VERSION ""

NS_ :

BS_:

BU_: Vector__XXX

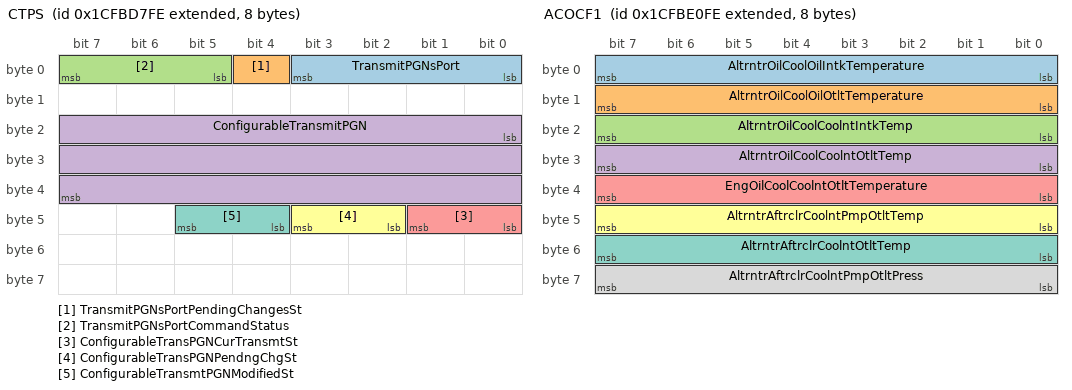
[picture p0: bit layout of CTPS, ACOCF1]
BO_ 2633750526 CTPS: 8 Vector__XXX
SG_ TransmitPGNsPort : 0|4@1+ (1,0) [0|15] "" Vector__XXX
SG_ TransmitPGNsPortPendingChangesSt : 4|1@1+ (1,0) [0|1] "" Vector__XXX
SG_ TransmitPGNsPortCommandStatus : 5|3@1+ (1,0) [0|7] "" Vector__XXX
SG_ ConfigurableTransmitPGN : 16|24@1+ (1,0) [0|16777215] "" Vector__XXX
SG_ ConfigurableTransPGNCurTransmtSt : 40|2@1+ (1,0) [0|3] "" Vector__XXX
SG_ ConfigurableTransPGNPendngChgSt : 42|2@1+ (1,0) [0|3] "" Vector__XXX
SG_ ConfigurableTransmtPGNModifiedSt : 44|2@1+ (1,0) [0|3] "" Vector__XXX

BO_ 2365315326 DCDC1T: 8 Vector__XXX
SG_ DCDC1ConverterTemperature : 0|8@1+ (1,-40) [-40|210] "deg C" Vector__XXX
SG_ DCDC1CnvElctrncFilterTemperature : 8|8@1+ (1,-40) [-40|210] "deg C" Vector__XXX
SG_ DCDC1PowerElectronicsTemperature : 16|8@1+ (1,-40) [-40|210] "deg C" Vector__XXX
SG_ DCDC1CoolantInTemperature : 24|8@1+ (1,-40) [-40|210] "deg C" Vector__XXX
SG_ DCDC1CoolantOutTemperature : 32|8@1+ (1,-40) [-40|210] "deg C" Vector__XXX

BO_ 2365315582 DCDC1LL: 8 Vector__XXX
SG_ DCDC1LowSideVoltageMinLmtRequest : 0|16@1+ (0.01,0) [0|642.55] "V" Vector__XXX
SG_ DCDC1LowSideVoltageMaxLmtRequest : 16|16@1+ (0.01,0) [0|642.55] "V" Vector__XXX
SG_ DCDC1LowSideCurrMaxLmtRequest : 32|16@1+ (0.05,0) [0|3212.75] "A" Vector__XXX

BO_ 2365315838 DCDC1HL: 8 Vector__XXX
SG_ DCDC1HghSideVoltageMinLmtRequest : 0|16@1+ (0.05,0) [0|3212.75] "V" Vector__XXX
SG_ DCDC1HghSideVoltageMaxLmtRequest : 16|16@1+ (0.05,0) [0|3212.75] "V" Vector__XXX
SG_ DCDC1HghSideCurrMaxLmtRequest : 32|16@1+ (0.05,0) [0|3212.75] "A" Vector__XXX

BO_ 2566642686 DM58: 0 Vector__XXX

BO_ 2566642942 DC4: 8 Vector__XXX
SG_ LockStatusOfDoor21 : 0|2@1+ (1,0) [0|3] "" Vector__XXX
SG_ OpenStatusOfDoor21 : 2|2@1+ (1,0) [0|3] "" Vector__XXX
SG_ EnableStatusOfDoor21 : 4|2@1+ (1,0) [0|3] "" Vector__XXX
SG_ LockStatusOfDoor22 : 6|2@1+ (1,0) [0|3] "" Vector__XXX
SG_ OpenStatusOfDoor22 : 8|2@1+ (1,0) [0|3] "" Vector__XXX
SG_ EnableStatusOfDoor22 : 10|2@1+ (1,0) [0|3] "" Vector__XXX
SG_ LockStatusOfDoor23 : 12|2@1+ (1,0) [0|3] "" Vector__XXX
SG_ OpenStatusOfDoor23 : 14|2@1+ (1,0) [0|3] "" Vector__XXX
SG_ EnableStatusOfDoor23 : 16|2@1+ (1,0) [0|3] "" Vector__XXX
SG_ LockStatusOfDoor24 : 18|2@1+ (1,0) [0|3] "" Vector__XXX
SG_ OpenStatusOfDoor24 : 20|2@1+ (1,0) [0|3] "" Vector__XXX
SG_ EnableStatusOfDoor24 : 22|2@1+ (1,0) [0|3] "" Vector__XXX
SG_ LockStatusOfDoor25 : 24|2@1+ (1,0) [0|3] "" Vector__XXX
SG_ OpenStatusOfDoor25 : 26|2@1+ (1,0) [0|3] "" Vector__XXX
SG_ EnableStatusOfDoor25 : 28|2@1+ (1,0) [0|3] "" Vector__XXX
SG_ LockStatusOfDoor26 : 30|2@1+ (1,0) [0|3] "" Vector__XXX
SG_ OpenStatusOfDoor26 : 32|2@1+ (1,0) [0|3] "" Vector__XXX
SG_ EnableStatusOfDoor26 : 34|2@1+ (1,0) [0|3] "" Vector__XXX
SG_ LockStatusOfDoor27 : 36|2@1+ (1,0) [0|3] "" Vector__XXX
SG_ OpenStatusOfDoor27 : 38|2@1+ (1,0) [0|3] "" Vector__XXX
SG_ EnableStatusOfDoor27 : 40|2@1+ (1,0) [0|3] "" Vector__XXX
SG_ LockStatusOfDoor28 : 42|2@1+ (1,0) [0|3] "" Vector__XXX
SG_ OpenStatusOfDoor28 : 44|2@1+ (1,0) [0|3] "" Vector__XXX
SG_ EnableStatusOfDoor28 : 46|2@1+ (1,0) [0|3] "" Vector__XXX
SG_ LockStatusOfDoor29 : 48|2@1+ (1,0) [0|3] "" Vector__XXX
SG_ OpenStatusOfDoor29 : 50|2@1+ (1,0) [0|3] "" Vector__XXX
SG_ EnableStatusOfDoor29 : 52|2@1+ (1,0) [0|3] "" Vector__XXX
SG_ LockStatusOfDoor30 : 54|2@1+ (1,0) [0|3] "" Vector__XXX
SG_ OpenStatusOfDoor30 : 56|2@1+ (1,0) [0|3] "" Vector__XXX
SG_ EnableStatusOfDoor30 : 58|2@1+ (1,0) [0|3] "" Vector__XXX

BO_ 2566643198 DC3: 8 Vector__XXX
SG_ LockStatusOfDoor11 : 0|2@1+ (1,0) [0|3] "" Vector__XXX
SG_ OpenStatusOfDoor11 : 2|2@1+ (1,0) [0|3] "" Vector__XXX
SG_ EnableStatusOfDoor11 : 4|2@1+ (1,0) [0|3] "" Vector__XXX
SG_ LockStatusOfDoor12 : 6|2@1+ (1,0) [0|3] "" Vector__XXX
SG_ OpenStatusOfDoor12 : 8|2@1+ (1,0) [0|3] "" Vector__XXX
SG_ EnableStatusOfDoor12 : 10|2@1+ (1,0) [0|3] "" Vector__XXX
SG_ LockStatusOfDoor13 : 12|2@1+ (1,0) [0|3] "" Vector__XXX
SG_ OpenStatusOfDoor13 : 14|2@1+ (1,0) [0|3] "" Vector__XXX
SG_ EnableStatusOfDoor13 : 16|2@1+ (1,0) [0|3] "" Vector__XXX
SG_ LockStatusOfDoor14 : 18|2@1+ (1,0) [0|3] "" Vector__XXX
SG_ OpenStatusOfDoor14 : 20|2@1+ (1,0) [0|3] "" Vector__XXX
SG_ EnableStatusOfDoor14 : 22|2@1+ (1,0) [0|3] "" Vector__XXX
SG_ LockStatusOfDoor15 : 24|2@1+ (1,0) [0|3] "" Vector__XXX
SG_ OpenStatusOfDoor15 : 26|2@1+ (1,0) [0|3] "" Vector__XXX
SG_ EnableStatusOfDoor15 : 28|2@1+ (1,0) [0|3] "" Vector__XXX
SG_ LockStatusOfDoor16 : 30|2@1+ (1,0) [0|3] "" Vector__XXX
SG_ OpenStatusOfDoor16 : 32|2@1+ (1,0) [0|3] "" Vector__XXX
SG_ EnableStatusOfDoor16 : 34|2@1+ (1,0) [0|3] "" Vector__XXX
SG_ LockStatusOfDoor17 : 36|2@1+ (1,0) [0|3] "" Vector__XXX
SG_ OpenStatusOfDoor17 : 38|2@1+ (1,0) [0|3] "" Vector__XXX
SG_ EnableStatusOfDoor17 : 40|2@1+ (1,0) [0|3] "" Vector__XXX
SG_ LockStatusOfDoor18 : 42|2@1+ (1,0) [0|3] "" Vector__XXX
SG_ OpenStatusOfDoor18 : 44|2@1+ (1,0) [0|3] "" Vector__XXX
SG_ EnableStatusOfDoor18 : 46|2@1+ (1,0) [0|3] "" Vector__XXX
SG_ LockStatusOfDoor19 : 48|2@1+ (1,0) [0|3] "" Vector__XXX
SG_ OpenStatusOfDoor19 : 50|2@1+ (1,0) [0|3] "" Vector__XXX
SG_ EnableStatusOfDoor19 : 52|2@1+ (1,0) [0|3] "" Vector__XXX
SG_ LockStatusOfDoor20 : 54|2@1+ (1,0) [0|3] "" Vector__XXX
SG_ OpenStatusOfDoor20 : 56|2@1+ (1,0) [0|3] "" Vector__XXX
SG_ EnableStatusOfDoor20 : 58|2@1+ (1,0) [0|3] "" Vector__XXX

BO_ 2566643454 ET6: 8 Vector__XXX
SG_ EngChrgAirCoolIntkCoolntTemp : 0|16@1+ (0.03125,-273) [-273|1734.96875] "deg C" Vector__XXX
SG_ EngChrgAirCoolOtltCoolntTemp : 16|16@1+ (0.03125,-273) [-273|1734.96875] "deg C" Vector__XXX
SG_ EngineIntakeCoolantTemperature : 32|16@1+ (0.03125,-273) [-273|1734.96875] "deg C" Vector__XXX

BO_ 2566643710 IC3: 8 Vector__XXX
SG_ EngineMixerIntakePressure : 0|16@1+ (0.1,0) [0|6425.5] "kPa" Vector__XXX
SG_ EngineMixer2IntakePressure : 16|16@1+ (0.1,0) [0|6425.5] "kPa" Vector__XXX

BO_ 2633752830 ACOCF1: 8 Vector__XXX
SG_ AltrntrOilCoolOilIntkTemperature : 0|8@1+ (1,-40) [-40|210] "deg C" Vector__XXX
SG_ AltrntrOilCoolOilOtltTemperature : 8|8@1+ (1,-40) [-40|210] "deg C" Vector__XXX
SG_ AltrntrOilCoolCoolntIntkTemp : 16|8@1+ (1,-40) [-40|210] "deg C" Vector__XXX
SG_ AltrntrOilCoolCoolntOtltTemp : 24|8@1+ (1,-40) [-40|210] "deg C" Vector__XXX
SG_ EngOilCoolCoolntOtltTemperature : 32|8@1+ (1,-40) [-40|210] "deg C" Vector__XXX
SG_ AltrntrAftrclrCoolntPmpOtltTemp : 40|8@1+ (1,-40) [-40|210] "deg C" Vector__XXX
SG_ AltrntrAftrclrCoolntOtltTemp : 48|8@1+ (1,-40) [-40|210] "deg C" Vector__XXX
SG_ AltrntrAftrclrCoolntPmpOtltPress : 56|8@1+ (2,0) [0|500] "kPa" Vector__XXX

BO_ 2633753086 DT2: 8 Vector__XXX
SG_ PowerRectifierDiode9Temperature : 0|8@1+ (1,-40) [-40|210] "deg C" Vector__XXX
SG_ PowerRectifierDiode10Temperature : 8|8@1+ (1,-40) [-40|210] "deg C" Vector__XXX
SG_ PowerRectifierDiode11Temperature : 16|8@1+ (1,-40) [-40|210] "deg C" Vector__XXX
SG_ PowerRectifierDiode12Temperature : 24|8@1+ (1,-40) [-40|210] "deg C" Vector__XXX

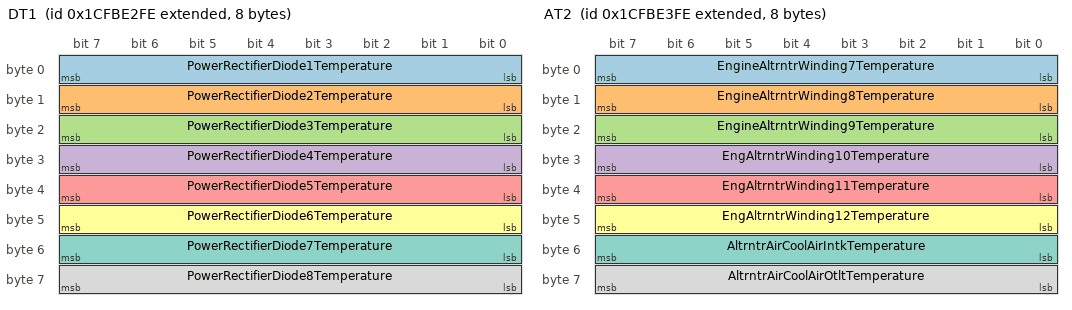
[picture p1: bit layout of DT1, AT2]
BO_ 2633753342 DT1: 8 Vector__XXX
SG_ PowerRectifierDiode1Temperature : 0|8@1+ (1,-40) [-40|210] "deg C" Vector__XXX
SG_ PowerRectifierDiode2Temperature : 8|8@1+ (1,-40) [-40|210] "deg C" Vector__XXX
SG_ PowerRectifierDiode3Temperature : 16|8@1+ (1,-40) [-40|210] "deg C" Vector__XXX
SG_ PowerRectifierDiode4Temperature : 24|8@1+ (1,-40) [-40|210] "deg C" Vector__XXX
SG_ PowerRectifierDiode5Temperature : 32|8@1+ (1,-40) [-40|210] "deg C" Vector__XXX
SG_ PowerRectifierDiode6Temperature : 40|8@1+ (1,-40) [-40|210] "deg C" Vector__XXX
SG_ PowerRectifierDiode7Temperature : 48|8@1+ (1,-40) [-40|210] "deg C" Vector__XXX
SG_ PowerRectifierDiode8Temperature : 56|8@1+ (1,-40) [-40|210] "deg C" Vector__XXX

BO_ 2633753598 AT2: 8 Vector__XXX
SG_ EngineAltrntrWinding7Temperature : 0|8@1+ (1,-40) [-40|210] "deg C" Vector__XXX
SG_ EngineAltrntrWinding8Temperature : 8|8@1+ (1,-40) [-40|210] "deg C" Vector__XXX
SG_ EngineAltrntrWinding9Temperature : 16|8@1+ (1,-40) [-40|210] "deg C" Vector__XXX
SG_ EngAltrntrWinding10Temperature : 24|8@1+ (1,-40) [-40|210] "deg C" Vector__XXX
SG_ EngAltrntrWinding11Temperature : 32|8@1+ (1,-40) [-40|210] "deg C" Vector__XXX
SG_ EngAltrntrWinding12Temperature : 40|8@1+ (1,-40) [-40|210] "deg C" Vector__XXX
SG_ AltrntrAirCoolAirIntkTemperature : 48|8@1+ (1,-40) [-40|210] "deg C" Vector__XXX
SG_ AltrntrAirCoolAirOtltTemperature : 56|8@1+ (1,-40) [-40|210] "deg C" Vector__XXX

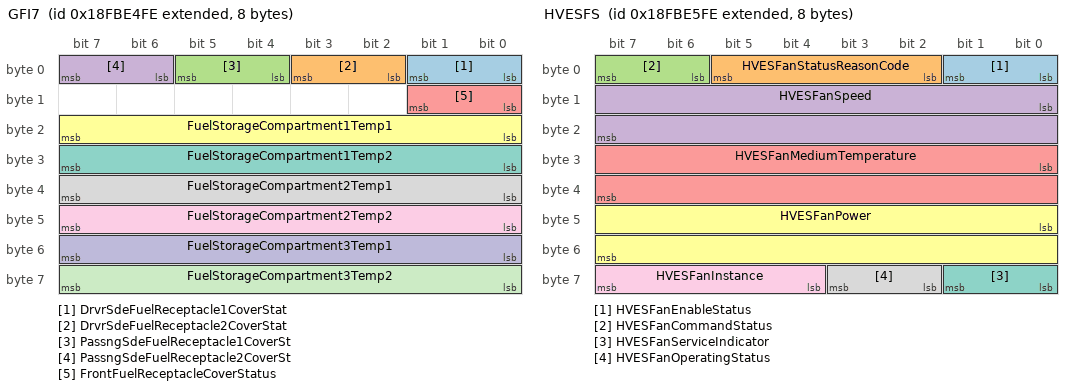
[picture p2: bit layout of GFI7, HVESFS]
BO_ 2566644990 GFI7: 8 Vector__XXX
SG_ DrvrSdeFuelReceptacle1CoverStat : 0|2@1+ (1,0) [0|3] "" Vector__XXX
SG_ DrvrSdeFuelReceptacle2CoverStat : 2|2@1+ (1,0) [0|3] "" Vector__XXX
SG_ PassngSdeFuelReceptacle1CoverSt : 4|2@1+ (1,0) [0|3] "" Vector__XXX
SG_ PassngSdeFuelReceptacle2CoverSt : 6|2@1+ (1,0) [0|3] "" Vector__XXX
SG_ FrontFuelReceptacleCoverStatus : 8|2@1+ (1,0) [0|3] "" Vector__XXX
SG_ FuelStorageCompartment1Temp1 : 16|8@1+ (1,-40) [-40|210] "deg C" Vector__XXX
SG_ FuelStorageCompartment1Temp2 : 24|8@1+ (1,-40) [-40|210] "deg C" Vector__XXX
SG_ FuelStorageCompartment2Temp1 : 32|8@1+ (1,-40) [-40|210] "deg C" Vector__XXX
SG_ FuelStorageCompartment2Temp2 : 40|8@1+ (1,-40) [-40|210] "deg C" Vector__XXX
SG_ FuelStorageCompartment3Temp1 : 48|8@1+ (1,-40) [-40|210] "deg C" Vector__XXX
SG_ FuelStorageCompartment3Temp2 : 56|8@1+ (1,-40) [-40|210] "deg C" Vector__XXX

BO_ 2566645246 HVESFS: 8 Vector__XXX
SG_ HVESFanEnableStatus : 0|2@1+ (1,0) [0|3] "" Vector__XXX
SG_ HVESFanStatusReasonCode : 2|4@1+ (1,0) [0|15] "" Vector__XXX
SG_ HVESFanCommandStatus : 6|2@1+ (1,0) [0|3] "" Vector__XXX
SG_ HVESFanSpeed : 8|16@1+ (0.5,0) [0|32127.5] "rpm" Vector__XXX
SG_ HVESFanMediumTemperature : 24|16@1+ (0.03125,-273) [-273|1734.96875] "deg C" Vector__XXX
SG_ HVESFanPower : 40|16@1+ (0.5,0) [0|32127.5] "W" Vector__XXX
SG_ HVESFanServiceIndicator : 56|2@1+ (1,0) [0|3] "" Vector__XXX
SG_ HVESFanOperatingStatus : 58|2@1+ (1,0) [0|3] "" Vector__XXX
SG_ HVESFanInstance : 60|4@1+ (1,0) [0|15] "" Vector__XXX

BO_ 2365318910 HVESFC: 8 Vector__XXX
SG_ HVESFanEnableCommand : 0|2@1+ (1,0) [0|3] "" Vector__XXX
SG_ HVESFanPowerHold : 2|2@1+ (1,0) [0|3] "" Vector__XXX
SG_ HVESFanSpeedCommand : 8|16@1+ (0.5,0) [0|32127.5] "rpm" Vector__XXX
SG_ HVESFanPercentSpeedCommand : 24|8@1+ (0.4,0) [0|100] "%" Vector__XXX
SG_ HVESFanInstance1 : 32|1@1+ (1,0) [0|1] "" Vector__XXX
SG_ HVESFanInstance2 : 33|1@1+ (1,0) [0|1] "" Vector__XXX
SG_ HVESFanInstance3 : 34|1@1+ (1,0) [0|1] "" Vector__XXX
SG_ HVESFanInstance4 : 35|1@1+ (1,0) [0|1] "" Vector__XXX
SG_ HVESFanInstance5 : 36|1@1+ (1,0) [0|1] "" Vector__XXX
SG_ HVESFanInstance6 : 37|1@1+ (1,0) [0|1] "" Vector__XXX
SG_ HVESFanInstance7 : 38|1@1+ (1,0) [0|1] "" Vector__XXX
SG_ HVESFanInstance8 : 39|1@1+ (1,0) [0|1] "" Vector__XXX
SG_ HVESFanInstance9 : 40|1@1+ (1,0) [0|1] "" Vector__XXX
SG_ HVESFanInstance10 : 41|1@1+ (1,0) [0|1] "" Vector__XXX
SG_ HVESFanInstance11 : 42|1@1+ (1,0) [0|1] "" Vector__XXX
SG_ HVESFanInstance12 : 43|1@1+ (1,0) [0|1] "" Vector__XXX
SG_ HVESFanInstance13 : 44|1@1+ (1,0) [0|1] "" Vector__XXX
SG_ HVESFanInstance14 : 45|1@1+ (1,0) [0|1] "" Vector__XXX
SG_ HVESFanInstance15 : 46|1@1+ (1,0) [0|1] "" Vector__XXX

BO_ 2633754622 SCROII5: 8 Vector__XXX
SG_ Aftrtrtmnt1SCRIntkHghTempTime : 0|32@1+ (1,0) [0|4211081215] "s" Vector__XXX

BO_ 2633754878 ASI2: 8 Vector__XXX
SG_ AftrtrtmntTotalDslExhstFluidUsed : 0|32@1+ (0.5,0) [0|2105540607.5] "l" Vector__XXX

BO_ 2633755134 E1NET2: 100 Vector__XXX
SG_ HostName : 7|800@0+ (1,0) [0|0] "ASCII" Vector__XXX

BO_ 2633755390 E1NET1: 19 Vector__XXX
SG_ DHCPStatus : 0|4@1+ (1,0) [0|15] "" Vector__XXX
SG_ EthernetLinkStatus : 4|2@1+ (1,0) [0|3] "" Vector__XXX
SG_ IPv4AddressOctet1 : 8|8@1+ (1,0) [0|255] "" Vector__XXX
SG_ IPv4AddressOctet2 : 16|8@1+ (1,0) [0|255] "" Vector__XXX
SG_ IPv4AddressOctet3 : 24|8@1+ (1,0) [0|255] "" Vector__XXX
SG_ IPv4AddressOctet4 : 32|8@1+ (1,0) [0|255] "" Vector__XXX
SG_ SubnetMaskOctet1 : 40|8@1+ (1,0) [0|255] "" Vector__XXX
SG_ SubnetMaskOctet2 : 48|8@1+ (1,0) [0|255] "" Vector__XXX
SG_ SubnetMaskOctet3 : 56|8@1+ (1,0) [0|255] "" Vector__XXX
SG_ SubnetMaskOctet4 : 64|8@1+ (1,0) [0|255] "" Vector__XXX
SG_ DefaultGatewayOctet1 : 72|8@1+ (1,0) [0|255] "" Vector__XXX
SG_ DefaultGatewayOctet2 : 80|8@1+ (1,0) [0|255] "" Vector__XXX
SG_ DefaultGatewayOctet3 : 88|8@1+ (1,0) [0|255] "" Vector__XXX
SG_ DefaultGatewayOctet4 : 96|8@1+ (1,0) [0|255] "" Vector__XXX
SG_ MACAddressOctet1 : 104|8@1+ (1,0) [0|255] "" Vector__XXX
SG_ MACAddressOctet2 : 112|8@1+ (1,0) [0|255] "" Vector__XXX
SG_ MACAddressOctet3 : 120|8@1+ (1,0) [0|255] "" Vector__XXX
SG_ MACAddressOctet4 : 128|8@1+ (1,0) [0|255] "" Vector__XXX
SG_ MACAddressOctet5 : 136|8@1+ (1,0) [0|255] "" Vector__XXX
SG_ MACAddressOctet6 : 144|8@1+ (1,0) [0|255] "" Vector__XXX

BO_ 2566646782 ODMCF1_2: 8 Vector__XXX
SG_ OilDebrisMontFerrsBins12IdNo : 0|8@1+ (1,0) [0|250] "" Vector__XXX
SG_ OilDebrisMonitorFerrousBin1Count : 8|24@1+ (1,0) [0|16449535] "" Vector__XXX
SG_ OilDebrisMonitorFerrousBin2Count : 32|24@1+ (1,0) [0|16449535] "" Vector__XXX

BO_ 2566647038 ODMCF3_4: 8 Vector__XXX
SG_ OilDebrisMontFerrsBins34IdNo : 0|8@1+ (1,0) [0|250] "" Vector__XXX
SG_ OilDebrisMonitorFerrousBin3Count : 8|24@1+ (1,0) [0|16449535] "" Vector__XXX
SG_ OilDebrisMonitorFerrousBin4Count : 32|24@1+ (1,0) [0|16449535] "" Vector__XXX

BO_ 2566647294 ODMCF5_6: 8 Vector__XXX
SG_ OilDebrisMontFerrsBins56IdNo : 0|8@1+ (1,0) [0|250] "" Vector__XXX
SG_ OilDebrisMonitorFerrousBin5Count : 8|24@1+ (1,0) [0|16449535] "" Vector__XXX
SG_ OilDebrisMonitorFerrousBin6Count : 32|24@1+ (1,0) [0|16449535] "" Vector__XXX

BO_ 2566647550 ODMCNF1_2: 8 Vector__XXX
SG_ OilDebrisMontNFerrsBins12IdNo : 0|8@1+ (1,0) [0|250] "" Vector__XXX
SG_ OilDebrisMonitorNonFerrsBin1Cnt : 8|24@1+ (1,0) [0|16449535] "" Vector__XXX
SG_ OilDebrisMonitorNonFerrsBin2Cnt : 32|24@1+ (1,0) [0|16449535] "" Vector__XXX

BO_ 2566647806 ODMCNF3_4: 8 Vector__XXX
SG_ OilDebrisMontNFerrsBins34IdNo : 0|8@1+ (1,0) [0|250] "" Vector__XXX
SG_ OilDebrisMonitorNonFerrsBin3Cnt : 8|24@1+ (1,0) [0|16449535] "" Vector__XXX
SG_ OilDebrisMonitorNonFerrsBin4Cnt : 32|24@1+ (1,0) [0|16449535] "" Vector__XXX

BO_ 2566648062 ODMCNF5_6: 8 Vector__XXX
SG_ OilDebrisMontNFerrsBins56IdNo : 0|8@1+ (1,0) [0|250] "" Vector__XXX
SG_ OilDebrisMonitorNonFerrsBin5Cnt : 8|24@1+ (1,0) [0|16449535] "" Vector__XXX
SG_ OilDebrisMonitorNonFerrsBin6Cnt : 32|24@1+ (1,0) [0|16449535] "" Vector__XXX

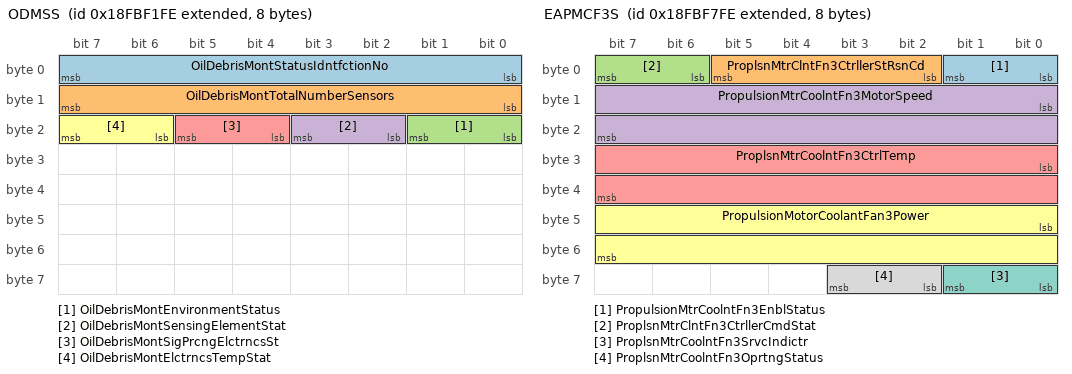
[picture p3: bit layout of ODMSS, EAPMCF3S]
BO_ 2566648318 ODMSS: 8 Vector__XXX
SG_ OilDebrisMontStatusIdntfctionNo : 0|8@1+ (1,0) [0|250] "" Vector__XXX
SG_ OilDebrisMontTotalNumberSensors : 8|8@1+ (1,0) [0|250] "" Vector__XXX
SG_ OilDebrisMontEnvironmentStatus : 16|2@1+ (1,0) [0|3] "" Vector__XXX
SG_ OilDebrisMontSensingElementStat : 18|2@1+ (1,0) [0|3] "" Vector__XXX
SG_ OilDebrisMontSigPrcngElctrncsSt : 20|2@1+ (1,0) [0|3] "" Vector__XXX
SG_ OilDebrisMontElctrncsTempStat : 22|2@1+ (1,0) [0|3] "" Vector__XXX

BO_ 2365322238 CCVS5: 8 Vector__XXX
SG_ DirectionalVehicleSpeed : 0|16@1+ (0.0078125,-250) [-250|251.992] "km/h" Vector__XXX

BO_ 2566649086 A2DOC2: 8 Vector__XXX
SG_ Aft2DslOxidtnCtlystIntkPress : 0|16@1+ (0.1,0) [0|6425.5] "kPa" Vector__XXX
SG_ Aft2DslOxidtnCtlystOtltPress : 16|16@1+ (0.1,0) [0|6425.5] "kPa" Vector__XXX
SG_ Aft2DOCInletToDPFOtltDeltaPress : 32|16@1+ (0.1,0) [0|6425.5] "kPa" Vector__XXX

BO_ 2566649342 A1DOC2: 8 Vector__XXX
SG_ Aft1DslOxidtnCtlystIntkPress : 0|16@1+ (0.1,0) [0|6425.5] "kPa" Vector__XXX
SG_ Aft1DslOxidtnCtlystOtltPress : 16|16@1+ (0.1,0) [0|6425.5] "kPa" Vector__XXX
SG_ Aft1DOCInletToDPFOtltDeltaPress : 32|16@1+ (0.1,0) [0|6425.5] "kPa" Vector__XXX

BO_ 2566649598 VP2: 8 Vector__XXX
SG_ TotalNumberOfSatellitesInView : 0|8@1+ (1,0) [0|250] "" Vector__XXX
SG_ HorizontalDilutionOfPrecision : 8|8@1+ (0.1,0) [0|25] "" Vector__XXX
SG_ VerticalDilutionOfPrecision : 16|8@1+ (0.1,0) [0|25] "" Vector__XXX
SG_ PositionDilutionOfPrecision : 24|8@1+ (0.1,0) [0|25] "" Vector__XXX
SG_ TimeDilutionOfPrecision : 32|8@1+ (0.1,0) [0|25] "" Vector__XXX

BO_ 2566649854 EAPMCF3S: 8 Vector__XXX
SG_ PropulsionMtrCoolntFn3EnblStatus : 0|2@1+ (1,0) [0|3] "" Vector__XXX
SG_ ProplsnMtrClntFn3CtrllerStRsnCd : 2|4@1+ (1,0) [0|15] "" Vector__XXX
SG_ ProplsnMtrClntFn3CtrllerCmdStat : 6|2@1+ (1,0) [0|3] "" Vector__XXX
SG_ PropulsionMtrCoolntFn3MotorSpeed : 8|16@1+ (0.5,0) [0|32127.5] "rpm" Vector__XXX
SG_ ProplsnMtrCoolntFn3CtrlTemp : 24|16@1+ (0.03125,-273) [-273|1734.96875] "deg C" Vector__XXX
SG_ PropulsionMotorCoolantFan3Power : 40|16@1+ (0.5,0) [0|32127.5] "W" Vector__XXX
SG_ ProplsnMtrCoolntFn3SrvcIndictr : 56|2@1+ (1,0) [0|3] "" Vector__XXX
SG_ ProplsnMtrCoolntFn3OprtngStatus : 58|2@1+ (1,0) [0|3] "" Vector__XXX

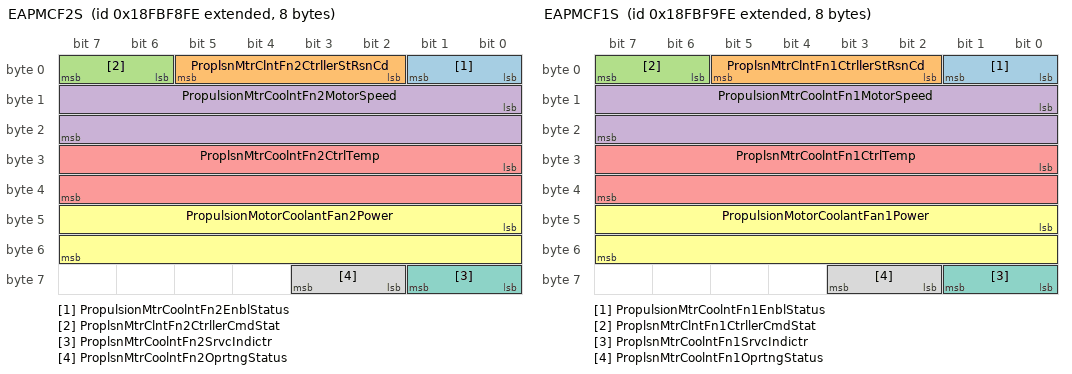
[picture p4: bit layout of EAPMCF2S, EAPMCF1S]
BO_ 2566650110 EAPMCF2S: 8 Vector__XXX
SG_ PropulsionMtrCoolntFn2EnblStatus : 0|2@1+ (1,0) [0|3] "" Vector__XXX
SG_ ProplsnMtrClntFn2CtrllerStRsnCd : 2|4@1+ (1,0) [0|15] "" Vector__XXX
SG_ ProplsnMtrClntFn2CtrllerCmdStat : 6|2@1+ (1,0) [0|3] "" Vector__XXX
SG_ PropulsionMtrCoolntFn2MotorSpeed : 8|16@1+ (0.5,0) [0|32127.5] "rpm" Vector__XXX
SG_ ProplsnMtrCoolntFn2CtrlTemp : 24|16@1+ (0.03125,-273) [-273|1734.96875] "deg C" Vector__XXX
SG_ PropulsionMotorCoolantFan2Power : 40|16@1+ (0.5,0) [0|32127.5] "W" Vector__XXX
SG_ ProplsnMtrCoolntFn2SrvcIndictr : 56|2@1+ (1,0) [0|3] "" Vector__XXX
SG_ ProplsnMtrCoolntFn2OprtngStatus : 58|2@1+ (1,0) [0|3] "" Vector__XXX

BO_ 2566650366 EAPMCF1S: 8 Vector__XXX
SG_ PropulsionMtrCoolntFn1EnblStatus : 0|2@1+ (1,0) [0|3] "" Vector__XXX
SG_ ProplsnMtrClntFn1CtrllerStRsnCd : 2|4@1+ (1,0) [0|15] "" Vector__XXX
SG_ ProplsnMtrClntFn1CtrllerCmdStat : 6|2@1+ (1,0) [0|3] "" Vector__XXX
SG_ PropulsionMtrCoolntFn1MotorSpeed : 8|16@1+ (0.5,0) [0|32127.5] "rpm" Vector__XXX
SG_ ProplsnMtrCoolntFn1CtrlTemp : 24|16@1+ (0.03125,-273) [-273|1734.96875] "deg C" Vector__XXX
SG_ PropulsionMotorCoolantFan1Power : 40|16@1+ (0.5,0) [0|32127.5] "W" Vector__XXX
SG_ ProplsnMtrCoolntFn1SrvcIndictr : 56|2@1+ (1,0) [0|3] "" Vector__XXX
SG_ ProplsnMtrCoolntFn1OprtngStatus : 58|2@1+ (1,0) [0|3] "" Vector__XXX

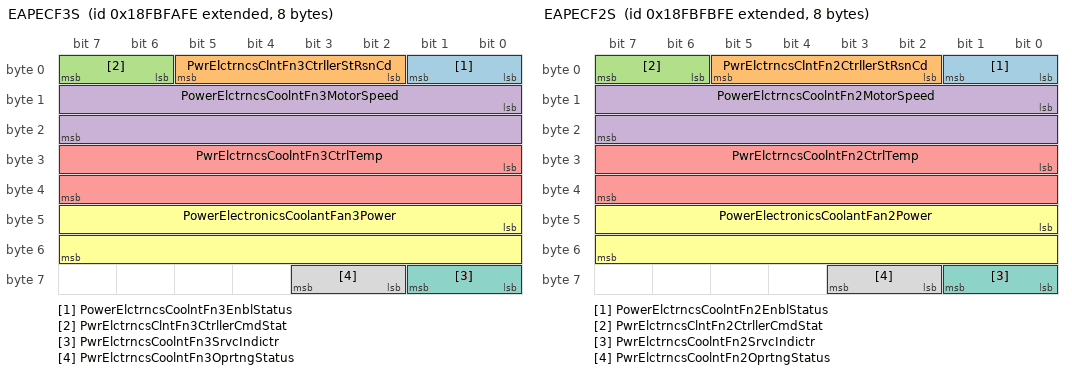
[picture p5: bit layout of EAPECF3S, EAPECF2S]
BO_ 2566650622 EAPECF3S: 8 Vector__XXX
SG_ PowerElctrncsCoolntFn3EnblStatus : 0|2@1+ (1,0) [0|3] "" Vector__XXX
SG_ PwrElctrncsClntFn3CtrllerStRsnCd : 2|4@1+ (1,0) [0|15] "" Vector__XXX
SG_ PwrElctrncsClntFn3CtrllerCmdStat : 6|2@1+ (1,0) [0|3] "" Vector__XXX
SG_ PowerElctrncsCoolntFn3MotorSpeed : 8|16@1+ (0.5,0) [0|32127.5] "rpm" Vector__XXX
SG_ PwrElctrncsCoolntFn3CtrlTemp : 24|16@1+ (0.03125,-273) [-273|1734.96875] "deg C" Vector__XXX
SG_ PowerElectronicsCoolantFan3Power : 40|16@1+ (0.5,0) [0|32127.5] "W" Vector__XXX
SG_ PwrElctrncsCoolntFn3SrvcIndictr : 56|2@1+ (1,0) [0|3] "" Vector__XXX
SG_ PwrElctrncsCoolntFn3OprtngStatus : 58|2@1+ (1,0) [0|3] "" Vector__XXX

BO_ 2566650878 EAPECF2S: 8 Vector__XXX
SG_ PowerElctrncsCoolntFn2EnblStatus : 0|2@1+ (1,0) [0|3] "" Vector__XXX
SG_ PwrElctrncsClntFn2CtrllerStRsnCd : 2|4@1+ (1,0) [0|15] "" Vector__XXX
SG_ PwrElctrncsClntFn2CtrllerCmdStat : 6|2@1+ (1,0) [0|3] "" Vector__XXX
SG_ PowerElctrncsCoolntFn2MotorSpeed : 8|16@1+ (0.5,0) [0|32127.5] "rpm" Vector__XXX
SG_ PwrElctrncsCoolntFn2CtrlTemp : 24|16@1+ (0.03125,-273) [-273|1734.96875] "deg C" Vector__XXX
SG_ PowerElectronicsCoolantFan2Power : 40|16@1+ (0.5,0) [0|32127.5] "W" Vector__XXX
SG_ PwrElctrncsCoolntFn2SrvcIndictr : 56|2@1+ (1,0) [0|3] "" Vector__XXX
SG_ PwrElctrncsCoolntFn2OprtngStatus : 58|2@1+ (1,0) [0|3] "" Vector__XXX

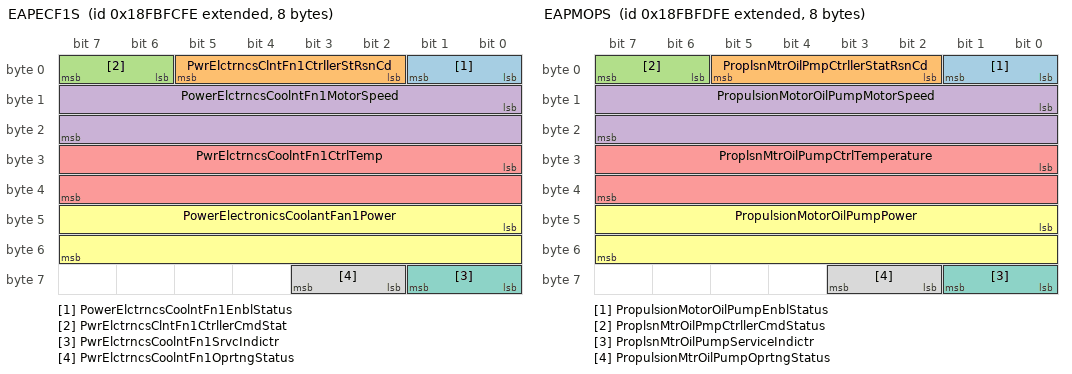
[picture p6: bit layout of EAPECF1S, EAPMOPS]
BO_ 2566651134 EAPECF1S: 8 Vector__XXX
SG_ PowerElctrncsCoolntFn1EnblStatus : 0|2@1+ (1,0) [0|3] "" Vector__XXX
SG_ PwrElctrncsClntFn1CtrllerStRsnCd : 2|4@1+ (1,0) [0|15] "" Vector__XXX
SG_ PwrElctrncsClntFn1CtrllerCmdStat : 6|2@1+ (1,0) [0|3] "" Vector__XXX
SG_ PowerElctrncsCoolntFn1MotorSpeed : 8|16@1+ (0.5,0) [0|32127.5] "rpm" Vector__XXX
SG_ PwrElctrncsCoolntFn1CtrlTemp : 24|16@1+ (0.03125,-273) [-273|1734.96875] "deg C" Vector__XXX
SG_ PowerElectronicsCoolantFan1Power : 40|16@1+ (0.5,0) [0|32127.5] "W" Vector__XXX
SG_ PwrElctrncsCoolntFn1SrvcIndictr : 56|2@1+ (1,0) [0|3] "" Vector__XXX
SG_ PwrElctrncsCoolntFn1OprtngStatus : 58|2@1+ (1,0) [0|3] "" Vector__XXX

BO_ 2566651390 EAPMOPS: 8 Vector__XXX
SG_ PropulsionMotorOilPumpEnblStatus : 0|2@1+ (1,0) [0|3] "" Vector__XXX
SG_ ProplsnMtrOilPmpCtrllerStatRsnCd : 2|4@1+ (1,0) [0|15] "" Vector__XXX
SG_ ProplsnMtrOilPmpCtrllerCmdStatus : 6|2@1+ (1,0) [0|3] "" Vector__XXX
SG_ PropulsionMotorOilPumpMotorSpeed : 8|16@1+ (0.5,0) [0|32127.5] "rpm" Vector__XXX
SG_ ProplsnMtrOilPumpCtrlTemperature : 24|16@1+ (0.03125,-273) [-273|1734.96875] "deg C" Vector__XXX
SG_ PropulsionMotorOilPumpPower : 40|16@1+ (0.5,0) [0|32127.5] "W" Vector__XXX
SG_ ProplsnMtrOilPumpServiceIndictr : 56|2@1+ (1,0) [0|3] "" Vector__XXX
SG_ PropulsionMtrOilPumpOprtngStatus : 58|2@1+ (1,0) [0|3] "" Vector__XXX

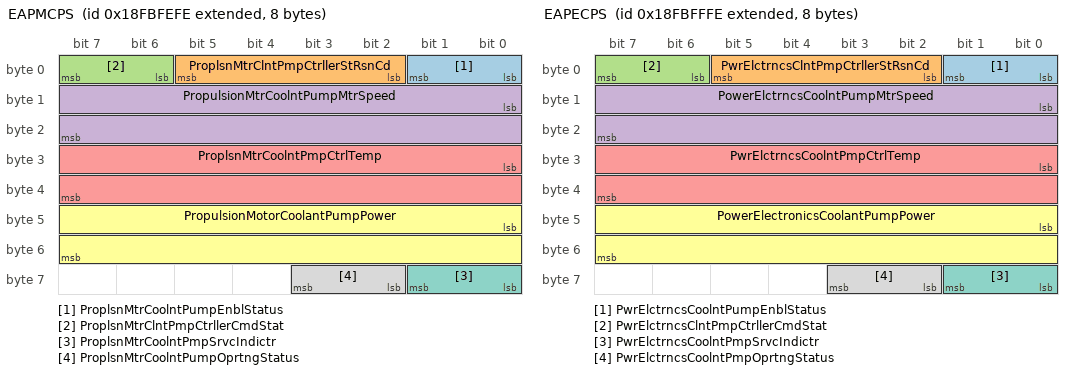
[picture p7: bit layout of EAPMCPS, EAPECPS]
BO_ 2566651646 EAPMCPS: 8 Vector__XXX
SG_ ProplsnMtrCoolntPumpEnblStatus : 0|2@1+ (1,0) [0|3] "" Vector__XXX
SG_ ProplsnMtrClntPmpCtrllerStRsnCd : 2|4@1+ (1,0) [0|15] "" Vector__XXX
SG_ ProplsnMtrClntPmpCtrllerCmdStat : 6|2@1+ (1,0) [0|3] "" Vector__XXX
SG_ PropulsionMtrCoolntPumpMtrSpeed : 8|16@1+ (0.5,0) [0|32127.5] "rpm" Vector__XXX
SG_ ProplsnMtrCoolntPmpCtrlTemp : 24|16@1+ (0.03125,-273) [-273|1734.96875] "deg C" Vector__XXX
SG_ PropulsionMotorCoolantPumpPower : 40|16@1+ (0.5,0) [0|32127.5] "W" Vector__XXX
SG_ ProplsnMtrCoolntPmpSrvcIndictr : 56|2@1+ (1,0) [0|3] "" Vector__XXX
SG_ ProplsnMtrCoolntPumpOprtngStatus : 58|2@1+ (1,0) [0|3] "" Vector__XXX

BO_ 2566651902 EAPECPS: 8 Vector__XXX
SG_ PwrElctrncsCoolntPumpEnblStatus : 0|2@1+ (1,0) [0|3] "" Vector__XXX
SG_ PwrElctrncsClntPmpCtrllerStRsnCd : 2|4@1+ (1,0) [0|15] "" Vector__XXX
SG_ PwrElctrncsClntPmpCtrllerCmdStat : 6|2@1+ (1,0) [0|3] "" Vector__XXX
SG_ PowerElctrncsCoolntPumpMtrSpeed : 8|16@1+ (0.5,0) [0|32127.5] "rpm" Vector__XXX
SG_ PwrElctrncsCoolntPmpCtrlTemp : 24|16@1+ (0.03125,-273) [-273|1734.96875] "deg C" Vector__XXX
SG_ PowerElectronicsCoolantPumpPower : 40|16@1+ (0.5,0) [0|32127.5] "W" Vector__XXX
SG_ PwrElctrncsCoolntPmpSrvcIndictr : 56|2@1+ (1,0) [0|3] "" Vector__XXX
SG_ PwrElctrncsCoolntPmpOprtngStatus : 58|2@1+ (1,0) [0|3] "" Vector__XXX

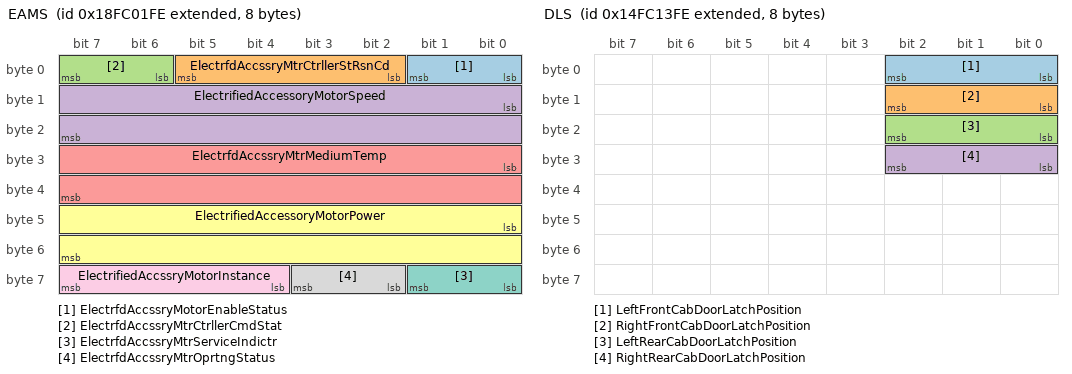
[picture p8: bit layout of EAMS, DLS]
BO_ 2566652414 EAMS: 8 Vector__XXX
SG_ ElectrfdAccssryMotorEnableStatus : 0|2@1+ (1,0) [0|3] "" Vector__XXX
SG_ ElectrfdAccssryMtrCtrllerStRsnCd : 2|4@1+ (1,0) [0|15] "" Vector__XXX
SG_ ElectrfdAccssryMtrCtrllerCmdStat : 6|2@1+ (1,0) [0|3] "" Vector__XXX
SG_ ElectrifiedAccessoryMotorSpeed : 8|16@1+ (0.5,0) [0|32127.5] "rpm" Vector__XXX
SG_ ElectrfdAccssryMtrMediumTemp : 24|16@1+ (0.03125,-273) [-273|1734.96875] "deg C" Vector__XXX
SG_ ElectrifiedAccessoryMotorPower : 40|16@1+ (0.5,0) [0|32127.5] "W" Vector__XXX
SG_ ElectrfdAccssryMtrServiceIndictr : 56|2@1+ (1,0) [0|3] "" Vector__XXX
SG_ ElectrfdAccssryMtrOprtngStatus : 58|2@1+ (1,0) [0|3] "" Vector__XXX
SG_ ElectrifiedAccssryMotorInstance : 60|4@1+ (1,0) [0|15] "" Vector__XXX

BO_ 2566652670 SCRSI: 8 Vector__XXX
SG_ DieselExhaustFluidFrozenTime : 0|32@1+ (1,0) [0|4211081215] "s" Vector__XXX
SG_ Aftrtrtmnt1SCRSystemHydrocarbon : 32|8@1+ (1,0) [0|250] "%" Vector__XXX
SG_ Aft1DslExhstFldDsngSysFrozen : 40|2@1+ (1,0) [0|3] "" Vector__XXX
SG_ Aft2DslExhstFldDsngSysFrozen : 42|2@1+ (1,0) [0|3] "" Vector__XXX

BO_ 2566652926 VEP14: 8 Vector__XXX
SG_ SLIBattryPack1Battry4StateCharge : 0|16@1+ (0.0025,0) [0|160.6375] "%" Vector__XXX
SG_ SLIBatteryPack1Battery4Capacity : 16|16@1+ (1,0) [0|64255] "Ah" Vector__XXX
SG_ SLIBatteryPack1Battery4Health : 32|8@1+ (0.5,0) [0|125] "%" Vector__XXX
SG_ SLIBattPack1Batt4PrdctMnCrnkVltg : 40|8@1+ (0.2,0) [0|50] "V" Vector__XXX
SG_ SLIBattryPack1Sensor4InitStatus : 48|4@1+ (1,0) [0|15] "" Vector__XXX

BO_ 2566653182 VEP13: 8 Vector__XXX
SG_ SLIBattryPack1Battery4NetCurrent : 0|16@1+ (0.05,-1600) [-1600|1612.75] "A" Vector__XXX
SG_ SLIBattryPack1Battry4Temperature : 16|8@1+ (1,-40) [-40|210] "deg C" Vector__XXX
SG_ SLIBatteryPack1Battery4Voltage : 24|16@1+ (0.05,0) [0|3212.75] "V" Vector__XXX

BO_ 2566653438 VEP12: 8 Vector__XXX
SG_ SLIBattryPack1Battry3StateCharge : 0|16@1+ (0.0025,0) [0|160.6375] "%" Vector__XXX
SG_ SLIBatteryPack1Battery3Capacity : 16|16@1+ (1,0) [0|64255] "Ah" Vector__XXX
SG_ SLIBatteryPack1Battery3Health : 32|8@1+ (0.5,0) [0|125] "%" Vector__XXX
SG_ SLIBattPack1Batt3PrdctMnCrnkVltg : 40|8@1+ (0.2,0) [0|50] "V" Vector__XXX
SG_ SLIBattryPack1Sensor3InitStatus : 48|4@1+ (1,0) [0|15] "" Vector__XXX

BO_ 2566653694 VEP11: 8 Vector__XXX
SG_ SLIBattryPack1Battery3NetCurrent : 0|16@1+ (0.05,-1600) [-1600|1612.75] "A" Vector__XXX
SG_ SLIBattryPack1Battry3Temperature : 16|8@1+ (1,-40) [-40|210] "deg C" Vector__XXX
SG_ SLIBatteryPack1Battery3Voltage : 24|16@1+ (0.05,0) [0|3212.75] "V" Vector__XXX

BO_ 2566653950 VEP10: 8 Vector__XXX
SG_ SLIBattryPack1Battry2StateCharge : 0|16@1+ (0.0025,0) [0|160.6375] "%" Vector__XXX
SG_ SLIBatteryPack1Battery2Capacity : 16|16@1+ (1,0) [0|64255] "Ah" Vector__XXX
SG_ SLIBatteryPack1Battery2Health : 32|8@1+ (0.5,0) [0|125] "%" Vector__XXX
SG_ SLIBattPack1Batt2PrdctMnCrnkVltg : 40|8@1+ (0.2,0) [0|50] "V" Vector__XXX
SG_ SLIBattryPack1Sensor2InitStatus : 48|4@1+ (1,0) [0|15] "" Vector__XXX

BO_ 2566654206 VEP9: 8 Vector__XXX
SG_ SLIBattryPack1Battery2NetCurrent : 0|16@1+ (0.05,-1600) [-1600|1612.75] "A" Vector__XXX
SG_ SLIBattryPack1Battry2Temperature : 16|8@1+ (1,-40) [-40|210] "deg C" Vector__XXX
SG_ SLIBatteryPack1Battery2Voltage : 24|16@1+ (0.05,0) [0|3212.75] "V" Vector__XXX

BO_ 2566654462 VEP8: 8 Vector__XXX
SG_ SLIBattryPack1Battry1StateCharge : 0|16@1+ (0.0025,0) [0|160.6375] "%" Vector__XXX
SG_ SLIBatteryPack1Battery1Capacity : 16|16@1+ (1,0) [0|64255] "Ah" Vector__XXX
SG_ SLIBatteryPack1Battery1Health : 32|8@1+ (0.5,0) [0|125] "%" Vector__XXX
SG_ SLIBattPack1Batt1PrdctMnCrnkVltg : 40|8@1+ (0.2,0) [0|50] "V" Vector__XXX
SG_ SLIBattryPack1Sensor1InitStatus : 48|4@1+ (1,0) [0|15] "" Vector__XXX

BO_ 2566654718 VEP7: 8 Vector__XXX
SG_ SLIBattryPack1Battery1NetCurrent : 0|16@1+ (0.05,-1600) [-1600|1612.75] "A" Vector__XXX
SG_ SLIBattryPack1Battry1Temperature : 16|8@1+ (1,-40) [-40|210] "deg C" Vector__XXX
SG_ SLIBatteryPack1Battery1Voltage : 24|16@1+ (0.05,0) [0|3212.75] "V" Vector__XXX

BO_ 2566654974 EEC20: 8 Vector__XXX
SG_ EstEngParasiticLossesPrcntTorque : 0|16@1+ (0.0015625,0) [0|100.3984375] "%" Vector__XXX
SG_ ActlMaximumAvailEngPercentFuel : 16|8@1+ (0.4,0) [0|100] "%" Vector__XXX

BO_ 2633764094 EVAP: 8 Vector__XXX
SG_ CanisterVentValve : 0|2@1+ (1,0) [0|3] "" Vector__XXX
SG_ CanisterPurgeValveCommand : 8|8@1+ (0.4,0) [0|100] "%" Vector__XXX
SG_ GasolineFuelTankPressure : 16|16@1+ (0.1,-3212.7) [-3212.7|3212.8] "kPa" Vector__XXX

BO_ 2633764350 FPS1: 8 Vector__XXX
SG_ FirePumpOperationTime : 0|32@1+ (1,0) [0|4211081215] "s" Vector__XXX
SG_ FirePumpEngagementCycles : 32|16@1+ (1,0) [0|64255] "" Vector__XXX

BO_ 2566655742 PHRPS: 8 Vector__XXX
SG_ RearHitchRollSensitivity : 0|8@1+ (0.4,0) [0|100] "%" Vector__XXX
SG_ RearHitchPitchSensitivity : 8|8@1+ (0.4,0) [0|100] "%" Vector__XXX

BO_ 2566655998 SHRPS: 8 Vector__XXX
SG_ FrontHitchRollSensitivity : 0|8@1+ (0.4,0) [0|100] "%" Vector__XXX
SG_ FrontHitchPitchSensitivity : 8|8@1+ (0.4,0) [0|100] "%" Vector__XXX

BO_ 2566656254 AMB3: 8 Vector__XXX
SG_ BarometricAbsolutePressure2 : 0|16@1+ (0.1,0) [0|6425.5] "kPa" Vector__XXX
SG_ EngineIntake2AirTemperature : 16|8@1+ (1,-40) [-40|210] "deg C" Vector__XXX

BO_ 2566656510 TGFI: 8 Vector__XXX
SG_ EngineTotalGaseousFuelVolumeUsed : 0|32@1+ (0.5,0) [0|2105540607.5] "m^3" Vector__XXX
SG_ EngTotalGasIdleFuelVolumeUsed : 32|32@1+ (0.5,0) [0|2105540607.5] "m^3" Vector__XXX

BO_ 2499547902 CDC: 8 Vector__XXX
SG_ CabDoorsLockActuationCommand : 0|3@1+ (1,0) [0|7] "" Vector__XXX
SG_ RemoteCabDoorLockRequest : 8|3@1+ (1,0) [0|7] "" Vector__XXX
SG_ LeftFrontWindowPositionCommand : 16|3@1+ (1,0) [0|7] "" Vector__XXX
SG_ RightFrontWindowPositionCommand : 19|3@1+ (1,0) [0|7] "" Vector__XXX
SG_ LeftRearWindowPositionCommand : 24|3@1+ (1,0) [0|7] "" Vector__XXX
SG_ RightRearWindowPositionCommand : 27|3@1+ (1,0) [0|7] "" Vector__XXX
SG_ MirrorLeft1HorizontalCommand : 32|2@1+ (1,0) [0|3] "" Vector__XXX
SG_ MirrorLeft1VerticalCommand : 34|2@1+ (1,0) [0|3] "" Vector__XXX
SG_ MirrorRight1HorizontalCommand : 36|2@1+ (1,0) [0|3] "" Vector__XXX
SG_ MirrorRight1VerticalCommand : 38|2@1+ (1,0) [0|3] "" Vector__XXX
SG_ MirrorLeft2HorizontalCommand : 40|2@1+ (1,0) [0|3] "" Vector__XXX
SG_ MirrorLeft2VerticalCommand : 42|2@1+ (1,0) [0|3] "" Vector__XXX
SG_ MirrorRight2HorizontalCommand : 44|2@1+ (1,0) [0|3] "" Vector__XXX
SG_ MirrorRight2VerticalCommand : 46|2@1+ (1,0) [0|3] "" Vector__XXX
SG_ MirrorLeft1HeatCommand : 48|2@1+ (1,0) [0|3] "" Vector__XXX
SG_ MirrorRight1HeatCommand : 50|2@1+ (1,0) [0|3] "" Vector__XXX
SG_ MirrorLeft2HeatCommand : 52|2@1+ (1,0) [0|3] "" Vector__XXX
SG_ MirrorRight2HeatCommand : 54|2@1+ (1,0) [0|3] "" Vector__XXX

BO_ 2499548158 DLS: 8 Vector__XXX
SG_ LeftFrontCabDoorLatchPosition : 0|3@1+ (1,0) [0|7] "" Vector__XXX
SG_ RightFrontCabDoorLatchPosition : 8|3@1+ (1,0) [0|7] "" Vector__XXX
SG_ LeftRearCabDoorLatchPosition : 16|3@1+ (1,0) [0|7] "" Vector__XXX
SG_ RightRearCabDoorLatchPosition : 24|3@1+ (1,0) [0|7] "" Vector__XXX

BO_ 2499548670 VEP6: 8 Vector__XXX
SG_ BatteryPotentialPowerInput3 : 0|16@1+ (0.05,0) [0|3212.75] "V" Vector__XXX
SG_ BatteryPotentialPowerInput4 : 16|16@1+ (0.05,0) [0|3212.75] "V" Vector__XXX
SG_ SLIBattery3NetCurrent : 32|16@1+ (0.05,-1600) [-1600|1612.75] "A" Vector__XXX
SG_ SLIBattery4NetCurrent : 48|16@1+ (0.05,-1600) [-1600|1612.75] "A" Vector__XXX

BO_ 2499548926 PLT2: 8 Vector__XXX
SG_ PayloadTemperature5 : 0|16@1+ (0.03125,-273) [-273|1734.96875] "deg C" Vector__XXX

BO_ 2499549182 PLT1: 8 Vector__XXX
SG_ PayloadTemperature1 : 0|16@1+ (0.03125,-273) [-273|1734.96875] "deg C" Vector__XXX
SG_ PayloadTemperature2 : 16|16@1+ (0.03125,-273) [-273|1734.96875] "deg C" Vector__XXX
SG_ PayloadTemperature3 : 32|16@1+ (0.03125,-273) [-273|1734.96875] "deg C" Vector__XXX
SG_ PayloadTemperature4 : 48|16@1+ (0.03125,-273) [-273|1734.96875] "deg C" Vector__XXX

BO_ 2566658302 PLST2: 8 Vector__XXX
SG_ TotalPayloadTransactionCount : 0|32@1+ (1,0) [0|4211081215] "" Vector__XXX

BO_ 2566658558 PLST1: 8 Vector__XXX
SG_ TotalDeliveredPayloadWeight : 0|32@1+ (100,0) [0|421108121500] "kg" Vector__XXX
SG_ TotalHaulCycleCount : 32|32@1+ (1,0) [0|4211081215] "" Vector__XXX

BO_ 2633769726 EEC19: 8 Vector__XXX
SG_ TotalEngineEnergy : 0|32@1+ (1,0) [0|4211081215] "kWh" Vector__XXX
SG_ EngineExhaustFlowRate : 32|32@1+ (0.001,0) [0|4211081.215] "kg/h" Vector__XXX

BO_ 2566661118 LFC2: 8 Vector__XXX
SG_ EngineTotalDieselFuelDemand : 0|32@1+ (0.5,0) [0|2105540607.5] "l" Vector__XXX

BO_ 2566661374 AT2T1I2: 8 Vector__XXX
SG_ Aftrtrtmnt2DslExhstFldTnkVolume2 : 0|8@1+ (0.4,0) [0|100] "%" Vector__XXX
SG_ Aftrtrtmnt2DslExhstFldTnkTemp2 : 8|8@1+ (1,-40) [-40|210] "deg C" Vector__XXX
SG_ Aftrtrtmnt2DslExhstFldTankHtr2 : 16|8@1+ (0.4,0) [0|100] "%" Vector__XXX

BO_ 2566661630 AT1T1I2: 8 Vector__XXX
SG_ Aftrtrtmnt1DslExhstFldTnkVolume2 : 0|8@1+ (0.4,0) [0|100] "%" Vector__XXX
SG_ Aftrtrtmnt1DslExhstFldTnkTemp2 : 8|8@1+ (1,-40) [-40|210] "deg C" Vector__XXX
SG_ Aftrtrtmnt1DslExhstFldTankHtr2 : 16|8@1+ (0.4,0) [0|100] "%" Vector__XXX

BO_ 2566661886 A2DEFI2: 8 Vector__XXX
SG_ Aft2DslExhstFldCtrllerTemp : 0|8@1+ (1,-40) [-40|210] "deg C" Vector__XXX
SG_ Aft2DslExhstFldCtrller2Temp : 8|8@1+ (1,-40) [-40|210] "deg C" Vector__XXX

BO_ 2566662142 A1DEFI2: 8 Vector__XXX
SG_ Aft1DslExhstFldCtrller1Temp : 0|8@1+ (1,-40) [-40|210] "deg C" Vector__XXX
SG_ Aft1DslExhstFldCtrller2Temp : 8|8@1+ (1,-40) [-40|210] "deg C" Vector__XXX

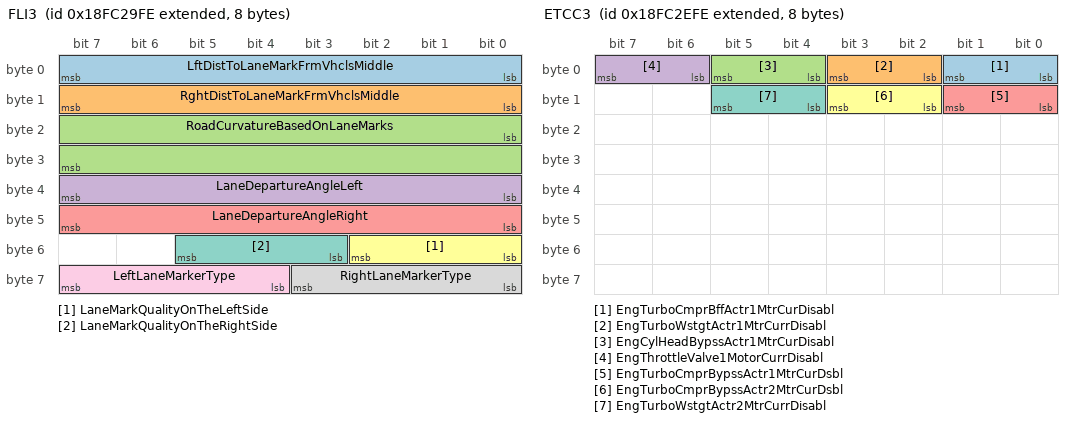
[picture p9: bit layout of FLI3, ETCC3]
BO_ 2566662654 FLI3: 8 Vector__XXX
SG_ LftDistToLaneMarkFrmVhclsMiddle : 0|8@1+ (0.02,0) [0|5] "m" Vector__XXX
SG_ RghtDistToLaneMarkFrmVhclsMiddle : 8|8@1+ (0.02,0) [0|5] "m" Vector__XXX
SG_ RoadCurvatureBasedOnLaneMarks : 16|16@1+ (0.0078125,-250) [-250|251.992] "1/km" Vector__XXX
SG_ LaneDepartureAngleLeft : 32|8@1+ (0.1,-12.5) [-12.5|12.5] "deg" Vector__XXX
SG_ LaneDepartureAngleRight : 40|8@1+ (0.1,-12.5) [-12.5|12.5] "deg" Vector__XXX
SG_ LaneMarkQualityOnTheLeftSide : 48|3@1+ (1,0) [0|7] "" Vector__XXX
SG_ LaneMarkQualityOnTheRightSide : 51|3@1+ (1,0) [0|7] "" Vector__XXX
SG_ RightLaneMarkerType : 56|4@1+ (1,0) [0|15] "" Vector__XXX
SG_ LeftLaneMarkerType : 60|4@1+ (1,0) [0|15] "" Vector__XXX

BO_ 2566662910 OII: 8 Vector__XXX
SG_ OperatorIndcmntTorqueDerateLvl1 : 0|8@1+ (1,0) [0|250] "%" Vector__XXX
SG_ OprtrIndcmntTmeToTrqDerateLvl1 : 8|16@1+ (1,0) [0|64255] "min" Vector__XXX
SG_ OperatorIndcmntTorqueDerateLvl2 : 24|8@1+ (1,0) [0|250] "%" Vector__XXX
SG_ OprtrIndcmntTmeToTrqDerateLvl2 : 32|16@1+ (1,0) [0|64255] "min" Vector__XXX
SG_ OprtrIndcmntTmeToFinalIndcmntAct : 48|16@1+ (1,0) [0|64255] "min" Vector__XXX

BO_ 2566663166 CCVS4: 8 Vector__XXX
SG_ AppliedVehicleSpeedLimit : 0|16@1+ (0.00390625,0) [0|250.996] "km/h" Vector__XXX
SG_ CruiseCtrlAdjustedMaximumSpeed : 16|16@1+ (0.00390625,0) [0|250.996] "km/h" Vector__XXX
SG_ EngExternalIdleRequestFeedback : 32|2@1+ (1,0) [0|3] "" Vector__XXX

BO_ 2566663422 BCLC: 8 Vector__XXX
SG_ TractorBrkCaliperLnngClrAxl1Lft : 0|2@1+ (1,0) [0|3] "" Vector__XXX
SG_ TractorBrkCaliperLnngClrAxl1Rght : 2|2@1+ (1,0) [0|3] "" Vector__XXX
SG_ TractorBrkCaliperLnngClrAxl2Lft : 4|2@1+ (1,0) [0|3] "" Vector__XXX
SG_ TractorBrkCaliperLnngClrAxl2Rght : 6|2@1+ (1,0) [0|3] "" Vector__XXX
SG_ TractorBrkCaliperLnngClrAxl3Lft : 8|2@1+ (1,0) [0|3] "" Vector__XXX
SG_ TractorBrkCaliperLnngClrAxl3Rght : 10|2@1+ (1,0) [0|3] "" Vector__XXX
SG_ TractorBrkCaliperLnngClrAxl4Lft : 12|2@1+ (1,0) [0|3] "" Vector__XXX
SG_ TractorBrkCaliperLnngClrAxl4Rght : 14|2@1+ (1,0) [0|3] "" Vector__XXX
SG_ TractorBrkCaliperLnngClrAxl5Lft : 16|2@1+ (1,0) [0|3] "" Vector__XXX
SG_ TractorBrkCaliperLnngClrAxl5Rght : 18|2@1+ (1,0) [0|3] "" Vector__XXX
SG_ TrlrBrkCaliperLnngClearAxl1Lft : 20|2@1+ (1,0) [0|3] "" Vector__XXX
SG_ TrlrBrkCaliperLnngClearAxl1Rght : 22|2@1+ (1,0) [0|3] "" Vector__XXX
SG_ TrlrBrkCaliperLnngClearAxl2Lft : 24|2@1+ (1,0) [0|3] "" Vector__XXX
SG_ TrlrBrkCaliperLnngClearAxl2Rght : 26|2@1+ (1,0) [0|3] "" Vector__XXX
SG_ TrlrBrkCaliperLnngClearAxl3Lft : 28|2@1+ (1,0) [0|3] "" Vector__XXX
SG_ TrlrBrkCaliperLnngClearAxl3Rght : 30|2@1+ (1,0) [0|3] "" Vector__XXX
SG_ TrlrBrkCaliperLnngClearAxl4Lft : 32|2@1+ (1,0) [0|3] "" Vector__XXX
SG_ TrlrBrkCaliperLnngClearAxl4Rght : 34|2@1+ (1,0) [0|3] "" Vector__XXX
SG_ TrlrBrkCaliperLnngClearAxl5Lft : 36|2@1+ (1,0) [0|3] "" Vector__XXX
SG_ TrlrBrkCaliperLnngClearAxl5Rght : 38|2@1+ (1,0) [0|3] "" Vector__XXX

BO_ 2566663678 AF5: 8 Vector__XXX
SG_ LNGTank1VaporPressure : 0|16@1+ (0.1,0) [0|6425.5] "kPa" Vector__XXX
SG_ LNGTank2VaporPressure : 16|16@1+ (0.1,0) [0|6425.5] "kPa" Vector__XXX
SG_ EngFuel2InjectrMeterngRail1Temp2 : 32|8@1+ (1,-40) [-40|210] "deg C" Vector__XXX

BO_ 2566663934 ETCC3: 8 Vector__XXX
SG_ EngTurboCmprBffActr1MtrCurDisabl : 0|2@1+ (1,0) [0|3] "" Vector__XXX
SG_ EngTurboWstgtActr1MtrCurrDisabl : 2|2@1+ (1,0) [0|3] "" Vector__XXX
SG_ EngCylHeadBypssActr1MtrCurDisabl : 4|2@1+ (1,0) [0|3] "" Vector__XXX
SG_ EngThrottleValve1MotorCurrDisabl : 6|2@1+ (1,0) [0|3] "" Vector__XXX
SG_ EngTurboCmprBypssActr1MtrCurDsbl : 8|2@1+ (1,0) [0|3] "" Vector__XXX
SG_ EngTurboCmprBypssActr2MtrCurDsbl : 10|2@1+ (1,0) [0|3] "" Vector__XXX
SG_ EngTurboWstgtActr2MtrCurrDisabl : 12|2@1+ (1,0) [0|3] "" Vector__XXX

BO_ 2633773054 FSAS: 8 Vector__XXX
SG_ FireSuppressionWaterTankLevel : 0|8@1+ (0.4,0) [0|100] "%" Vector__XXX
SG_ FireSuppressionClassAFoamTankLvl : 8|8@1+ (0.4,0) [0|100] "%" Vector__XXX
SG_ FireSuppressionClassBFoamTankLvl : 16|8@1+ (0.4,0) [0|100] "%" Vector__XXX
SG_ FireSupprssnCmpdAirFoamSysAirPrs : 24|8@1+ (8,0) [0|2000] "kPa" Vector__XXX

BO_ 2633773310 SCROII4: 8 Vector__XXX
SG_ SCROprtrIndcEmrgOvrrdTtlRstOccur : 0|16@1+ (1,0) [0|64255] "" Vector__XXX
SG_ SCROperatorIndcmntOverrideMode : 16|3@1+ (1,0) [0|7] "" Vector__XXX
SG_ SCROprtrIndcOvrrdRenewalRequired : 19|2@1+ (1,0) [0|3] "" Vector__XXX
SG_ SCROprtrIndcmntOverrdTimeRemain : 24|16@1+ (1,0) [0|64255] "min" Vector__XXX

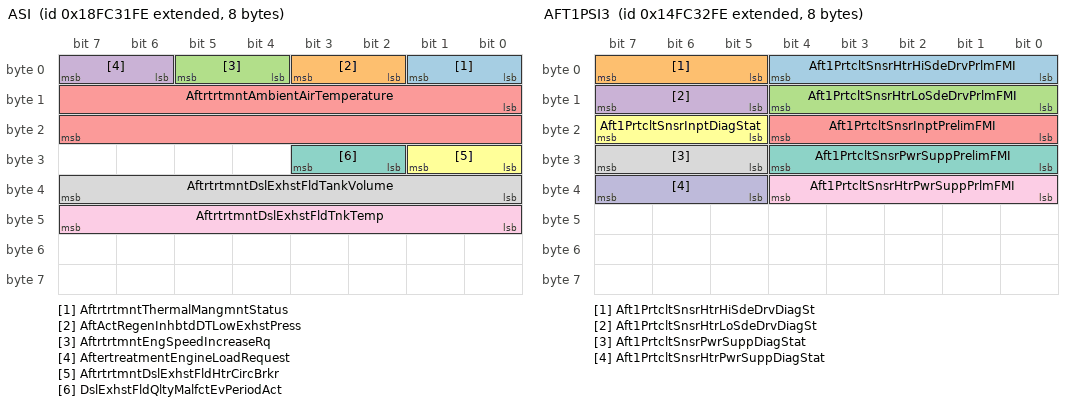
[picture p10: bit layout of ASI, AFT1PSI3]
BO_ 2566664702 ASI: 8 Vector__XXX
SG_ AftrtrtmntThermalMangmntStatus : 0|2@1+ (1,0) [0|3] "" Vector__XXX
SG_ AftActRegenInhbtdDTLowExhstPress : 2|2@1+ (1,0) [0|3] "" Vector__XXX
SG_ AftrtrtmntEngSpeedIncreaseRq : 4|2@1+ (1,0) [0|3] "" Vector__XXX
SG_ AftertreatmentEngineLoadRequest : 6|2@1+ (1,0) [0|3] "" Vector__XXX
SG_ AftrtrtmntAmbientAirTemperature : 8|16@1+ (0.03125,-273) [-273|1734.96875] "deg C" Vector__XXX
SG_ AftrtrtmntDslExhstFldHtrCircBrkr : 24|2@1+ (1,0) [0|3] "" Vector__XXX
SG_ DslExhstFldQltyMalfctEvPeriodAct : 26|2@1+ (1,0) [0|3] "" Vector__XXX
SG_ AftrtrtmntDslExhstFldTankVolume : 32|8@1+ (0.4,0) [0|100] "%" Vector__XXX
SG_ AftrtrtmntDslExhstFldTnkTemp : 40|8@1+ (1,-40) [-40|210] "deg C" Vector__XXX

BO_ 2499556094 AFT1PSI3: 8 Vector__XXX
SG_ Aft1PrtcltSnsrHtrHiSdeDrvPrlmFMI : 0|5@1+ (1,0) [0|31] "" Vector__XXX
SG_ Aft1PrtcltSnsrHtrHiSdeDrvDiagSt : 5|3@1+ (1,0) [0|7] "" Vector__XXX
SG_ Aft1PrtcltSnsrHtrLoSdeDrvPrlmFMI : 8|5@1+ (1,0) [0|31] "" Vector__XXX
SG_ Aft1PrtcltSnsrHtrLoSdeDrvDiagSt : 13|3@1+ (1,0) [0|7] "" Vector__XXX
SG_ Aft1PrtcltSnsrInptPrelimFMI : 16|5@1+ (1,0) [0|31] "" Vector__XXX
SG_ Aft1PrtcltSnsrInptDiagStat : 21|3@1+ (1,0) [0|7] "" Vector__XXX
SG_ Aft1PrtcltSnsrPwrSuppPrelimFMI : 24|5@1+ (1,0) [0|31] "" Vector__XXX
SG_ Aft1PrtcltSnsrPwrSuppDiagStat : 29|3@1+ (1,0) [0|7] "" Vector__XXX
SG_ Aft1PrtcltSnsrHtrPwrSuppPrlmFMI : 32|5@1+ (1,0) [0|31] "" Vector__XXX
SG_ Aft1PrtcltSnsrHtrPwrSuppDiagStat : 37|3@1+ (1,0) [0|7] "" Vector__XXX

BO_ 2499556350 EFIMRPI3: 8 Vector__XXX
SG_ EngFuel1InjectrMtrngRail1DsrdPrs : 0|16@1+ (5,0) [0|321275] "kPa" Vector__XXX
SG_ EngFuel1InjectrMtrngRail2DsrdPrs : 16|16@1+ (5,0) [0|321275] "kPa" Vector__XXX

BO_ 2499556606 EFIMRPI2: 8 Vector__XXX
SG_ EngFuel1InjectrMtrngRail1Press1 : 0|16@1+ (5,0) [0|321275] "kPa" Vector__XXX
SG_ EngFuel1InjectrMtrngRail1Press2 : 16|16@1+ (5,0) [0|321275] "kPa" Vector__XXX
SG_ EngFuel1InjectrMtrngRail2Press1 : 32|16@1+ (5,0) [0|321275] "kPa" Vector__XXX
SG_ EngFuel1InjectrMtrngRail2Press2 : 48|16@1+ (5,0) [0|321275] "kPa" Vector__XXX

BO_ 2566665726 AT2P1I: 8 Vector__XXX
SG_ Aftrtrtmnt2DslExhstFldPumpHeater : 0|8@1+ (0.4,0) [0|100] "%" Vector__XXX
SG_ Aftrtrtmnt2DslExhstFldPmp2MtrSpd : 8|16@1+ (0.5,0) [0|32127.5] "rpm" Vector__XXX

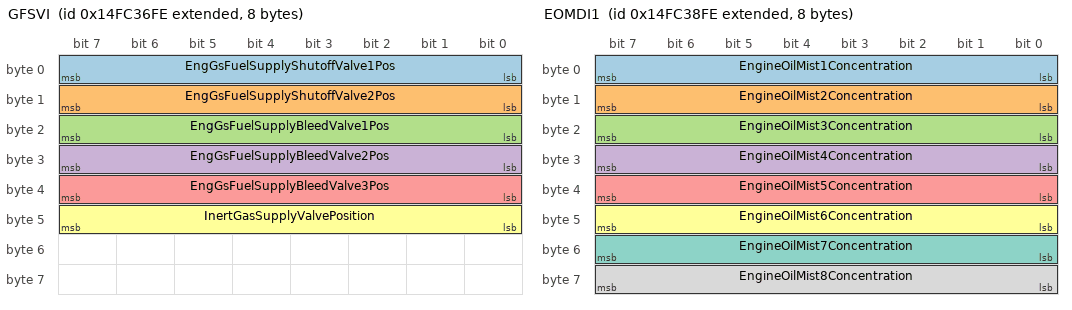
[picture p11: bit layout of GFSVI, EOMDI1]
BO_ 2499557118 GFSVI: 8 Vector__XXX
SG_ EngGsFuelSupplyShutoffValve1Pos : 0|8@1+ (0.4,0) [0|100] "%" Vector__XXX
SG_ EngGsFuelSupplyShutoffValve2Pos : 8|8@1+ (0.4,0) [0|100] "%" Vector__XXX
SG_ EngGsFuelSupplyBleedValve1Pos : 16|8@1+ (0.4,0) [0|100] "%" Vector__XXX
SG_ EngGsFuelSupplyBleedValve2Pos : 24|8@1+ (0.4,0) [0|100] "%" Vector__XXX
SG_ EngGsFuelSupplyBleedValve3Pos : 32|8@1+ (0.4,0) [0|100] "%" Vector__XXX
SG_ InertGasSupplyValvePosition : 40|8@1+ (0.4,0) [0|100] "%" Vector__XXX

BO_ 2499557374 EOMDI2: 8 Vector__XXX
SG_ EngineOilMist9Concentration : 0|8@1+ (1,0) [0|250] "%" Vector__XXX
SG_ EngineOilMist10Concentration : 8|8@1+ (1,0) [0|250] "%" Vector__XXX

BO_ 2499557630 EOMDI1: 8 Vector__XXX
SG_ EngineOilMist1Concentration : 0|8@1+ (1,0) [0|250] "%" Vector__XXX
SG_ EngineOilMist2Concentration : 8|8@1+ (1,0) [0|250] "%" Vector__XXX
SG_ EngineOilMist3Concentration : 16|8@1+ (1,0) [0|250] "%" Vector__XXX
SG_ EngineOilMist4Concentration : 24|8@1+ (1,0) [0|250] "%" Vector__XXX
SG_ EngineOilMist5Concentration : 32|8@1+ (1,0) [0|250] "%" Vector__XXX
SG_ EngineOilMist6Concentration : 40|8@1+ (1,0) [0|250] "%" Vector__XXX
SG_ EngineOilMist7Concentration : 48|8@1+ (1,0) [0|250] "%" Vector__XXX
SG_ EngineOilMist8Concentration : 56|8@1+ (1,0) [0|250] "%" Vector__XXX

BO_ 2499557886 GFSP2: 8 Vector__XXX
SG_ PlantGasFuelSupplyOutletPressure : 0|16@1+ (0.5,0) [0|32127.5] "kPa" Vector__XXX
SG_ PlantInertGsSupplyOutletPressure : 16|16@1+ (0.5,0) [0|32127.5] "kPa" Vector__XXX

BO_ 2499558142 GFSP1: 8 Vector__XXX
SG_ EngineGaseousFuelSupplyPressure2 : 0|16@1+ (0.5,0) [0|32127.5] "kPa" Vector__XXX
SG_ EngGsFuelSupplyUnitIntkPressure : 16|16@1+ (0.5,0) [0|32127.5] "kPa" Vector__XXX
SG_ EngGsFuelSuppShtoffVlv1IntkPress : 32|16@1+ (0.5,0) [0|32127.5] "kPa" Vector__XXX
SG_ EngGsFuelSuppShtoffVlv2IntkPress : 48|16@1+ (0.5,0) [0|32127.5] "kPa" Vector__XXX

BO_ 2566667262 EEBT3: 8 Vector__XXX
SG_ EngineEndBearing17Temperature : 0|8@1+ (1,-40) [-40|210] "deg C" Vector__XXX
SG_ EngineEndBearing18Temperature : 8|8@1+ (1,-40) [-40|210] "deg C" Vector__XXX
SG_ EngineEndBearing19Temperature : 16|8@1+ (1,-40) [-40|210] "deg C" Vector__XXX
SG_ EngineEndBearing20Temperature : 24|8@1+ (1,-40) [-40|210] "deg C" Vector__XXX

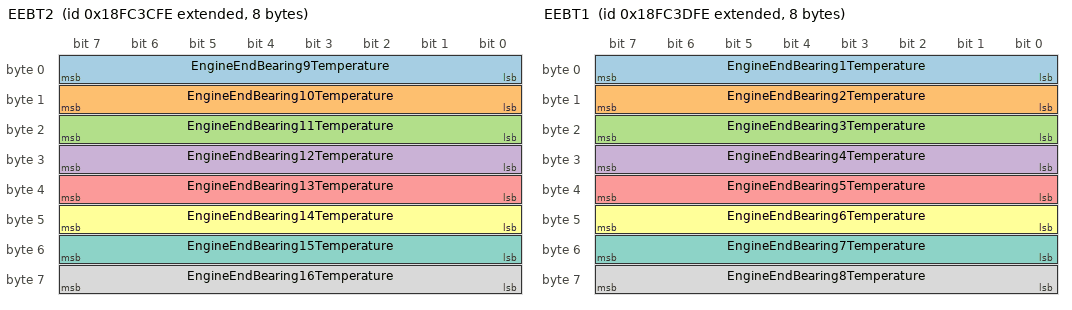
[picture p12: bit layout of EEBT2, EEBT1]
BO_ 2566667518 EEBT2: 8 Vector__XXX
SG_ EngineEndBearing9Temperature : 0|8@1+ (1,-40) [-40|210] "deg C" Vector__XXX
SG_ EngineEndBearing10Temperature : 8|8@1+ (1,-40) [-40|210] "deg C" Vector__XXX
SG_ EngineEndBearing11Temperature : 16|8@1+ (1,-40) [-40|210] "deg C" Vector__XXX
SG_ EngineEndBearing12Temperature : 24|8@1+ (1,-40) [-40|210] "deg C" Vector__XXX
SG_ EngineEndBearing13Temperature : 32|8@1+ (1,-40) [-40|210] "deg C" Vector__XXX
SG_ EngineEndBearing14Temperature : 40|8@1+ (1,-40) [-40|210] "deg C" Vector__XXX
SG_ EngineEndBearing15Temperature : 48|8@1+ (1,-40) [-40|210] "deg C" Vector__XXX
SG_ EngineEndBearing16Temperature : 56|8@1+ (1,-40) [-40|210] "deg C" Vector__XXX

BO_ 2566667774 EEBT1: 8 Vector__XXX
SG_ EngineEndBearing1Temperature : 0|8@1+ (1,-40) [-40|210] "deg C" Vector__XXX
SG_ EngineEndBearing2Temperature : 8|8@1+ (1,-40) [-40|210] "deg C" Vector__XXX
SG_ EngineEndBearing3Temperature : 16|8@1+ (1,-40) [-40|210] "deg C" Vector__XXX
SG_ EngineEndBearing4Temperature : 24|8@1+ (1,-40) [-40|210] "deg C" Vector__XXX
SG_ EngineEndBearing5Temperature : 32|8@1+ (1,-40) [-40|210] "deg C" Vector__XXX
SG_ EngineEndBearing6Temperature : 40|8@1+ (1,-40) [-40|210] "deg C" Vector__XXX
SG_ EngineEndBearing7Temperature : 48|8@1+ (1,-40) [-40|210] "deg C" Vector__XXX
SG_ EngineEndBearing8Temperature : 56|8@1+ (1,-40) [-40|210] "deg C" Vector__XXX

BO_ 2566668030 HEDPI: 8 Vector__XXX
SG_ HeatExchangerDebrisPurgeStatus : 0|2@1+ (1,0) [0|3] "" Vector__XXX
SG_ HeatExchangerDebrisPurgeApprchng : 2|2@1+ (1,0) [0|3] "" Vector__XXX

BO_ 2566668286 ETCC2: 8 Vector__XXX
SG_ EngStagedTurboSolenoidStat : 0|8@1+ (0.4,0) [0|100] "%" Vector__XXX

BO_ 2566668542 EHF2PC: 8 Vector__XXX
SG_ EngFuel2PumpHydrFlwCtrlValve : 0|8@1+ (0.4,0) [0|100] "%" Vector__XXX
SG_ EngFuel2PumpHydrSwashPlateAgl : 8|8@1+ (0.4,0) [0|100] "%" Vector__XXX
SG_ EngFuel2PumpHydrDirectionalValve : 16|8@1+ (0.4,0) [0|100] "%" Vector__XXX
SG_ EngineFuel2PumpHydraulicPressure : 24|16@1+ (2,0) [0|128510] "kPa" Vector__XXX

BO_ 2566668798 AF4: 8 Vector__XXX
SG_ EngFuel2InjectrMeterngRail1Press : 0|16@1+ (2,0) [0|128510] "kPa" Vector__XXX
SG_ EngFuel2InjectrMeterngRail2Press : 16|16@1+ (2,0) [0|128510] "kPa" Vector__XXX
SG_ EngFuel2InjectrMeterngRail1Temp : 32|8@1+ (1,-40) [-40|210] "deg C" Vector__XXX
SG_ EngFuel2InjectrMeterngRail2Temp : 40|8@1+ (1,-40) [-40|210] "deg C" Vector__XXX
SG_ EngFuel2InjectrMtrngRail1Press2 : 48|16@1+ (2,0) [0|128510] "kPa" Vector__XXX

BO_ 2566669054 TIRE2: 8 Vector__XXX
SG_ TireLocation : 0|8@1+ (1,0) [0|255] "" Vector__XXX
SG_ TirePressure : 8|16@1+ (1,0) [0|64255] "kPa" Vector__XXX
SG_ RequiredTirePressure : 24|16@1+ (1,0) [0|64255] "kPa" Vector__XXX

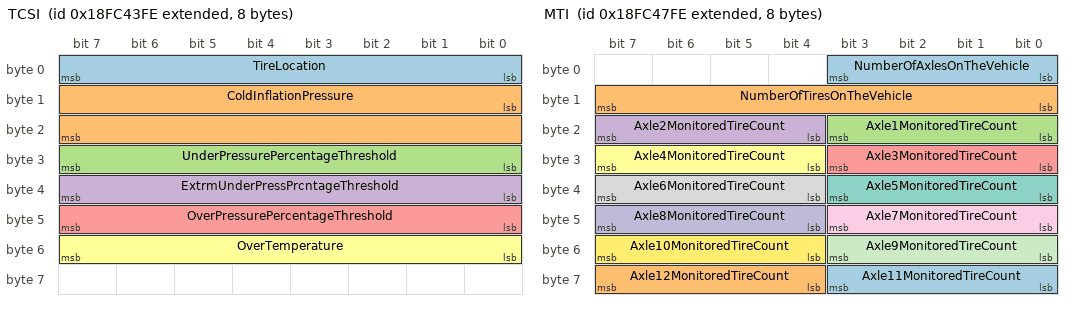
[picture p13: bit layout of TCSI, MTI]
BO_ 2566669310 TCSI: 8 Vector__XXX
SG_ TireLocation : 0|8@1+ (1,0) [0|255] "" Vector__XXX
SG_ ColdInflationPressure : 8|16@1+ (1,0) [0|64255] "kPa" Vector__XXX
SG_ UnderPressurePercentageThreshold : 24|8@1+ (0.5,0) [0|125] "%" Vector__XXX
SG_ ExtrmUnderPressPrcntageThreshold : 32|8@1+ (0.5,0) [0|125] "%" Vector__XXX
SG_ OverPressurePercentageThreshold : 40|8@1+ (0.5,0) [0|125] "%" Vector__XXX
SG_ OverTemperature : 48|8@1+ (1,-40) [-40|210] "deg C" Vector__XXX

BO_ 2566669822 TWSSI: 8 Vector__XXX
SG_ TotalNumberOfAntennasUsed : 0|8@1+ (1,0) [0|250] "" Vector__XXX
SG_ AntennaNumber : 0|8@1+ (1,0) [0|250] "" Vector__XXX
SG_ TotalNumberTireSensorsMonitored : 0|8@1+ (1,0) [0|250] "" Vector__XXX
SG_ TireSensorNumber : 0|8@1+ (1,0) [0|250] "" Vector__XXX
SG_ TireLocation : 0|8@1+ (1,0) [0|255] "" Vector__XXX
SG_ TireWirelessSigStrengthIndictr : 0|8@1+ (0.5,-125) [-125|0] "dBm" Vector__XXX

BO_ 2566670078 TSIS: 200 Vector__XXX
SG_ NumberOfTireSensors : 0|8@1+ (1,0) [0|250] "" Vector__XXX
SG_ TireNumber : 0|8@1+ (1,0) [0|250] "" Vector__XXX
SG_ TireLocation : 0|8@1+ (1,0) [0|255] "" Vector__XXX
SG_ TireSensorIdentificationNumber : 7|1600@0+ (1,0) [0|0] "ASCII" Vector__XXX

BO_ 2566670334 MTI: 8 Vector__XXX
SG_ NumberOfAxlesOnTheVehicle : 0|4@1+ (1,0) [0|13] "" Vector__XXX
SG_ NumberOfTiresOnTheVehicle : 8|8@1+ (1,0) [0|250] "" Vector__XXX
SG_ Axle1MonitoredTireCount : 16|4@1+ (1,0) [0|13] "" Vector__XXX
SG_ Axle2MonitoredTireCount : 20|4@1+ (1,0) [0|13] "" Vector__XXX
SG_ Axle3MonitoredTireCount : 24|4@1+ (1,0) [0|13] "" Vector__XXX
SG_ Axle4MonitoredTireCount : 28|4@1+ (1,0) [0|13] "" Vector__XXX
SG_ Axle5MonitoredTireCount : 32|4@1+ (1,0) [0|13] "" Vector__XXX
SG_ Axle6MonitoredTireCount : 36|4@1+ (1,0) [0|13] "" Vector__XXX
SG_ Axle7MonitoredTireCount : 40|4@1+ (1,0) [0|13] "" Vector__XXX
SG_ Axle8MonitoredTireCount : 44|4@1+ (1,0) [0|13] "" Vector__XXX
SG_ Axle9MonitoredTireCount : 48|4@1+ (1,0) [0|13] "" Vector__XXX
SG_ Axle10MonitoredTireCount : 52|4@1+ (1,0) [0|13] "" Vector__XXX
SG_ Axle11MonitoredTireCount : 56|4@1+ (1,0) [0|13] "" Vector__XXX
SG_ Axle12MonitoredTireCount : 60|4@1+ (1,0) [0|13] "" Vector__XXX

BO_ 2566670590 AT2HI2: 24 Vector__XXX
SG_ Aft2SCRSysTotalSysCleaningTme : 0|32@1+ (1,0) [0|4211081215] "s" Vector__XXX
SG_ Aft2SCRSysTotalNoSysCleaningEvts : 32|32@1+ (1,0) [0|4211081215] "" Vector__XXX
SG_ Aft2SCRSysTotalNoSysCleangInhRqs : 64|32@1+ (1,0) [0|4211081215] "" Vector__XXX
SG_ Aft2SCRSysTotalNoSysCleangManRqs : 96|32@1+ (1,0) [0|4211081215] "" Vector__XXX
SG_ Aft2SCRSysAvrgTmeBtwnSysClngEvts : 128|32@1+ (1,0) [0|4211081215] "s" Vector__XXX
SG_ Aft2SCRSysAvDistBtwnSysClengEvts : 160|32@1+ (0.125,0) [0|526385151.875] "km" Vector__XXX

BO_ 2566670846 AT1HI2: 28 Vector__XXX
SG_ Aft1SCRSysTotalCleaningTme : 0|32@1+ (1,0) [0|4211081215] "s" Vector__XXX
SG_ Aft1SCRSysTotalNoOfSysCleangEvts : 32|32@1+ (1,0) [0|4211081215] "" Vector__XXX
SG_ Aft1SCRSysTotalNoSysCleangInhRqs : 64|32@1+ (1,0) [0|4211081215] "" Vector__XXX
SG_ Aft1SCRSysTotalNoSysCleangManRqs : 96|32@1+ (1,0) [0|4211081215] "" Vector__XXX
SG_ Aft1SCRSysAvrTmeBtwnSysCleanEvts : 128|32@1+ (1,0) [0|4211081215] "s" Vector__XXX
SG_ Aft1SCRSysAvDistBtwnSysCleanEvts : 160|32@1+ (0.125,0) [0|526385151.875] "km" Vector__XXX
SG_ TotalAftrtrtmntOperatingHours : 192|32@1+ (1,0) [0|4211081215] "s" Vector__XXX

BO_ 2566671102 SCRSC: 8 Vector__XXX
SG_ SCRSystemCleaningLampCommand : 0|3@1+ (1,0) [0|7] "" Vector__XXX
SG_ SCRSystemCleaningStatus : 10|2@1+ (1,0) [0|3] "" Vector__XXX
SG_ SCRSystemCleaningInhibitedStatus : 16|2@1+ (1,0) [0|3] "" Vector__XXX
SG_ SCRSystemCleaningInhbtdDTInhbtSw : 18|2@1+ (1,0) [0|3] "" Vector__XXX
SG_ SCRSysCleaningInhDTCltchDiseng : 20|2@1+ (1,0) [0|3] "" Vector__XXX
SG_ SCRSysCleaningInhbtdDTSrvcBrkAct : 22|2@1+ (1,0) [0|3] "" Vector__XXX
SG_ SCRSystemCleaningInhbtdDTPTOActv : 24|2@1+ (1,0) [0|3] "" Vector__XXX
SG_ SCRSysCleaningInhDTAcclPdlOffIdl : 26|2@1+ (1,0) [0|3] "" Vector__XXX
SG_ SCRSysCleaningInhbtdDTOutOfNtrl : 28|2@1+ (1,0) [0|3] "" Vector__XXX
SG_ SCRSysClnInhDTVhclSpdAbvAllwdSpd : 30|2@1+ (1,0) [0|3] "" Vector__XXX
SG_ SCRSysCleaningInhDTPrkBrkNotSet : 32|2@1+ (1,0) [0|3] "" Vector__XXX
SG_ SCRSysCleaningInhDTLowExhstTemp : 34|2@1+ (1,0) [0|3] "" Vector__XXX
SG_ SCRSysCleaningInhDTSysFaultAct : 36|2@1+ (1,0) [0|3] "" Vector__XXX
SG_ SCRSysCleaningInhbtdDTSysTimeout : 38|2@1+ (1,0) [0|3] "" Vector__XXX
SG_ SCRSysCleaningInhDTTmprySysLckt : 40|2@1+ (1,0) [0|3] "" Vector__XXX
SG_ SCRSysCleaningInhDTPrmntSysLckt : 42|2@1+ (1,0) [0|3] "" Vector__XXX
SG_ SCRSysCleangInhDTEngNotWarmedUp : 44|2@1+ (1,0) [0|3] "" Vector__XXX
SG_ SCRSysCleangInhDTVehicleSpeed : 46|2@1+ (1,0) [0|3] "" Vector__XXX
SG_ SCRSystemCleaningAutoInitConf : 48|2@1+ (1,0) [0|3] "" Vector__XXX
SG_ SCRSystemCleaningForcedStatus : 53|3@1+ (1,0) [0|7] "" Vector__XXX
SG_ Aft1SCRSysCondtnsNotMetActCleang : 60|2@1+ (1,0) [0|3] "" Vector__XXX

BO_ 2566671358 EEC17: 8 Vector__XXX
SG_ PEMSEngineFuelMassFlowRate : 0|16@1+ (0.02,0) [0|1285.1] "g/s" Vector__XXX
SG_ VehicleFuelRate : 16|16@1+ (0.02,0) [0|1285.1] "g/s" Vector__XXX
SG_ EngineExhaustFlowRate : 32|16@1+ (0.2,0) [0|12851] "kg/h" Vector__XXX
SG_ CylinderFuelRate : 48|16@1+ (0.03125,0) [0|2007.96875] "mg/stroke" Vector__XXX

BO_ 2566671614 SCROII3: 8 Vector__XXX
SG_ SCROperatorIndcmntOverrideEnbl : 0|2@1+ (1,0) [0|3] "" Vector__XXX
SG_ SCROprtrIndcmntOvrrdTimeRemain : 8|16@1+ (1,0) [0|64255] "s" Vector__XXX
SG_ NoSCROprtrIndcmntOvrrdEvtsRemain : 24|8@1+ (1,0) [0|250] "" Vector__XXX
SG_ TotalNoSCROprtrIndcmntOvrrdEvts : 32|16@1+ (1,0) [0|64255] "" Vector__XXX

BO_ 2566671870 A2SCRDSI3: 8 Vector__XXX
SG_ Aftrtrtmnt2DslExhstFldDsngPress : 0|8@1+ (4,0) [0|1000] "kPa" Vector__XXX
SG_ Aft2DslExhstFldDoser2AbsPress : 8|8@1+ (8,0) [0|2000] "kPa" Vector__XXX
SG_ Aftrtrtmnt2DslExhstFldDoser2Temp : 16|8@1+ (1,-40) [-40|210] "deg C" Vector__XXX
SG_ Aft2DslExhstFldDoser2Press : 24|8@1+ (4,0) [0|1000] "kPa" Vector__XXX

BO_ 2566672126 A1SCRDSI3: 8 Vector__XXX
SG_ Aftrtrtmnt1DslExhstFldDsngPress : 0|8@1+ (4,0) [0|1000] "kPa" Vector__XXX
SG_ Aft1DslExhstFldDoser2AbsPress : 8|8@1+ (8,0) [0|2000] "kPa" Vector__XXX
SG_ Aftrtrtmnt1DslExhstFldDoser2Temp : 16|8@1+ (1,-40) [-40|210] "deg C" Vector__XXX
SG_ Aft1DslExhstFldDoser2Press : 24|8@1+ (4,0) [0|1000] "kPa" Vector__XXX

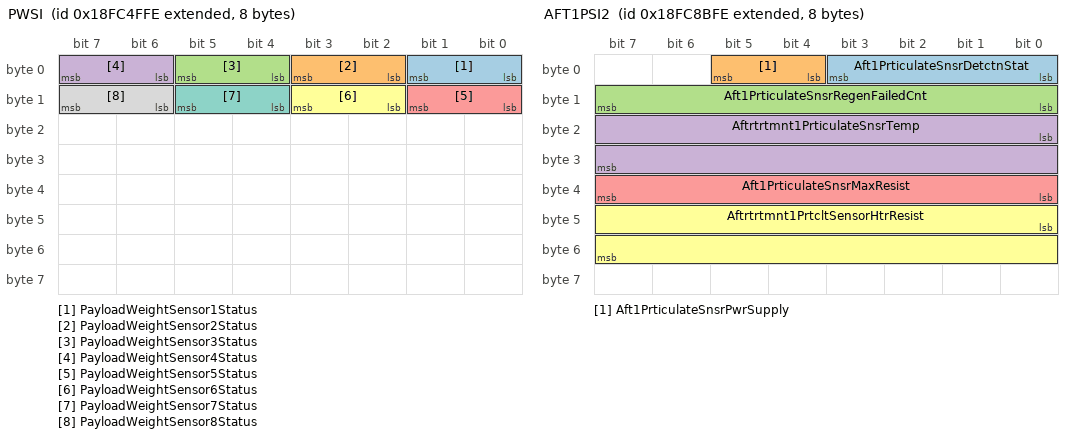
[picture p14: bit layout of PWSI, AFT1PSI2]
BO_ 2566672382 PWSI: 8 Vector__XXX
SG_ PayloadWeightSensor1Status : 0|2@1+ (1,0) [0|3] "" Vector__XXX
SG_ PayloadWeightSensor2Status : 2|2@1+ (1,0) [0|3] "" Vector__XXX
SG_ PayloadWeightSensor3Status : 4|2@1+ (1,0) [0|3] "" Vector__XXX
SG_ PayloadWeightSensor4Status : 6|2@1+ (1,0) [0|3] "" Vector__XXX
SG_ PayloadWeightSensor5Status : 8|2@1+ (1,0) [0|3] "" Vector__XXX
SG_ PayloadWeightSensor6Status : 10|2@1+ (1,0) [0|3] "" Vector__XXX
SG_ PayloadWeightSensor7Status : 12|2@1+ (1,0) [0|3] "" Vector__XXX
SG_ PayloadWeightSensor8Status : 14|2@1+ (1,0) [0|3] "" Vector__XXX

BO_ 2566672638 PLSS: 8 Vector__XXX
SG_ HaulCycleCount : 0|16@1+ (1,0) [0|64255] "" Vector__XXX
SG_ HaulModeStatus : 16|4@1+ (1,0) [0|15] "" Vector__XXX
SG_ PayloadDeliveryTransactionStatus : 20|4@1+ (1,0) [0|15] "" Vector__XXX
SG_ DeliveredPayloadWeight : 24|24@1+ (2,0) [0|32899070] "kg" Vector__XXX
SG_ DeliveredPayloadConfidence : 48|8@1+ (0.5,0) [0|125] "%" Vector__XXX

BO_ 2365346302 ASC7: 8 Vector__XXX
SG_ LiftAxle1Status : 0|3@1+ (1,0) [0|7] "" Vector__XXX
SG_ LiftAxle2Status : 3|3@1+ (1,0) [0|7] "" Vector__XXX

BO_ 2633782014 BWLN: 8 Vector__XXX
SG_ BinInstance : 0|4@1+ (1,0) [0|15] "" Vector__XXX
SG_ BinWeighingErrorStatus : 4|4@1+ (1,0) [0|15] "" Vector__XXX
SG_ BinLiftCount : 8|16@1+ (1,0) [0|64255] "" Vector__XXX
SG_ NetBinWeight : 24|16@1+ (2,0) [0|128510] "kg" Vector__XXX

BO_ 2566673406 EGLI: 8 Vector__XXX
SG_ GaseousFuelLeakage1Concentration : 0|8@1+ (0.5,0) [0|125] "%" Vector__XXX
SG_ GaseousFuelLeakage2Concentration : 8|8@1+ (0.5,0) [0|125] "%" Vector__XXX
SG_ GaseousFuelLeakage3Concentration : 16|8@1+ (0.5,0) [0|125] "%" Vector__XXX
SG_ GasLeakageDetection1Pressure : 24|8@1+ (4,0) [0|1000] "kPa" Vector__XXX
SG_ GasLeakageDetection2Pressure : 32|8@1+ (4,0) [0|1000] "kPa" Vector__XXX
SG_ GasLeakageDetection3Pressure : 40|8@1+ (4,0) [0|1000] "kPa" Vector__XXX

BO_ 2566674174 SCROII2: 8 Vector__XXX
SG_ AftertreatmentSCRMalfunctionTime : 0|32@1+ (1,0) [0|4211081215] "s" Vector__XXX
SG_ SCROperatorInducementTotalTime : 32|32@1+ (1,0) [0|4211081215] "s" Vector__XXX

BO_ 2566674430 SCROII1: 8 Vector__XXX
SG_ DieselExhaustFluidTank1EmptyTime : 0|32@1+ (1,0) [0|4211081215] "s" Vector__XXX
SG_ DslExhstFldQualityMalfunctionTme : 32|32@1+ (1,0) [0|4211081215] "s" Vector__XXX

BO_ 2566674686 TCI7: 8 Vector__XXX
SG_ EngTurbocharger2LubeOilPressure : 0|8@1+ (4,0) [0|1000] "kPa" Vector__XXX
SG_ EngTurbocharger3LubeOilPressure : 8|8@1+ (4,0) [0|1000] "kPa" Vector__XXX
SG_ EngTurbocharger4LubeOilPressure : 16|8@1+ (4,0) [0|1000] "kPa" Vector__XXX
SG_ EngTurbocharger2OilTemperature : 24|16@1+ (0.03125,-273) [-273|1734.96875] "deg C" Vector__XXX

BO_ 2365348350 ELS: 8 Vector__XXX
SG_ EngineUnloadStatus : 0|2@1+ (1,0) [0|3] "" Vector__XXX
SG_ EngineLoadShareStatus : 2|4@1+ (1,0) [0|15] "" Vector__XXX

BO_ 2566675966 HVES1CFG: 16 Vector__XXX
SG_ HVES1NominalVoltage : 0|16@1+ (0.05,0) [0|3212.75] "V" Vector__XXX
SG_ HVES1RecommendedMinOprtngVoltage : 16|16@1+ (0.05,0) [0|3212.75] "V" Vector__XXX
SG_ HVES1RecommendedMaxOprtngVoltage : 32|16@1+ (0.05,0) [0|3212.75] "V" Vector__XXX
SG_ HVES1RecommendedMinimumStateChrg : 48|16@1+ (0.0015625,0) [0|100.3984375] "%" Vector__XXX
SG_ HVES1RecommendedMaximumStateChrg : 64|16@1+ (0.0015625,0) [0|100.3984375] "%" Vector__XXX
SG_ HVES1RecommendedMaxOprtngTemp : 80|16@1+ (0.03125,-273) [-273|1734.96875] "deg C" Vector__XXX
SG_ HVES1RecommendedMinOprtngTemp : 96|16@1+ (0.03125,-273) [-273|1734.96875] "deg C" Vector__XXX
SG_ HVES1CellMaximumVoltageLimit : 112|8@1+ (0.02044,0) [0|5.11] "V" Vector__XXX
SG_ HVES1CellMinimumVoltageLimit : 120|8@1+ (0.02044,0) [0|5.11] "V" Vector__XXX

BO_ 2633785086 HVES1HIST: 11 Vector__XXX
SG_ HVES1StateOfHealth : 0|8@1+ (0.4,0) [0|100] "%" Vector__XXX
SG_ HVES1ContactorOpenUnderLoadCount : 8|16@1+ (1,0) [0|64255] "" Vector__XXX
SG_ HVES1TotalEnergyThroughput : 24|32@1+ (100,0) [0|421108121500] "Watt-hour" Vector__XXX
SG_ HVES1TotalAccumulatedCharge : 56|32@1+ (100,0) [0|421108121500] "Ah" Vector__XXX

BO_ 2566687742 AFT1PSI2: 8 Vector__XXX
SG_ Aft1PrticulateSnsrDetctnStat : 0|4@1+ (1,0) [0|15] "" Vector__XXX
SG_ Aft1PrticulateSnsrPwrSupply : 4|2@1+ (1,0) [0|3] "" Vector__XXX
SG_ Aft1PrticulateSnsrRegenFailedCnt : 8|8@1+ (1,0) [0|250] "" Vector__XXX
SG_ Aftrtrtmnt1PrticulateSnsrTemp : 16|16@1+ (0.03125,-273) [-273|1734.96875] "deg C" Vector__XXX
SG_ Aft1PrticulateSnsrMaxResist : 32|8@1+ (250,0) [0|62500] "kohm" Vector__XXX
SG_ Aftrtrtmnt1PrtcltSensorHtrResist : 40|16@1+ (0.1,0) [0|6425.5] "ohm" Vector__XXX

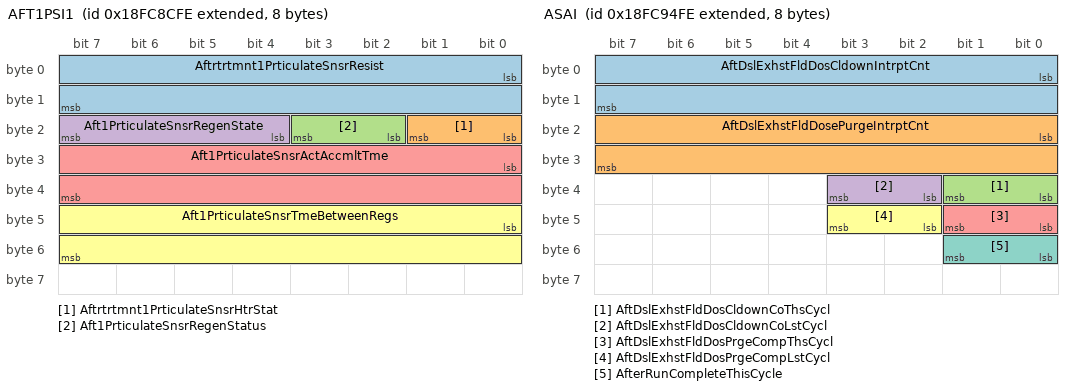
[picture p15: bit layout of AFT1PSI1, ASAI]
BO_ 2566687998 AFT1PSI1: 8 Vector__XXX
SG_ Aftrtrtmnt1PrticulateSnsrResist : 0|16@1+ (1,0) [0|64255] "kohm" Vector__XXX
SG_ Aftrtrtmnt1PrticulateSnsrHtrStat : 16|2@1+ (1,0) [0|3] "" Vector__XXX
SG_ Aft1PrticulateSnsrRegenStatus : 18|2@1+ (1,0) [0|3] "" Vector__XXX
SG_ Aft1PrticulateSnsrRegenState : 20|4@1+ (1,0) [0|15] "" Vector__XXX
SG_ Aft1PrticulateSnsrActAccmltTme : 24|16@1+ (6,0) [0|385530] "s" Vector__XXX
SG_ Aft1PrticulateSnsrTmeBetweenRegs : 40|16@1+ (6,0) [0|385530] "s" Vector__XXX

BO_ 2432471038 AF3: 8 Vector__XXX
SG_ EngineGasSupplyPressure : 0|16@1+ (0.00390625,0) [0|250.996] "MPa" Vector__XXX
SG_ EngFuelVaporizer1DischargeTemp : 16|8@1+ (1,-40) [-40|210] "deg C" Vector__XXX
SG_ EngGaseousFuelFilterOtltTemp : 24|8@1+ (1,-40) [-40|210] "deg C" Vector__XXX

BO_ 2499580158 EFIMRPI1: 8 Vector__XXX
SG_ EngInjectorMeteringRail1Press1 : 0|16@1+ (0.00390625,0) [0|250.996] "MPa" Vector__XXX
SG_ EngInjectorMeteringRail1Press2 : 16|16@1+ (0.00390625,0) [0|250.996] "MPa" Vector__XXX
SG_ EngInjectorMeteringRail2Press1 : 32|16@1+ (0.00390625,0) [0|250.996] "MPa" Vector__XXX
SG_ EngInjectorMeteringRail2Press2 : 48|16@1+ (0.00390625,0) [0|250.996] "MPa" Vector__XXX

BO_ 2566689278 EEN: 8 Vector__XXX
SG_ EngineExhaustNOx : 0|16@1+ (0.05,-200) [-200|3012.75] "ppm" Vector__XXX
SG_ EngineExhaustDesiredNOx : 16|16@1+ (0.05,-200) [-200|3012.75] "ppm" Vector__XXX

BO_ 2566689534 AFR: 8 Vector__XXX
SG_ EngineMainChamberAirFuelRatio : 0|16@1+ (0.001,0) [0|64.255] "" Vector__XXX
SG_ EngMainChamberDsrdAirFuelRatio : 16|16@1+ (0.001,0) [0|64.255] "" Vector__XXX
SG_ EnginePrechamberAirFuelRatio : 32|16@1+ (0.001,0) [0|64.255] "" Vector__XXX
SG_ EnginePrechamberDsrdAirFuelRatio : 48|16@1+ (0.001,0) [0|64.255] "" Vector__XXX

BO_ 2566689790 GFP2: 8 Vector__XXX
SG_ EngineMainChamberFuelAbsPressure : 0|16@1+ (0.1,0) [0|6425.5] "kPa" Vector__XXX
SG_ EngMainChamberFuelDsrdAbsPress : 16|16@1+ (0.1,0) [0|6425.5] "kPa" Vector__XXX
SG_ EnginePrechamberFuelAbsPressure : 32|16@1+ (0.1,0) [0|6425.5] "kPa" Vector__XXX
SG_ EngPrechamberFuelDsrdAbsPressure : 48|16@1+ (0.1,0) [0|6425.5] "kPa" Vector__XXX

BO_ 2566690046 ASAI: 8 Vector__XXX
SG_ AftDslExhstFldDosCldownIntrptCnt : 0|16@1+ (1,0) [0|64255] "" Vector__XXX
SG_ AftDslExhstFldDosePurgeIntrptCnt : 16|16@1+ (1,0) [0|64255] "" Vector__XXX
SG_ AftDslExhstFldDosCldownCoThsCycl : 32|2@1+ (1,0) [0|3] "" Vector__XXX
SG_ AftDslExhstFldDosCldownCoLstCycl : 34|2@1+ (1,0) [0|3] "" Vector__XXX
SG_ AftDslExhstFldDosPrgeCompThsCycl : 40|2@1+ (1,0) [0|3] "" Vector__XXX
SG_ AftDslExhstFldDosPrgeCompLstCycl : 42|2@1+ (1,0) [0|3] "" Vector__XXX
SG_ AfterRunCompleteThisCycle : 48|2@1+ (1,0) [0|3] "" Vector__XXX

BO_ 2365363710 ECPMSI: 8 Vector__XXX
SG_ EngCylPressureMonitor1PrelimFMI : 0|5@1+ (1,0) [0|31] "" Vector__XXX
SG_ EngCylPressureMonitor2PrelimFMI : 8|5@1+ (1,0) [0|31] "" Vector__XXX

BO_ 2566690558 EI2: 8 Vector__XXX
SG_ EngineExhaustPressure1 : 0|16@1+ (0.125,0) [0|8031.875] "kPa" Vector__XXX
SG_ EngineOilFilterIntakePressure : 16|16@1+ (0.1,0) [0|6425.5] "kPa" Vector__XXX
SG_ EngineCommonRailOilPressure : 32|8@1+ (4,0) [0|1000] "kPa" Vector__XXX
SG_ EngineCommonRailOilAbsPressure : 40|8@1+ (4,0) [0|1000] "kPa" Vector__XXX
SG_ EngineExhaustPressure2 : 48|16@1+ (0.0078125,-250) [-250|251.99] "kPa" Vector__XXX

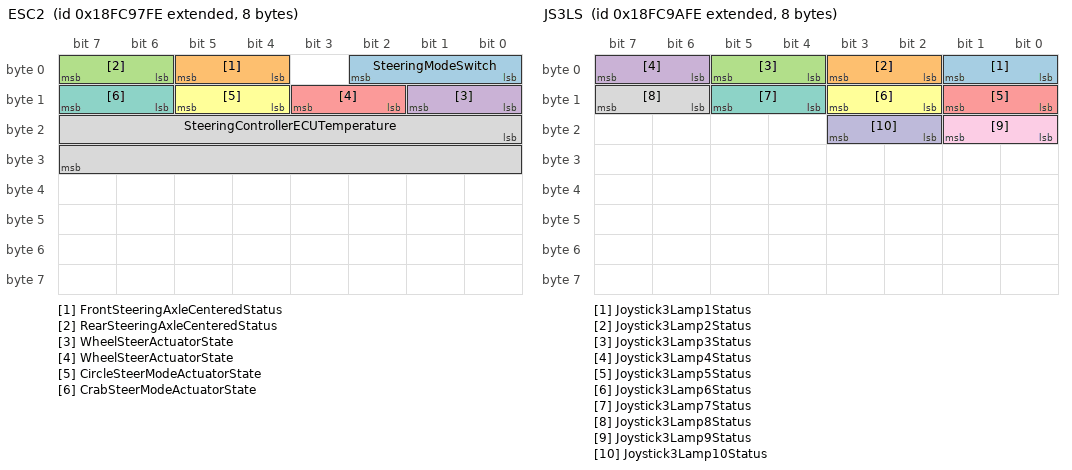
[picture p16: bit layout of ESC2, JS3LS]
BO_ 2566690814 ESC2: 8 Vector__XXX
SG_ SteeringModeSwitch : 0|3@1+ (1,0) [0|7] "" Vector__XXX
SG_ FrontSteeringAxleCenteredStatus : 4|2@1+ (1,0) [0|3] "" Vector__XXX
SG_ RearSteeringAxleCenteredStatus : 6|2@1+ (1,0) [0|3] "" Vector__XXX
SG_ WheelSteerActuatorState : 8|2@1+ (1,0) [0|3] "" Vector__XXX
SG_ WheelSteerActuatorState : 10|2@1+ (1,0) [0|3] "" Vector__XXX
SG_ CircleSteerModeActuatorState : 12|2@1+ (1,0) [0|3] "" Vector__XXX
SG_ CrabSteerModeActuatorState : 14|2@1+ (1,0) [0|3] "" Vector__XXX
SG_ SteeringControllerECUTemperature : 16|16@1+ (0.03125,-273) [-273|1734.96875] "deg C" Vector__XXX

BO_ 2499582206 VSL: 8 Vector__XXX
SG_ SoftTopSpeedLimitActive : 0|2@1+ (1,0) [0|3] "" Vector__XXX
SG_ SoftTopRatioLimitExceeded : 2|2@1+ (1,0) [0|3] "" Vector__XXX
SG_ SoftTopSpeedLimitRemainingDist : 8|16@1+ (1,0) [0|64255] "km" Vector__XXX
SG_ SoftTopSpeedLimitResetDistance : 24|16@1+ (1,0) [0|64255] "km" Vector__XXX
SG_ StTopSpdLmtRemainCntnsIntrvlDist : 40|16@1+ (1,0) [0|64255] "km" Vector__XXX

BO_ 2566691326 AUI: 201 Vector__XXX
SG_ NoAssemblyUnitIdentifyFields : 0|8@1+ (1,0) [0|250] "" Vector__XXX
SG_ AssemblyUnitIdentification : 15|1600@0+ (1,0) [0|0] "ASCII" Vector__XXX

BO_ 2566691582 JS3LS: 8 Vector__XXX
SG_ Joystick3Lamp1Status : 0|2@1+ (1,0) [0|3] "" Vector__XXX
SG_ Joystick3Lamp2Status : 2|2@1+ (1,0) [0|3] "" Vector__XXX
SG_ Joystick3Lamp3Status : 4|2@1+ (1,0) [0|3] "" Vector__XXX
SG_ Joystick3Lamp4Status : 6|2@1+ (1,0) [0|3] "" Vector__XXX
SG_ Joystick3Lamp5Status : 8|2@1+ (1,0) [0|3] "" Vector__XXX
SG_ Joystick3Lamp6Status : 10|2@1+ (1,0) [0|3] "" Vector__XXX
SG_ Joystick3Lamp7Status : 12|2@1+ (1,0) [0|3] "" Vector__XXX
SG_ Joystick3Lamp8Status : 14|2@1+ (1,0) [0|3] "" Vector__XXX
SG_ Joystick3Lamp9Status : 16|2@1+ (1,0) [0|3] "" Vector__XXX
SG_ Joystick3Lamp10Status : 18|2@1+ (1,0) [0|3] "" Vector__XXX

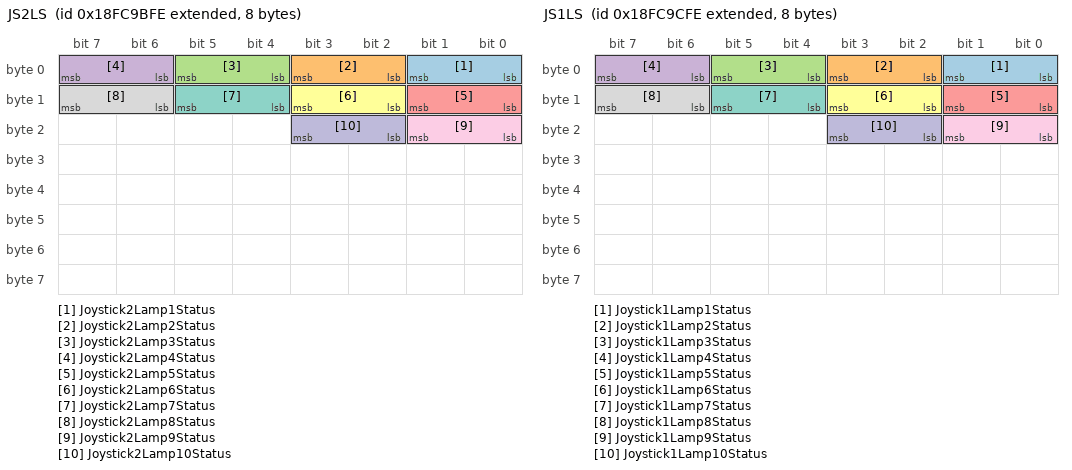
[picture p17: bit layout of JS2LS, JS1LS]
BO_ 2566691838 JS2LS: 8 Vector__XXX
SG_ Joystick2Lamp1Status : 0|2@1+ (1,0) [0|3] "" Vector__XXX
SG_ Joystick2Lamp2Status : 2|2@1+ (1,0) [0|3] "" Vector__XXX
SG_ Joystick2Lamp3Status : 4|2@1+ (1,0) [0|3] "" Vector__XXX
SG_ Joystick2Lamp4Status : 6|2@1+ (1,0) [0|3] "" Vector__XXX
SG_ Joystick2Lamp5Status : 8|2@1+ (1,0) [0|3] "" Vector__XXX
SG_ Joystick2Lamp6Status : 10|2@1+ (1,0) [0|3] "" Vector__XXX
SG_ Joystick2Lamp7Status : 12|2@1+ (1,0) [0|3] "" Vector__XXX
SG_ Joystick2Lamp8Status : 14|2@1+ (1,0) [0|3] "" Vector__XXX
SG_ Joystick2Lamp9Status : 16|2@1+ (1,0) [0|3] "" Vector__XXX
SG_ Joystick2Lamp10Status : 18|2@1+ (1,0) [0|3] "" Vector__XXX

BO_ 2566692094 JS1LS: 8 Vector__XXX
SG_ Joystick1Lamp1Status : 0|2@1+ (1,0) [0|3] "" Vector__XXX
SG_ Joystick1Lamp2Status : 2|2@1+ (1,0) [0|3] "" Vector__XXX
SG_ Joystick1Lamp3Status : 4|2@1+ (1,0) [0|3] "" Vector__XXX
SG_ Joystick1Lamp4Status : 6|2@1+ (1,0) [0|3] "" Vector__XXX
SG_ Joystick1Lamp5Status : 8|2@1+ (1,0) [0|3] "" Vector__XXX
SG_ Joystick1Lamp6Status : 10|2@1+ (1,0) [0|3] "" Vector__XXX
SG_ Joystick1Lamp7Status : 12|2@1+ (1,0) [0|3] "" Vector__XXX
SG_ Joystick1Lamp8Status : 14|2@1+ (1,0) [0|3] "" Vector__XXX
SG_ Joystick1Lamp9Status : 16|2@1+ (1,0) [0|3] "" Vector__XXX
SG_ Joystick1Lamp10Status : 18|2@1+ (1,0) [0|3] "" Vector__XXX

BO_ 2499583486 ETAPC: 8 Vector__XXX
SG_ EngineTimingActr1PositionCommand : 0|3@1+ (1,0) [0|7] "" Vector__XXX
SG_ EngineTimingActr2PositionCommand : 3|3@1+ (1,0) [0|7] "" Vector__XXX

BO_ 2499583742 ETAP: 8 Vector__XXX
SG_ EngineTimingActuator1 : 0|3@1+ (1,0) [0|7] "" Vector__XXX
SG_ EngineTimingActuator2 : 3|3@1+ (1,0) [0|7] "" Vector__XXX
SG_ EngTimingActr1RequestedPosition : 8|3@1+ (1,0) [0|7] "" Vector__XXX
SG_ EngTimingActr2RequestedPosition : 11|3@1+ (1,0) [0|7] "" Vector__XXX

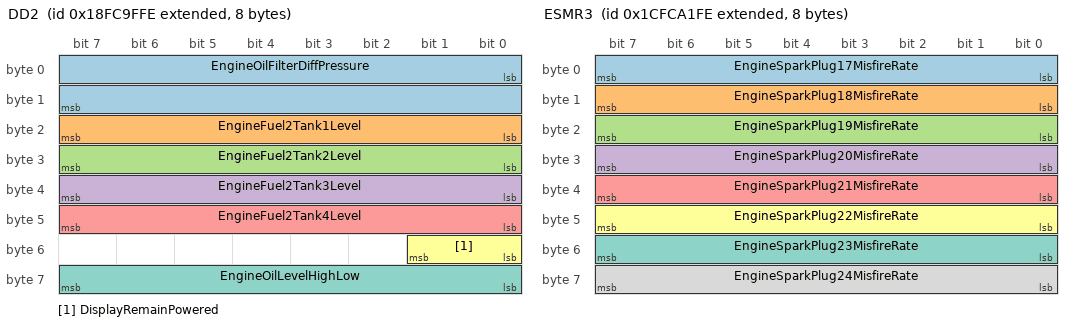
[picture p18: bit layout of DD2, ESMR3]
BO_ 2566692862 DD2: 8 Vector__XXX
SG_ EngineOilFilterDiffPressure : 0|16@1+ (0.0078125,-250) [-250|251.99] "kPa" Vector__XXX
SG_ EngineFuel2Tank1Level : 16|8@1+ (0.4,0) [0|100] "%" Vector__XXX
SG_ EngineFuel2Tank2Level : 24|8@1+ (0.4,0) [0|100] "%" Vector__XXX
SG_ EngineFuel2Tank3Level : 32|8@1+ (0.4,0) [0|100] "%" Vector__XXX
SG_ EngineFuel2Tank4Level : 40|8@1+ (0.4,0) [0|100] "%" Vector__XXX
SG_ DisplayRemainPowered : 48|2@1+ (1,0) [0|3] "" Vector__XXX
SG_ EngineOilLevelHighLow : 56|8@1+ (0.5,-62.5) [-62.5|62.5] "l" Vector__XXX

BO_ 2633801982 MFEH: 8 Vector__XXX
SG_ EngTotalHoursOfGaseousFuelOp : 0|32@1+ (0.05,0) [0|210554060.75] "h" Vector__XXX
SG_ EngTotalHoursOfDslFuelOperation : 32|32@1+ (0.05,0) [0|210554060.75] "h" Vector__XXX

BO_ 2633802238 ESMR3: 8 Vector__XXX
SG_ EngineSparkPlug17MisfireRate : 0|8@1+ (0.4,0) [0|100] "%" Vector__XXX
SG_ EngineSparkPlug18MisfireRate : 8|8@1+ (0.4,0) [0|100] "%" Vector__XXX
SG_ EngineSparkPlug19MisfireRate : 16|8@1+ (0.4,0) [0|100] "%" Vector__XXX
SG_ EngineSparkPlug20MisfireRate : 24|8@1+ (0.4,0) [0|100] "%" Vector__XXX
SG_ EngineSparkPlug21MisfireRate : 32|8@1+ (0.4,0) [0|100] "%" Vector__XXX
SG_ EngineSparkPlug22MisfireRate : 40|8@1+ (0.4,0) [0|100] "%" Vector__XXX
SG_ EngineSparkPlug23MisfireRate : 48|8@1+ (0.4,0) [0|100] "%" Vector__XXX
SG_ EngineSparkPlug24MisfireRate : 56|8@1+ (0.4,0) [0|100] "%" Vector__XXX

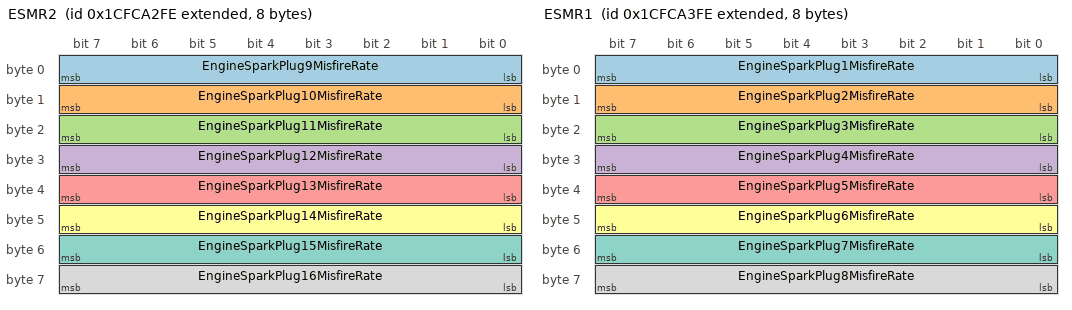
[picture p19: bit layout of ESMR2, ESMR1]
BO_ 2633802494 ESMR2: 8 Vector__XXX
SG_ EngineSparkPlug9MisfireRate : 0|8@1+ (0.4,0) [0|100] "%" Vector__XXX
SG_ EngineSparkPlug10MisfireRate : 8|8@1+ (0.4,0) [0|100] "%" Vector__XXX
SG_ EngineSparkPlug11MisfireRate : 16|8@1+ (0.4,0) [0|100] "%" Vector__XXX
SG_ EngineSparkPlug12MisfireRate : 24|8@1+ (0.4,0) [0|100] "%" Vector__XXX
SG_ EngineSparkPlug13MisfireRate : 32|8@1+ (0.4,0) [0|100] "%" Vector__XXX
SG_ EngineSparkPlug14MisfireRate : 40|8@1+ (0.4,0) [0|100] "%" Vector__XXX
SG_ EngineSparkPlug15MisfireRate : 48|8@1+ (0.4,0) [0|100] "%" Vector__XXX
SG_ EngineSparkPlug16MisfireRate : 56|8@1+ (0.4,0) [0|100] "%" Vector__XXX

BO_ 2633802750 ESMR1: 8 Vector__XXX
SG_ EngineSparkPlug1MisfireRate : 0|8@1+ (0.4,0) [0|100] "%" Vector__XXX
SG_ EngineSparkPlug2MisfireRate : 8|8@1+ (0.4,0) [0|100] "%" Vector__XXX
SG_ EngineSparkPlug3MisfireRate : 16|8@1+ (0.4,0) [0|100] "%" Vector__XXX
SG_ EngineSparkPlug4MisfireRate : 24|8@1+ (0.4,0) [0|100] "%" Vector__XXX
SG_ EngineSparkPlug5MisfireRate : 32|8@1+ (0.4,0) [0|100] "%" Vector__XXX
SG_ EngineSparkPlug6MisfireRate : 40|8@1+ (0.4,0) [0|100] "%" Vector__XXX
SG_ EngineSparkPlug7MisfireRate : 48|8@1+ (0.4,0) [0|100] "%" Vector__XXX
SG_ EngineSparkPlug8MisfireRate : 56|8@1+ (0.4,0) [0|100] "%" Vector__XXX

BO_ 2633803006 ESVMAX6: 8 Vector__XXX
SG_ EngineSparkPlug21MaximumVoltage : 0|16@1+ (1,0) [0|64255] "V" Vector__XXX
SG_ EngineSparkPlug22MaximumVoltage : 16|16@1+ (1,0) [0|64255] "V" Vector__XXX
SG_ EngineSparkPlug23MaximumVoltage : 32|16@1+ (1,0) [0|64255] "V" Vector__XXX
SG_ EngineSparkPlug24MaximumVoltage : 48|16@1+ (1,0) [0|64255] "V" Vector__XXX

BO_ 2633803262 ESVMAX5: 8 Vector__XXX
SG_ EngineSparkPlug17MaximumVoltage : 0|16@1+ (1,0) [0|64255] "V" Vector__XXX
SG_ EngineSparkPlug18MaximumVoltage : 16|16@1+ (1,0) [0|64255] "V" Vector__XXX
SG_ EngineSparkPlug19MaximumVoltage : 32|16@1+ (1,0) [0|64255] "V" Vector__XXX
SG_ EngineSparkPlug20MaximumVoltage : 48|16@1+ (1,0) [0|64255] "V" Vector__XXX

BO_ 2633803518 ESVMAX4: 8 Vector__XXX
SG_ EngineSparkPlug13MaximumVoltage : 0|16@1+ (1,0) [0|64255] "V" Vector__XXX
SG_ EngineSparkPlug14MaximumVoltage : 16|16@1+ (1,0) [0|64255] "V" Vector__XXX
SG_ EngineSparkPlug15MaximumVoltage : 32|16@1+ (1,0) [0|64255] "V" Vector__XXX
SG_ EngineSparkPlug16MaximumVoltage : 48|16@1+ (1,0) [0|64255] "V" Vector__XXX

BO_ 2633803774 ESVMAX3: 8 Vector__XXX
SG_ EngineSparkPlug9MaximumVoltage : 0|16@1+ (1,0) [0|64255] "V" Vector__XXX
SG_ EngineSparkPlug10MaximumVoltage : 16|16@1+ (1,0) [0|64255] "V" Vector__XXX
SG_ EngineSparkPlug11MaximumVoltage : 32|16@1+ (1,0) [0|64255] "V" Vector__XXX
SG_ EngineSparkPlug12MaximumVoltage : 48|16@1+ (1,0) [0|64255] "V" Vector__XXX

BO_ 2633804030 ESVMAX2: 8 Vector__XXX
SG_ EngineSparkPlug5MaximumVoltage : 0|16@1+ (1,0) [0|64255] "V" Vector__XXX
SG_ EngineSparkPlug6MaximumVoltage : 16|16@1+ (1,0) [0|64255] "V" Vector__XXX
SG_ EngineSparkPlug7MaximumVoltage : 32|16@1+ (1,0) [0|64255] "V" Vector__XXX
SG_ EngineSparkPlug8MaximumVoltage : 48|16@1+ (1,0) [0|64255] "V" Vector__XXX

BO_ 2633804286 ESVMAX1: 8 Vector__XXX
SG_ EngineSparkPlug1MaximumVoltage : 0|16@1+ (1,0) [0|64255] "V" Vector__XXX
SG_ EngineSparkPlug2MaximumVoltage : 16|16@1+ (1,0) [0|64255] "V" Vector__XXX
SG_ EngineSparkPlug3MaximumVoltage : 32|16@1+ (1,0) [0|64255] "V" Vector__XXX
SG_ EngineSparkPlug4MaximumVoltage : 48|16@1+ (1,0) [0|64255] "V" Vector__XXX

BO_ 2633804542 ESVMIN6: 8 Vector__XXX
SG_ EngineSparkPlug21MinimumVoltage : 0|16@1+ (1,0) [0|64255] "V" Vector__XXX
SG_ EngineSparkPlug22MinimumVoltage : 16|16@1+ (1,0) [0|64255] "V" Vector__XXX
SG_ EngineSparkPlug23MinimumVoltage : 32|16@1+ (1,0) [0|64255] "V" Vector__XXX
SG_ EngineSparkPlug24MinimumVoltage : 48|16@1+ (1,0) [0|64255] "V" Vector__XXX

BO_ 2633804798 ESVMIN5: 8 Vector__XXX
SG_ EngineSparkPlug17MinimumVoltage : 0|16@1+ (1,0) [0|64255] "V" Vector__XXX
SG_ EngineSparkPlug18MinimumVoltage : 16|16@1+ (1,0) [0|64255] "V" Vector__XXX
SG_ EngineSparkPlug19MinimumVoltage : 32|16@1+ (1,0) [0|64255] "V" Vector__XXX
SG_ EngineSparkPlug20MinimumVoltage : 48|16@1+ (1,0) [0|64255] "V" Vector__XXX

BO_ 2633805054 ESVMIN4: 8 Vector__XXX
SG_ EngineSparkPlug13MinimumVoltage : 0|16@1+ (1,0) [0|64255] "V" Vector__XXX
SG_ EngineSparkPlug14MinimumVoltage : 16|16@1+ (1,0) [0|64255] "V" Vector__XXX
SG_ EngineSparkPlug15MinimumVoltage : 32|16@1+ (1,0) [0|64255] "V" Vector__XXX
SG_ EngineSparkPlug16MinimumVoltage : 48|16@1+ (1,0) [0|64255] "V" Vector__XXX

BO_ 2633805310 ESVMIN3: 8 Vector__XXX
SG_ EngineSparkPlug9MinimumVoltage : 0|16@1+ (1,0) [0|64255] "V" Vector__XXX
SG_ EngineSparkPlug10MinimumVoltage : 16|16@1+ (1,0) [0|64255] "V" Vector__XXX
SG_ EngineSparkPlug11MinimumVoltage : 32|16@1+ (1,0) [0|64255] "V" Vector__XXX
SG_ EngineSparkPlug12MinimumVoltage : 48|16@1+ (1,0) [0|64255] "V" Vector__XXX

BO_ 2633805566 ESVMIN2: 8 Vector__XXX
SG_ EngineSparkPlug5MinimumVoltage : 0|16@1+ (1,0) [0|64255] "V" Vector__XXX
SG_ EngineSparkPlug6MinimumVoltage : 16|16@1+ (1,0) [0|64255] "V" Vector__XXX
SG_ EngineSparkPlug7MinimumVoltage : 32|16@1+ (1,0) [0|64255] "V" Vector__XXX
SG_ EngineSparkPlug8MinimumVoltage : 48|16@1+ (1,0) [0|64255] "V" Vector__XXX

BO_ 2633805822 ESVMIN1: 8 Vector__XXX
SG_ EngineSparkPlug1MinimumVoltage : 0|16@1+ (1,0) [0|64255] "V" Vector__XXX
SG_ EngineSparkPlug2MinimumVoltage : 16|16@1+ (1,0) [0|64255] "V" Vector__XXX
SG_ EngineSparkPlug3MinimumVoltage : 32|16@1+ (1,0) [0|64255] "V" Vector__XXX
SG_ EngineSparkPlug4MinimumVoltage : 48|16@1+ (1,0) [0|64255] "V" Vector__XXX

BO_ 2633806078 EICMH: 8 Vector__XXX
SG_ EngIgnitionCtrlModule1TimeRemain : 0|32@1+ (0.05,0) [0|210554060.75] "h" Vector__XXX
SG_ EngIgnitionCtrlModule2TimeRemain : 32|32@1+ (0.05,0) [0|210554060.75] "h" Vector__XXX

BO_ 2566697470 ICMSTS: 8 Vector__XXX
SG_ EngIgnitionCtrlModule1Temp : 0|8@1+ (1,-40) [-40|210] "deg C" Vector__XXX
SG_ EngIgnitionCtrlModule2Temp : 8|8@1+ (1,-40) [-40|210] "deg C" Vector__XXX
SG_ EngineIgnitionCtrlModule1State : 16|3@1+ (1,0) [0|7] "" Vector__XXX
SG_ EngineIgnitionCtrlModule2State : 19|3@1+ (1,0) [0|7] "" Vector__XXX

BO_ 2566697726 SPOC1: 64 Vector__XXX
SG_ SwitchedOutput1Current : 0|16@1+ (0.005,0) [0|321.275] "A" Vector__XXX
SG_ SwitchedOutput2Current : 16|16@1+ (0.005,0) [0|321.275] "A" Vector__XXX
SG_ SwitchedOutput3Current : 32|16@1+ (0.005,0) [0|321.275] "A" Vector__XXX
SG_ SwitchedOutput4Current : 48|16@1+ (0.005,0) [0|321.275] "A" Vector__XXX
SG_ SwitchedOutput5Current : 64|16@1+ (0.005,0) [0|321.275] "A" Vector__XXX
SG_ SwitchedOutput6Current : 80|16@1+ (0.005,0) [0|321.275] "A" Vector__XXX
SG_ SwitchedOutput7Current : 96|16@1+ (0.005,0) [0|321.275] "A" Vector__XXX
SG_ SwitchedOutput8Current : 112|16@1+ (0.005,0) [0|321.275] "A" Vector__XXX
SG_ SwitchedOutput9Current : 128|16@1+ (0.005,0) [0|321.275] "A" Vector__XXX
SG_ SwitchedOutput10Current : 144|16@1+ (0.005,0) [0|321.275] "A" Vector__XXX
SG_ SwitchedOutput11Current : 160|16@1+ (0.005,0) [0|321.275] "A" Vector__XXX
SG_ SwitchedOutput12Current : 176|16@1+ (0.005,0) [0|321.275] "A" Vector__XXX
SG_ SwitchedOutput13Current : 192|16@1+ (0.005,0) [0|321.275] "A" Vector__XXX
SG_ SwitchedOutput14Current : 208|16@1+ (0.005,0) [0|321.275] "A" Vector__XXX
SG_ SwitchedOutput15Current : 224|16@1+ (0.005,0) [0|321.275] "A" Vector__XXX
SG_ SwitchedOutput16Current : 240|16@1+ (0.005,0) [0|321.275] "A" Vector__XXX
SG_ SwitchedOutput17Current : 256|16@1+ (0.005,0) [0|321.275] "A" Vector__XXX
SG_ SwitchedOutput18Current : 272|16@1+ (0.005,0) [0|321.275] "A" Vector__XXX
SG_ SwitchedOutput19Current : 288|16@1+ (0.005,0) [0|321.275] "A" Vector__XXX
SG_ SwitchedOutput20Current : 304|16@1+ (0.005,0) [0|321.275] "A" Vector__XXX
SG_ SwitchedOutput21Current : 320|16@1+ (0.005,0) [0|321.275] "A" Vector__XXX
SG_ SwitchedOutput22Current : 336|16@1+ (0.005,0) [0|321.275] "A" Vector__XXX
SG_ SwitchedOutput23Current : 352|16@1+ (0.005,0) [0|321.275] "A" Vector__XXX
SG_ SwitchedOutput24Current : 368|16@1+ (0.005,0) [0|321.275] "A" Vector__XXX
SG_ SwitchedOutput25Current : 384|16@1+ (0.005,0) [0|321.275] "A" Vector__XXX
SG_ SwitchedOutput26Current : 400|16@1+ (0.005,0) [0|321.275] "A" Vector__XXX
SG_ SwitchedOutput27Current : 416|16@1+ (0.005,0) [0|321.275] "A" Vector__XXX
SG_ SwitchedOutput28Current : 432|16@1+ (0.005,0) [0|321.275] "A" Vector__XXX
SG_ SwitchedOutput29Current : 448|16@1+ (0.005,0) [0|321.275] "A" Vector__XXX
SG_ SwitchedOutput30Current : 464|16@1+ (0.005,0) [0|321.275] "A" Vector__XXX
SG_ SwitchedOutput31Current : 480|16@1+ (0.005,0) [0|321.275] "A" Vector__XXX
SG_ SwitchedOutput32Current : 496|16@1+ (0.005,0) [0|321.275] "A" Vector__XXX

BO_ 2566697982 FPOC: 64 Vector__XXX
SG_ FusedOutput1Current : 0|16@1+ (0.005,0) [0|321.275] "A" Vector__XXX
SG_ FusedOutput2Current : 16|16@1+ (0.005,0) [0|321.275] "A" Vector__XXX
SG_ FusedOutput3Current : 32|16@1+ (0.005,0) [0|321.275] "A" Vector__XXX
SG_ FusedOutput4Current : 48|16@1+ (0.005,0) [0|321.275] "A" Vector__XXX
SG_ FusedOutput5Current : 64|16@1+ (0.005,0) [0|321.275] "A" Vector__XXX
SG_ FusedOutput6Current : 80|16@1+ (0.005,0) [0|321.275] "A" Vector__XXX
SG_ FusedOutput7Current : 96|16@1+ (0.005,0) [0|321.275] "A" Vector__XXX
SG_ FusedOutput8Current : 112|16@1+ (0.005,0) [0|321.275] "A" Vector__XXX
SG_ FusedOutput9Current : 128|16@1+ (0.005,0) [0|321.275] "A" Vector__XXX
SG_ FusedOutput10Current : 144|16@1+ (0.005,0) [0|321.275] "A" Vector__XXX
SG_ FusedOutput11Current : 160|16@1+ (0.005,0) [0|321.275] "A" Vector__XXX
SG_ FusedOutput12Current : 176|16@1+ (0.005,0) [0|321.275] "A" Vector__XXX
SG_ FusedOutput13Current : 192|16@1+ (0.005,0) [0|321.275] "A" Vector__XXX
SG_ FusedOutput14Current : 208|16@1+ (0.005,0) [0|321.275] "A" Vector__XXX
SG_ FusedOutput15Current : 224|16@1+ (0.005,0) [0|321.275] "A" Vector__XXX
SG_ FusedOutput16Current : 240|16@1+ (0.005,0) [0|321.275] "A" Vector__XXX
SG_ FusedOutput17Current : 256|16@1+ (0.005,0) [0|321.275] "A" Vector__XXX
SG_ FusedOutput18Current : 272|16@1+ (0.005,0) [0|321.275] "A" Vector__XXX
SG_ FusedOutput19Current : 288|16@1+ (0.005,0) [0|321.275] "A" Vector__XXX
SG_ FusedOutput20Current : 304|16@1+ (0.005,0) [0|321.275] "A" Vector__XXX
SG_ FusedOutput21Current : 320|16@1+ (0.005,0) [0|321.275] "A" Vector__XXX
SG_ FusedOutput22Current : 336|16@1+ (0.005,0) [0|321.275] "A" Vector__XXX
SG_ FusedOutput23Current : 352|16@1+ (0.005,0) [0|321.275] "A" Vector__XXX
SG_ FusedOutput24Current : 368|16@1+ (0.005,0) [0|321.275] "A" Vector__XXX
SG_ FusedOutput25Current : 384|16@1+ (0.005,0) [0|321.275] "A" Vector__XXX
SG_ FusedOutput26Current : 400|16@1+ (0.005,0) [0|321.275] "A" Vector__XXX
SG_ FusedOutput27Current : 416|16@1+ (0.005,0) [0|321.275] "A" Vector__XXX
SG_ FusedOutput28Current : 432|16@1+ (0.005,0) [0|321.275] "A" Vector__XXX
SG_ FusedOutput29Current : 448|16@1+ (0.005,0) [0|321.275] "A" Vector__XXX
SG_ FusedOutput30Current : 464|16@1+ (0.005,0) [0|321.275] "A" Vector__XXX
SG_ FusedOutput31Current : 480|16@1+ (0.005,0) [0|321.275] "A" Vector__XXX
SG_ FusedOutput32Current : 496|16@1+ (0.005,0) [0|321.275] "A" Vector__XXX

CM_ BO_ 2633750526 "Configurable Transmit PGNs Status";
CM_ BO_ 2365315326 "DC/DC Converter 1 Temperatures";
CM_ BO_ 2365315582 "DC/DC Converter 1 Low Side Limits";
CM_ BO_ 2365315838 "DC/DC Converter 1 High Side Limits";
CM_ BO_ 2566642686 "Reserved for Diagnostic Message";
CM_ BO_ 2566642942 "Door Control 4";
CM_ BO_ 2566643198 "Door Control 3";
CM_ BO_ 2566643454 "Engine Temperature 6";
CM_ BO_ 2566643710 "Intake/Exhaust Conditions 3";
CM_ BO_ 2633752830 "Aftercooler and Oil Cooler Fluids 1";
CM_ BO_ 2633753086 "Diode Temperature 2";
CM_ BO_ 2633753342 "Diode Temperature 1";
CM_ BO_ 2633753598 "Alternator Temperature 2";
CM_ BO_ 2566644990 "Fuel Information 7 (Gaseous)";
CM_ BO_ 2566645246 "High Voltage Energy Storage Fan Status";
CM_ BO_ 2365318910 "High Voltage Energy Storage Fan Commands";
CM_ BO_ 2633754622 "SCR Operator Inducement Information 5";
CM_ BO_ 2633754878 "Aftertreatment System Information 2";
CM_ BO_ 2633755134 "Ethernet 1 Connection Information 2";
CM_ BO_ 2633755390 "Ethernet 1 Connection Information 1";
CM_ BO_ 2566646782 "Oil Debris Monitor Counts Ferrous Bins 1 & 2";
CM_ BO_ 2566647038 "Oil Debris Monitor Counts Ferrous Bins 3 & 4";
CM_ BO_ 2566647294 "Oil Debris Monitor Counts Ferrous Bins 5 & 6";
CM_ BO_ 2566647550 "Oil Debris Monitor Counts Non-Ferrous Bins 1 & 2";
CM_ BO_ 2566647806 "Oil Debris Monitor Counts Non-Ferrous Bins 3 & 4";
CM_ BO_ 2566648062 "Oil Debris Monitor Counts Non-Ferrous Bins 5 & 6";
CM_ BO_ 2566648318 "Oil Debris Monitoring System Status";
CM_ BO_ 2365322238 "Cruise Control / Vehicle Speed 5";
CM_ BO_ 2566649086 "Aftertreatment 2 Diesel Oxidation Catalyst 2";
CM_ BO_ 2566649342 "Aftertreatment 1 Diesel Oxidation Catalyst 2";
CM_ BO_ 2566649598 "Vehicle Position 2";
CM_ BO_ 2566649854 "Electrified Accessory Propulsion Motor Coolant Fan 3 Status";
CM_ BO_ 2566650110 "Electrified Accessory Propulsion Motor Coolant Fan 2 Status";
CM_ BO_ 2566650366 "Electrified Accessory Propulsion Motor Coolant Fan 1 Status";
CM_ BO_ 2566650622 "Electrified Accessory Power Electronics Coolant Fan 3 Status";
CM_ BO_ 2566650878 "Electrified Accessory Power Electronics Coolant Fan 2 Status";
CM_ BO_ 2566651134 "Electrified Accessory Power Electronics Coolant Fan 1 Status";
CM_ BO_ 2566651390 "Electrified Accessory Propulsion Motor Oil Pump Status";
CM_ BO_ 2566651646 "Electrified Accessory Propulsion Motor Coolant Pump Status";
CM_ BO_ 2566651902 "Electrified Accessory Power Electronics Coolant Pump Status";
CM_ BO_ 2566652414 "Electrified Accessory Motor Status";
CM_ BO_ 2566652670 "SCR System Information";
CM_ BO_ 2566652926 "Vehicle Electrical Power 14";
CM_ BO_ 2566653182 "Vehicle Electrical Power 13";
CM_ BO_ 2566653438 "Vehicle Electrical Power 12";
CM_ BO_ 2566653694 "Vehicle Electrical Power 11";
CM_ BO_ 2566653950 "Vehicle Electrical Power 10";
CM_ BO_ 2566654206 "Vehicle Electrical Power 9";
CM_ BO_ 2566654462 "Vehicle Electrical Power 8";
CM_ BO_ 2566654718 "Vehicle Electrical Power 7";
CM_ BO_ 2566654974 "Electronic Engine Controller 20";
CM_ BO_ 2633764094 "Evaporative Systems";
CM_ BO_ 2633764350 "Fire Pump Statistics 1";
CM_ BO_ 2566655742 "Primary or Rear Hitch Roll and Pitch Sensitivity";
CM_ BO_ 2566655998 "Secondary or Front Hitch Roll and Pitch Sensitivity";
CM_ BO_ 2566656254 "Ambient Conditions 3";
CM_ BO_ 2566656510 "Total Gaseous Fuel Information";
CM_ BO_ 2499547902 "Cab Door Control";
CM_ BO_ 2499548158 "Door Latch Status";
CM_ BO_ 2499548670 "Vehicle Electrical Power 6";
CM_ BO_ 2499548926 "Payload Temperature 2";
CM_ BO_ 2499549182 "Payload Temperature 1";
CM_ BO_ 2566658302 "Payload System Totals 2";
CM_ BO_ 2566658558 "Payload System Totals 1";
CM_ BO_ 2633769726 "Electronic Engine Controller 19";
CM_ BO_ 2566661118 "Fuel Consumption (Liquid) 2";
CM_ BO_ 2566661374 "Aftertreatment 2 Diesel Exhaust Fluid Tank 1 Information 2";
CM_ BO_ 2566661630 "Aftertreatment 1 Diesel Exhaust Fluid Tank 1 Information 2";
CM_ BO_ 2566661886 "Aftertreatment 2 Diesel Exhaust Fluid Information 2";
CM_ BO_ 2566662142 "Aftertreatment 1 Diesel Exhaust Fluid Information 2";
CM_ BO_ 2566662654 "Forward Lane Image 3";
CM_ BO_ 2566662910 "Operator Inducement Information";
CM_ BO_ 2566663166 "Cruise Control / Vehicle Speed 4";
CM_ BO_ 2566663422 "Brake Caliper Lining Clearance";
CM_ BO_ 2566663678 "Alternate Fuel 5";
CM_ BO_ 2566663934 "Engine Turbocharger Control 3";
CM_ BO_ 2633773054 "Fire Suppression Agent Status";
CM_ BO_ 2633773310 "SCR Operator Inducement Information 4";
CM_ BO_ 2566664702 "Aftertreatment System Information 1";
CM_ BO_ 2499556094 "Aftertreatment 1 Particulate Sensor Information 3";
CM_ BO_ 2499556350 "Engine Fuel Injector Metering Rail Pressure Information 3";
CM_ BO_ 2499556606 "Engine Fuel Injector Metering Rail Pressure Information 2";
CM_ BO_ 2566665726 "Aftertreatment 2 Diesel Exhaust Fluid Pump 1 Information";
CM_ BO_ 2499557118 "Gaseous Fuel Supply Valve Information";
CM_ BO_ 2499557374 "Engine Oil Mist Detection Information 2";
CM_ BO_ 2499557630 "Engine Oil Mist Detection Information 1";
CM_ BO_ 2499557886 "Gaseous Fuel Supply Pressure 2";
CM_ BO_ 2499558142 "Gaseous Fuel Supply Pressure 1";
CM_ BO_ 2566667262 "Engine End Bearing Temperature 3";
CM_ BO_ 2566667518 "Engine End Bearing Temperature 2";
CM_ BO_ 2566667774 "Engine End Bearing Temperature 1";
CM_ BO_ 2566668030 "Heat Exchanger Debris Purge Information";
CM_ BO_ 2566668286 "Engine Turbocharger Control 2";
CM_ BO_ 2566668542 "Engine Hydraulic Fuel 2 Pump Status";
CM_ BO_ 2566668798 "Alternate Fuel 4";
CM_ BO_ 2566669054 "Tire Condition Message 2";
CM_ BO_ 2566669310 "Tire Configuration Status Information";
CM_ BO_ 2566669822 "Tire Wireless Signal Strength Indicator";
CM_ BO_ 2566670078 "Tire Sensor Identification Status";
CM_ BO_ 2566670334 "Monitored Tire Information";
CM_ BO_ 2566670590 "Aftertreatment 2 Historical Information 2";
CM_ BO_ 2566670846 "Aftertreatment 1 Historical Information 2";
CM_ BO_ 2566671102 "SCR System Cleaning";
CM_ BO_ 2566671358 "Electronic Engine Controller 17";
CM_ BO_ 2566671614 "SCR Operator Inducement Information 3";
CM_ BO_ 2566671870 "Aftertreatment 2 SCR Dosing System Information 3";
CM_ BO_ 2566672126 "Aftertreatment 1 SCR Dosing System Information 3";
CM_ BO_ 2566672382 "Payload Weight Sensor Information";
CM_ BO_ 2566672638 "Payload System Status";
CM_ BO_ 2365346302 "Air Suspension Control 7";
CM_ BO_ 2633782014 "Bin Weight and Lift Count";
CM_ BO_ 2566673406 "Engine Gaseous Leakage Information";
CM_ BO_ 2566674174 "SCR Operator Inducement Information 2";
CM_ BO_ 2566674430 "SCR Operator Inducement Information 1";
CM_ BO_ 2566674686 "Turbocharger Information 7";
CM_ BO_ 2365348350 "Engine Load Sharing Information";
CM_ BO_ 2566675966 "High Voltage Energy Storage 1 Configuration";
CM_ BO_ 2633785086 "High Voltage Energy Storage 1 History";
CM_ BO_ 2566687742 "Aftertreatment 1 Particulate Sensor Information 2";
CM_ BO_ 2566687998 "Aftertreatment 1 Particulate Sensor Information 1";
CM_ BO_ 2432471038 "Alternate Fuel 3";
CM_ BO_ 2499580158 "Engine Fuel Injector Metering Rail Pressure Information 1";
CM_ BO_ 2566689278 "Engine Exhaust NOx";
CM_ BO_ 2566689534 "Air Fuel Ratio";
CM_ BO_ 2566689790 "Gaseous Fuel Pressure 2";
CM_ BO_ 2566690046 "Aftertreatment System Abuse Information";
CM_ BO_ 2365363710 "Engine Cylinder Pressure Monitor Status Information";
CM_ BO_ 2566690558 "Engine Information 2";
CM_ BO_ 2566690814 "Electronic Steering Control 2";
CM_ BO_ 2499582206 "Vehicle Speed Limiter";
CM_ BO_ 2566691326 "Assembly Unit Identification";
CM_ BO_ 2566691582 "Joystick 3 Lamp Status";
CM_ BO_ 2566691838 "Joystick 2 Lamp Status";
CM_ BO_ 2566692094 "Joystick 1 Lamp Status";
CM_ BO_ 2499583486 "Engine Timing Actuator Position Command";
CM_ BO_ 2499583742 "Engine Timing Actuator Position";
CM_ BO_ 2566692862 "Dash Display 2";
CM_ BO_ 2633801982 "Multi-fuel Engine Hours";
CM_ BO_ 2633802238 "Engine Spark Misfire Rate 3";
CM_ BO_ 2633802494 "Engine Spark Misfire Rate 2";
CM_ BO_ 2633802750 "Engine Spark Misfire Rate 1";
CM_ BO_ 2633803006 "Engine Spark Maximum Voltage 6";
CM_ BO_ 2633803262 "Engine Spark Maximum Voltage 5";
CM_ BO_ 2633803518 "Engine Spark Maximum Voltage 4";
CM_ BO_ 2633803774 "Engine Spark Maximum Voltage 3";
CM_ BO_ 2633804030 "Engine Spark Maximum Voltage 2";
CM_ BO_ 2633804286 "Engine Spark Maximum Voltage 1";
CM_ BO_ 2633804542 "Engine Spark Minimum Voltage 6";
CM_ BO_ 2633804798 "Engine Spark Minimum Voltage 5";
CM_ BO_ 2633805054 "Engine Spark Minimum Voltage 4";
CM_ BO_ 2633805310 "Engine Spark Minimum Voltage 3";
CM_ BO_ 2633805566 "Engine Spark Minimum Voltage 2";
CM_ BO_ 2633805822 "Engine Spark Minimum Voltage 1";
CM_ BO_ 2633806078 "Engine Ignition Controller Maintenance Hours";
CM_ BO_ 2566697470 "Engine Ignition Control Module Status";
CM_ BO_ 2566697726 "Switched Power Output Current";
CM_ BO_ 2566697982 "Fused Power Output Current";
BA_DEF_ BO_  "VFrameFormat" ENUM  "StandardCAN","ExtendedCAN","reserved","J1939PG";
BA_DEF_ BO_  "GenMsgCycleTime" INT 0 65535;
BA_DEF_ SG_  "GenSigStartValue" FLOAT -3.4E+038 3.4E+038;
BA_DEF_ SG_  "SPN" INT ;
BA_DEF_ SG_  "SigType" ENUM "Default","Range","RangeSigned","ASCII","Discrete","Control","ReferencePGN","DTC","StringDelimiter","StringLength","StringLengthControl","MessageCounter","MessageChecksum";
BA_DEF_DEF_  "VFrameFormat" "J1939PG";
BA_DEF_DEF_  "GenMsgCycleTime" 0;
BA_DEF_DEF_  "GenSigStartValue" 0;
BA_DEF_DEF_  "SPN" 0;
BA_DEF_DEF_  "SigType" "Default";
BA_ "GenMsgCycleTime" BO_ 2365315326 1000;
BA_ "GenMsgCycleTime" BO_ 2365315582 1000;
BA_ "GenMsgCycleTime" BO_ 2365315838 1000;
BA_ "GenMsgCycleTime" BO_ 2566642942 1000;
BA_ "GenMsgCycleTime" BO_ 2566643198 1000;
BA_ "GenMsgCycleTime" BO_ 2566643454 1000;
BA_ "GenMsgCycleTime" BO_ 2566643710 500;
BA_ "GenMsgCycleTime" BO_ 2633752830 1000;
BA_ "GenMsgCycleTime" BO_ 2633753086 1000;
BA_ "GenMsgCycleTime" BO_ 2633753342 1000;
BA_ "GenMsgCycleTime" BO_ 2633753598 1000;
BA_ "GenMsgCycleTime" BO_ 2566644990 500;
BA_ "GenMsgCycleTime" BO_ 2566645246 1000;
BA_ "GenMsgCycleTime" BO_ 2365318910 1000;
BA_ "GenMsgCycleTime" BO_ 2633754622 10000;
BA_ "GenMsgCycleTime" BO_ 2566646782 10000;
BA_ "GenMsgCycleTime" BO_ 2566647038 10000;
BA_ "GenMsgCycleTime" BO_ 2566647294 10000;
BA_ "GenMsgCycleTime" BO_ 2566647550 10000;
BA_ "GenMsgCycleTime" BO_ 2566647806 10000;
BA_ "GenMsgCycleTime" BO_ 2566648062 10000;
BA_ "GenMsgCycleTime" BO_ 2566648318 30000;
BA_ "GenMsgCycleTime" BO_ 2365322238 100;
BA_ "GenMsgCycleTime" BO_ 2566649086 500;
BA_ "GenMsgCycleTime" BO_ 2566649342 500;
BA_ "GenMsgCycleTime" BO_ 2566649598 5000;
BA_ "GenMsgCycleTime" BO_ 2566649854 1000;
BA_ "GenMsgCycleTime" BO_ 2566650110 1000;
BA_ "GenMsgCycleTime" BO_ 2566650366 1000;
BA_ "GenMsgCycleTime" BO_ 2566650622 1000;
BA_ "GenMsgCycleTime" BO_ 2566650878 1000;
BA_ "GenMsgCycleTime" BO_ 2566651134 1000;
BA_ "GenMsgCycleTime" BO_ 2566651390 1000;
BA_ "GenMsgCycleTime" BO_ 2566651646 1000;
BA_ "GenMsgCycleTime" BO_ 2566651902 1000;
BA_ "GenMsgCycleTime" BO_ 2566652414 1000;
BA_ "GenMsgCycleTime" BO_ 2566652670 10000;
BA_ "GenMsgCycleTime" BO_ 2566652926 1000;
BA_ "GenMsgCycleTime" BO_ 2566653182 100;
BA_ "GenMsgCycleTime" BO_ 2566653438 1000;
BA_ "GenMsgCycleTime" BO_ 2566653694 100;
BA_ "GenMsgCycleTime" BO_ 2566653950 1000;
BA_ "GenMsgCycleTime" BO_ 2566654206 100;
BA_ "GenMsgCycleTime" BO_ 2566654462 1000;
BA_ "GenMsgCycleTime" BO_ 2566654718 100;
BA_ "GenMsgCycleTime" BO_ 2566654974 250;
BA_ "GenMsgCycleTime" BO_ 2633764094 1000;
BA_ "GenMsgCycleTime" BO_ 2566655742 1000;
BA_ "GenMsgCycleTime" BO_ 2566655998 1000;
BA_ "GenMsgCycleTime" BO_ 2566656254 1000;
BA_ "GenMsgCycleTime" BO_ 2499547902 1000;
BA_ "GenMsgCycleTime" BO_ 2499548158 1000;
BA_ "GenMsgCycleTime" BO_ 2499548670 100;
BA_ "GenMsgCycleTime" BO_ 2499548926 1000;
BA_ "GenMsgCycleTime" BO_ 2499549182 1000;
BA_ "GenMsgCycleTime" BO_ 2566658302 5000;
BA_ "GenMsgCycleTime" BO_ 2566658558 5000;
BA_ "GenMsgCycleTime" BO_ 2566661374 1000;
BA_ "GenMsgCycleTime" BO_ 2566661630 1000;
BA_ "GenMsgCycleTime" BO_ 2566661886 1000;
BA_ "GenMsgCycleTime" BO_ 2566662142 1000;
BA_ "GenMsgCycleTime" BO_ 2566662654 100;
BA_ "GenMsgCycleTime" BO_ 2566662910 10000;
BA_ "GenMsgCycleTime" BO_ 2566663166 1000;
BA_ "GenMsgCycleTime" BO_ 2566663422 1000;
BA_ "GenMsgCycleTime" BO_ 2566663678 500;
BA_ "GenMsgCycleTime" BO_ 2566663934 500;
BA_ "GenMsgCycleTime" BO_ 2633773054 1000;
BA_ "GenMsgCycleTime" BO_ 2566664702 1000;
BA_ "GenMsgCycleTime" BO_ 2499556094 250;
BA_ "GenMsgCycleTime" BO_ 2499556350 500;
BA_ "GenMsgCycleTime" BO_ 2499556606 500;
BA_ "GenMsgCycleTime" BO_ 2566665726 500;
BA_ "GenMsgCycleTime" BO_ 2499557118 500;
BA_ "GenMsgCycleTime" BO_ 2499557374 500;
BA_ "GenMsgCycleTime" BO_ 2499557630 500;
BA_ "GenMsgCycleTime" BO_ 2499557886 500;
BA_ "GenMsgCycleTime" BO_ 2499558142 500;
BA_ "GenMsgCycleTime" BO_ 2566667262 1000;
BA_ "GenMsgCycleTime" BO_ 2566667518 1000;
BA_ "GenMsgCycleTime" BO_ 2566667774 1000;
BA_ "GenMsgCycleTime" BO_ 2566668030 1000;
BA_ "GenMsgCycleTime" BO_ 2566668542 500;
BA_ "GenMsgCycleTime" BO_ 2566668798 500;
BA_ "GenMsgCycleTime" BO_ 2566669054 10000;
BA_ "GenMsgCycleTime" BO_ 2566671102 1000;
BA_ "GenMsgCycleTime" BO_ 2566671870 500;
BA_ "GenMsgCycleTime" BO_ 2566672126 500;
BA_ "GenMsgCycleTime" BO_ 2566672382 1000;
BA_ "GenMsgCycleTime" BO_ 2566672638 1000;
BA_ "GenMsgCycleTime" BO_ 2365346302 100;
BA_ "GenMsgCycleTime" BO_ 2633782014 10000;
BA_ "GenMsgCycleTime" BO_ 2566673406 500;
BA_ "GenMsgCycleTime" BO_ 2566674174 10000;
BA_ "GenMsgCycleTime" BO_ 2566674430 10000;
BA_ "GenMsgCycleTime" BO_ 2566674686 1000;
BA_ "GenMsgCycleTime" BO_ 2365348350 500;
BA_ "GenMsgCycleTime" BO_ 2566687742 200;
BA_ "GenMsgCycleTime" BO_ 2566687998 200;
BA_ "GenMsgCycleTime" BO_ 2432471038 100;
BA_ "GenMsgCycleTime" BO_ 2499580158 500;
BA_ "GenMsgCycleTime" BO_ 2566690046 1000;
BA_ "GenMsgCycleTime" BO_ 2365363710 100;
BA_ "GenMsgCycleTime" BO_ 2566690558 100;
BA_ "GenMsgCycleTime" BO_ 2566690814 500;
BA_ "GenMsgCycleTime" BO_ 2499582206 500;
BA_ "GenMsgCycleTime" BO_ 2499583486 1000;
BA_ "GenMsgCycleTime" BO_ 2499583742 1000;
BA_ "GenMsgCycleTime" BO_ 2566692862 1000;
BA_ "GenMsgCycleTime" BO_ 2566697470 100;
BA_ "SPN" SG_ 2633750526 TransmitPGNsPort 8599;
BA_ "SPN" SG_ 2633750526 TransmitPGNsPortPendingChangesSt 8600;
BA_ "SPN" SG_ 2633750526 TransmitPGNsPortCommandStatus 8601;
BA_ "SPN" SG_ 2633750526 ConfigurableTransmitPGN 8602;
BA_ "SPN" SG_ 2633750526 ConfigurableTransPGNCurTransmtSt 8603;
BA_ "SPN" SG_ 2633750526 ConfigurableTransPGNPendngChgSt 8604;
BA_ "SPN" SG_ 2633750526 ConfigurableTransmtPGNModifiedSt 8605;
BA_ "SPN" SG_ 2365315326 DCDC1ConverterTemperature 8592;
BA_ "SPN" SG_ 2365315326 DCDC1CnvElctrncFilterTemperature 8593;
BA_ "SPN" SG_ 2365315326 DCDC1PowerElectronicsTemperature 8594;
BA_ "SPN" SG_ 2365315326 DCDC1CoolantInTemperature 8822;
BA_ "SPN" SG_ 2365315326 DCDC1CoolantOutTemperature 8823;
BA_ "SPN" SG_ 2365315582 DCDC1LowSideVoltageMinLmtRequest 8566;
BA_ "SPN" SG_ 2365315582 DCDC1LowSideVoltageMaxLmtRequest 8567;
BA_ "SPN" SG_ 2365315582 DCDC1LowSideCurrMaxLmtRequest 8568;
BA_ "SPN" SG_ 2365315838 DCDC1HghSideVoltageMinLmtRequest 8563;
BA_ "SPN" SG_ 2365315838 DCDC1HghSideVoltageMaxLmtRequest 8564;
BA_ "SPN" SG_ 2365315838 DCDC1HghSideCurrMaxLmtRequest 8565;
BA_ "SPN" SG_ 2566642942 LockStatusOfDoor21 8525;
BA_ "SPN" SG_ 2566642942 OpenStatusOfDoor21 8526;
BA_ "SPN" SG_ 2566642942 EnableStatusOfDoor21 8527;
BA_ "SPN" SG_ 2566642942 LockStatusOfDoor22 8528;
BA_ "SPN" SG_ 2566642942 OpenStatusOfDoor22 8529;
BA_ "SPN" SG_ 2566642942 EnableStatusOfDoor22 8530;
BA_ "SPN" SG_ 2566642942 LockStatusOfDoor23 8531;
BA_ "SPN" SG_ 2566642942 OpenStatusOfDoor23 8532;
BA_ "SPN" SG_ 2566642942 EnableStatusOfDoor23 8533;
BA_ "SPN" SG_ 2566642942 LockStatusOfDoor24 8534;
BA_ "SPN" SG_ 2566642942 OpenStatusOfDoor24 8535;
BA_ "SPN" SG_ 2566642942 EnableStatusOfDoor24 8536;
BA_ "SPN" SG_ 2566642942 LockStatusOfDoor25 8537;
BA_ "SPN" SG_ 2566642942 OpenStatusOfDoor25 8538;
BA_ "SPN" SG_ 2566642942 EnableStatusOfDoor25 8539;
BA_ "SPN" SG_ 2566642942 LockStatusOfDoor26 8540;
BA_ "SPN" SG_ 2566642942 OpenStatusOfDoor26 8541;
BA_ "SPN" SG_ 2566642942 EnableStatusOfDoor26 8542;
BA_ "SPN" SG_ 2566642942 LockStatusOfDoor27 8543;
BA_ "SPN" SG_ 2566642942 OpenStatusOfDoor27 8544;
BA_ "SPN" SG_ 2566642942 EnableStatusOfDoor27 8545;
BA_ "SPN" SG_ 2566642942 LockStatusOfDoor28 8546;
BA_ "SPN" SG_ 2566642942 OpenStatusOfDoor28 8547;
BA_ "SPN" SG_ 2566642942 EnableStatusOfDoor28 8548;
BA_ "SPN" SG_ 2566642942 LockStatusOfDoor29 8549;
BA_ "SPN" SG_ 2566642942 OpenStatusOfDoor29 8550;
BA_ "SPN" SG_ 2566642942 EnableStatusOfDoor29 8551;
BA_ "SPN" SG_ 2566642942 LockStatusOfDoor30 8552;
BA_ "SPN" SG_ 2566642942 OpenStatusOfDoor30 8553;
BA_ "SPN" SG_ 2566642942 EnableStatusOfDoor30 8554;
BA_ "SPN" SG_ 2566643198 LockStatusOfDoor11 8495;
BA_ "SPN" SG_ 2566643198 OpenStatusOfDoor11 8496;
BA_ "SPN" SG_ 2566643198 EnableStatusOfDoor11 8497;
BA_ "SPN" SG_ 2566643198 LockStatusOfDoor12 8498;
BA_ "SPN" SG_ 2566643198 OpenStatusOfDoor12 8499;
BA_ "SPN" SG_ 2566643198 EnableStatusOfDoor12 8500;
BA_ "SPN" SG_ 2566643198 LockStatusOfDoor13 8501;
BA_ "SPN" SG_ 2566643198 OpenStatusOfDoor13 8502;
BA_ "SPN" SG_ 2566643198 EnableStatusOfDoor13 8503;
BA_ "SPN" SG_ 2566643198 LockStatusOfDoor14 8504;
BA_ "SPN" SG_ 2566643198 OpenStatusOfDoor14 8505;
BA_ "SPN" SG_ 2566643198 EnableStatusOfDoor14 8506;
BA_ "SPN" SG_ 2566643198 LockStatusOfDoor15 8507;
BA_ "SPN" SG_ 2566643198 OpenStatusOfDoor15 8508;
BA_ "SPN" SG_ 2566643198 EnableStatusOfDoor15 8509;
BA_ "SPN" SG_ 2566643198 LockStatusOfDoor16 8510;
BA_ "SPN" SG_ 2566643198 OpenStatusOfDoor16 8511;
BA_ "SPN" SG_ 2566643198 EnableStatusOfDoor16 8512;
BA_ "SPN" SG_ 2566643198 LockStatusOfDoor17 8513;
BA_ "SPN" SG_ 2566643198 OpenStatusOfDoor17 8514;
BA_ "SPN" SG_ 2566643198 EnableStatusOfDoor17 8515;
BA_ "SPN" SG_ 2566643198 LockStatusOfDoor18 8516;
BA_ "SPN" SG_ 2566643198 OpenStatusOfDoor18 8517;
BA_ "SPN" SG_ 2566643198 EnableStatusOfDoor18 8518;
BA_ "SPN" SG_ 2566643198 LockStatusOfDoor19 8519;
BA_ "SPN" SG_ 2566643198 OpenStatusOfDoor19 8520;
BA_ "SPN" SG_ 2566643198 EnableStatusOfDoor19 8521;
BA_ "SPN" SG_ 2566643198 LockStatusOfDoor20 8522;
BA_ "SPN" SG_ 2566643198 OpenStatusOfDoor20 8523;
BA_ "SPN" SG_ 2566643198 EnableStatusOfDoor20 8524;
BA_ "SPN" SG_ 2566643454 EngChrgAirCoolIntkCoolntTemp 8487;
BA_ "SPN" SG_ 2566643454 EngChrgAirCoolOtltCoolntTemp 8488;
BA_ "SPN" SG_ 2566643454 EngineIntakeCoolantTemperature 8489;
BA_ "SPN" SG_ 2566643710 EngineMixerIntakePressure 8477;
BA_ "SPN" SG_ 2566643710 EngineMixer2IntakePressure 8607;
BA_ "SPN" SG_ 2633752830 AltrntrOilCoolOilIntkTemperature 8466;
BA_ "SPN" SG_ 2633752830 AltrntrOilCoolOilOtltTemperature 8467;
BA_ "SPN" SG_ 2633752830 AltrntrOilCoolCoolntIntkTemp 8468;
BA_ "SPN" SG_ 2633752830 AltrntrOilCoolCoolntOtltTemp 8469;
BA_ "SPN" SG_ 2633752830 EngOilCoolCoolntOtltTemperature 728;
BA_ "SPN" SG_ 2633752830 AltrntrAftrclrCoolntPmpOtltTemp 8470;
BA_ "SPN" SG_ 2633752830 AltrntrAftrclrCoolntOtltTemp 8471;
BA_ "SPN" SG_ 2633752830 AltrntrAftrclrCoolntPmpOtltPress 8472;
BA_ "SPN" SG_ 2633753086 PowerRectifierDiode9Temperature 8459;
BA_ "SPN" SG_ 2633753086 PowerRectifierDiode10Temperature 8460;
BA_ "SPN" SG_ 2633753086 PowerRectifierDiode11Temperature 8461;
BA_ "SPN" SG_ 2633753086 PowerRectifierDiode12Temperature 8462;
BA_ "SPN" SG_ 2633753342 PowerRectifierDiode1Temperature 8451;
BA_ "SPN" SG_ 2633753342 PowerRectifierDiode2Temperature 8452;
BA_ "SPN" SG_ 2633753342 PowerRectifierDiode3Temperature 8453;
BA_ "SPN" SG_ 2633753342 PowerRectifierDiode4Temperature 8454;
BA_ "SPN" SG_ 2633753342 PowerRectifierDiode5Temperature 8455;
BA_ "SPN" SG_ 2633753342 PowerRectifierDiode6Temperature 8456;
BA_ "SPN" SG_ 2633753342 PowerRectifierDiode7Temperature 8457;
BA_ "SPN" SG_ 2633753342 PowerRectifierDiode8Temperature 8458;
BA_ "SPN" SG_ 2633753598 EngineAltrntrWinding7Temperature 8443;
BA_ "SPN" SG_ 2633753598 EngineAltrntrWinding8Temperature 8444;
BA_ "SPN" SG_ 2633753598 EngineAltrntrWinding9Temperature 8445;
BA_ "SPN" SG_ 2633753598 EngAltrntrWinding10Temperature 8446;
BA_ "SPN" SG_ 2633753598 EngAltrntrWinding11Temperature 8447;
BA_ "SPN" SG_ 2633753598 EngAltrntrWinding12Temperature 8448;
BA_ "SPN" SG_ 2633753598 AltrntrAirCoolAirIntkTemperature 8449;
BA_ "SPN" SG_ 2633753598 AltrntrAirCoolAirOtltTemperature 8450;
BA_ "SPN" SG_ 2566644990 DrvrSdeFuelReceptacle1CoverStat 8415;
BA_ "SPN" SG_ 2566644990 DrvrSdeFuelReceptacle2CoverStat 8416;
BA_ "SPN" SG_ 2566644990 PassngSdeFuelReceptacle1CoverSt 8417;
BA_ "SPN" SG_ 2566644990 PassngSdeFuelReceptacle2CoverSt 8418;
BA_ "SPN" SG_ 2566644990 FrontFuelReceptacleCoverStatus 8419;
BA_ "SPN" SG_ 2566644990 FuelStorageCompartment1Temp1 8420;
BA_ "SPN" SG_ 2566644990 FuelStorageCompartment1Temp2 8421;
BA_ "SPN" SG_ 2566644990 FuelStorageCompartment2Temp1 8422;
BA_ "SPN" SG_ 2566644990 FuelStorageCompartment2Temp2 8423;
BA_ "SPN" SG_ 2566644990 FuelStorageCompartment3Temp1 8424;
BA_ "SPN" SG_ 2566644990 FuelStorageCompartment3Temp2 8425;
BA_ "SPN" SG_ 2566645246 HVESFanEnableStatus 8403;
BA_ "SPN" SG_ 2566645246 HVESFanStatusReasonCode 8404;
BA_ "SPN" SG_ 2566645246 HVESFanCommandStatus 8405;
BA_ "SPN" SG_ 2566645246 HVESFanSpeed 8406;
BA_ "SPN" SG_ 2566645246 HVESFanMediumTemperature 8407;
BA_ "SPN" SG_ 2566645246 HVESFanPower 8408;
BA_ "SPN" SG_ 2566645246 HVESFanServiceIndicator 8409;
BA_ "SPN" SG_ 2566645246 HVESFanOperatingStatus 8410;
BA_ "SPN" SG_ 2566645246 HVESFanInstance 8411;
BA_ "SPN" SG_ 2365318910 HVESFanEnableCommand 8384;
BA_ "SPN" SG_ 2365318910 HVESFanPowerHold 8385;
BA_ "SPN" SG_ 2365318910 HVESFanSpeedCommand 8386;
BA_ "SPN" SG_ 2365318910 HVESFanPercentSpeedCommand 8387;
BA_ "SPN" SG_ 2365318910 HVESFanInstance1 8388;
BA_ "SPN" SG_ 2365318910 HVESFanInstance2 8389;
BA_ "SPN" SG_ 2365318910 HVESFanInstance3 8390;
BA_ "SPN" SG_ 2365318910 HVESFanInstance4 8391;
BA_ "SPN" SG_ 2365318910 HVESFanInstance5 8392;
BA_ "SPN" SG_ 2365318910 HVESFanInstance6 8393;
BA_ "SPN" SG_ 2365318910 HVESFanInstance7 8394;
BA_ "SPN" SG_ 2365318910 HVESFanInstance8 8395;
BA_ "SPN" SG_ 2365318910 HVESFanInstance9 8396;
BA_ "SPN" SG_ 2365318910 HVESFanInstance10 8397;
BA_ "SPN" SG_ 2365318910 HVESFanInstance11 8398;
BA_ "SPN" SG_ 2365318910 HVESFanInstance12 8399;
BA_ "SPN" SG_ 2365318910 HVESFanInstance13 8400;
BA_ "SPN" SG_ 2365318910 HVESFanInstance14 8401;
BA_ "SPN" SG_ 2365318910 HVESFanInstance15 8402;
BA_ "SPN" SG_ 2633754622 Aftrtrtmnt1SCRIntkHghTempTime 8327;
BA_ "SPN" SG_ 2633754878 AftrtrtmntTotalDslExhstFluidUsed 8326;
BA_ "SPN" SG_ 2633755134 HostName 8288;
BA_ "SPN" SG_ 2633755390 DHCPStatus 8268;
BA_ "SPN" SG_ 2633755390 EthernetLinkStatus 8269;
BA_ "SPN" SG_ 2633755390 IPv4AddressOctet1 8270;
BA_ "SPN" SG_ 2633755390 IPv4AddressOctet2 8271;
BA_ "SPN" SG_ 2633755390 IPv4AddressOctet3 8272;
BA_ "SPN" SG_ 2633755390 IPv4AddressOctet4 8273;
BA_ "SPN" SG_ 2633755390 SubnetMaskOctet1 8274;
BA_ "SPN" SG_ 2633755390 SubnetMaskOctet2 8275;
BA_ "SPN" SG_ 2633755390 SubnetMaskOctet3 8276;
BA_ "SPN" SG_ 2633755390 SubnetMaskOctet4 8277;
BA_ "SPN" SG_ 2633755390 DefaultGatewayOctet1 8278;
BA_ "SPN" SG_ 2633755390 DefaultGatewayOctet2 8279;
BA_ "SPN" SG_ 2633755390 DefaultGatewayOctet3 8280;
BA_ "SPN" SG_ 2633755390 DefaultGatewayOctet4 8281;
BA_ "SPN" SG_ 2633755390 MACAddressOctet1 8282;
BA_ "SPN" SG_ 2633755390 MACAddressOctet2 8283;
BA_ "SPN" SG_ 2633755390 MACAddressOctet3 8284;
BA_ "SPN" SG_ 2633755390 MACAddressOctet4 8285;
BA_ "SPN" SG_ 2633755390 MACAddressOctet5 8286;
BA_ "SPN" SG_ 2633755390 MACAddressOctet6 8287;
BA_ "SPN" SG_ 2566646782 OilDebrisMontFerrsBins12IdNo 8167;
BA_ "SPN" SG_ 2566646782 OilDebrisMonitorFerrousBin1Count 8168;
BA_ "SPN" SG_ 2566646782 OilDebrisMonitorFerrousBin2Count 8169;
BA_ "SPN" SG_ 2566647038 OilDebrisMontFerrsBins34IdNo 8170;
BA_ "SPN" SG_ 2566647038 OilDebrisMonitorFerrousBin3Count 8171;
BA_ "SPN" SG_ 2566647038 OilDebrisMonitorFerrousBin4Count 8172;
BA_ "SPN" SG_ 2566647294 OilDebrisMontFerrsBins56IdNo 8173;
BA_ "SPN" SG_ 2566647294 OilDebrisMonitorFerrousBin5Count 8174;
BA_ "SPN" SG_ 2566647294 OilDebrisMonitorFerrousBin6Count 8175;
BA_ "SPN" SG_ 2566647550 OilDebrisMontNFerrsBins12IdNo 8176;
BA_ "SPN" SG_ 2566647550 OilDebrisMonitorNonFerrsBin1Cnt 8177;
BA_ "SPN" SG_ 2566647550 OilDebrisMonitorNonFerrsBin2Cnt 8178;
BA_ "SPN" SG_ 2566647806 OilDebrisMontNFerrsBins34IdNo 8179;
BA_ "SPN" SG_ 2566647806 OilDebrisMonitorNonFerrsBin3Cnt 8180;
BA_ "SPN" SG_ 2566647806 OilDebrisMonitorNonFerrsBin4Cnt 8181;
BA_ "SPN" SG_ 2566648062 OilDebrisMontNFerrsBins56IdNo 8182;
BA_ "SPN" SG_ 2566648062 OilDebrisMonitorNonFerrsBin5Cnt 8183;
BA_ "SPN" SG_ 2566648062 OilDebrisMonitorNonFerrsBin6Cnt 8184;
BA_ "SPN" SG_ 2566648318 OilDebrisMontStatusIdntfctionNo 8185;
BA_ "SPN" SG_ 2566648318 OilDebrisMontTotalNumberSensors 8186;
BA_ "SPN" SG_ 2566648318 OilDebrisMontEnvironmentStatus 8187;
BA_ "SPN" SG_ 2566648318 OilDebrisMontSensingElementStat 8188;
BA_ "SPN" SG_ 2566648318 OilDebrisMontSigPrcngElctrncsSt 8189;
BA_ "SPN" SG_ 2566648318 OilDebrisMontElctrncsTempStat 8190;
BA_ "SPN" SG_ 2365322238 DirectionalVehicleSpeed 8166;
BA_ "SPN" SG_ 2566649086 Aft2DslOxidtnCtlystIntkPress 8163;
BA_ "SPN" SG_ 2566649086 Aft2DslOxidtnCtlystOtltPress 8164;
BA_ "SPN" SG_ 2566649086 Aft2DOCInletToDPFOtltDeltaPress 8165;
BA_ "SPN" SG_ 2566649342 Aft1DslOxidtnCtlystIntkPress 8160;
BA_ "SPN" SG_ 2566649342 Aft1DslOxidtnCtlystOtltPress 8161;
BA_ "SPN" SG_ 2566649342 Aft1DOCInletToDPFOtltDeltaPress 8162;
BA_ "SPN" SG_ 2566649598 TotalNumberOfSatellitesInView 8128;
BA_ "SPN" SG_ 2566649598 HorizontalDilutionOfPrecision 8129;
BA_ "SPN" SG_ 2566649598 VerticalDilutionOfPrecision 8130;
BA_ "SPN" SG_ 2566649598 PositionDilutionOfPrecision 8131;
BA_ "SPN" SG_ 2566649598 TimeDilutionOfPrecision 8132;
BA_ "SPN" SG_ 2566649854 PropulsionMtrCoolntFn3EnblStatus 8067;
BA_ "SPN" SG_ 2566649854 ProplsnMtrClntFn3CtrllerStRsnCd 8068;
BA_ "SPN" SG_ 2566649854 ProplsnMtrClntFn3CtrllerCmdStat 8069;
BA_ "SPN" SG_ 2566649854 PropulsionMtrCoolntFn3MotorSpeed 8070;
BA_ "SPN" SG_ 2566649854 ProplsnMtrCoolntFn3CtrlTemp 8071;
BA_ "SPN" SG_ 2566649854 PropulsionMotorCoolantFan3Power 8072;
BA_ "SPN" SG_ 2566649854 ProplsnMtrCoolntFn3SrvcIndictr 8073;
BA_ "SPN" SG_ 2566649854 ProplsnMtrCoolntFn3OprtngStatus 8074;
BA_ "SPN" SG_ 2566650110 PropulsionMtrCoolntFn2EnblStatus 8055;
BA_ "SPN" SG_ 2566650110 ProplsnMtrClntFn2CtrllerStRsnCd 8056;
BA_ "SPN" SG_ 2566650110 ProplsnMtrClntFn2CtrllerCmdStat 8057;
BA_ "SPN" SG_ 2566650110 PropulsionMtrCoolntFn2MotorSpeed 8058;
BA_ "SPN" SG_ 2566650110 ProplsnMtrCoolntFn2CtrlTemp 8059;
BA_ "SPN" SG_ 2566650110 PropulsionMotorCoolantFan2Power 8060;
BA_ "SPN" SG_ 2566650110 ProplsnMtrCoolntFn2SrvcIndictr 8061;
BA_ "SPN" SG_ 2566650110 ProplsnMtrCoolntFn2OprtngStatus 8062;
BA_ "SPN" SG_ 2566650366 PropulsionMtrCoolntFn1EnblStatus 8043;
BA_ "SPN" SG_ 2566650366 ProplsnMtrClntFn1CtrllerStRsnCd 8044;
BA_ "SPN" SG_ 2566650366 ProplsnMtrClntFn1CtrllerCmdStat 8045;
BA_ "SPN" SG_ 2566650366 PropulsionMtrCoolntFn1MotorSpeed 8046;
BA_ "SPN" SG_ 2566650366 ProplsnMtrCoolntFn1CtrlTemp 8047;
BA_ "SPN" SG_ 2566650366 PropulsionMotorCoolantFan1Power 8048;
BA_ "SPN" SG_ 2566650366 ProplsnMtrCoolntFn1SrvcIndictr 8049;
BA_ "SPN" SG_ 2566650366 ProplsnMtrCoolntFn1OprtngStatus 8050;
BA_ "SPN" SG_ 2566650622 PowerElctrncsCoolntFn3EnblStatus 8031;
BA_ "SPN" SG_ 2566650622 PwrElctrncsClntFn3CtrllerStRsnCd 8032;
BA_ "SPN" SG_ 2566650622 PwrElctrncsClntFn3CtrllerCmdStat 8033;
BA_ "SPN" SG_ 2566650622 PowerElctrncsCoolntFn3MotorSpeed 8034;
BA_ "SPN" SG_ 2566650622 PwrElctrncsCoolntFn3CtrlTemp 8035;
BA_ "SPN" SG_ 2566650622 PowerElectronicsCoolantFan3Power 8036;
BA_ "SPN" SG_ 2566650622 PwrElctrncsCoolntFn3SrvcIndictr 8037;
BA_ "SPN" SG_ 2566650622 PwrElctrncsCoolntFn3OprtngStatus 8038;
BA_ "SPN" SG_ 2566650878 PowerElctrncsCoolntFn2EnblStatus 8019;
BA_ "SPN" SG_ 2566650878 PwrElctrncsClntFn2CtrllerStRsnCd 8020;
BA_ "SPN" SG_ 2566650878 PwrElctrncsClntFn2CtrllerCmdStat 8021;
BA_ "SPN" SG_ 2566650878 PowerElctrncsCoolntFn2MotorSpeed 8022;
BA_ "SPN" SG_ 2566650878 PwrElctrncsCoolntFn2CtrlTemp 8023;
BA_ "SPN" SG_ 2566650878 PowerElectronicsCoolantFan2Power 8024;
BA_ "SPN" SG_ 2566650878 PwrElctrncsCoolntFn2SrvcIndictr 8025;
BA_ "SPN" SG_ 2566650878 PwrElctrncsCoolntFn2OprtngStatus 8026;
BA_ "SPN" SG_ 2566651134 PowerElctrncsCoolntFn1EnblStatus 8007;
BA_ "SPN" SG_ 2566651134 PwrElctrncsClntFn1CtrllerStRsnCd 8008;
BA_ "SPN" SG_ 2566651134 PwrElctrncsClntFn1CtrllerCmdStat 8009;
BA_ "SPN" SG_ 2566651134 PowerElctrncsCoolntFn1MotorSpeed 8010;
BA_ "SPN" SG_ 2566651134 PwrElctrncsCoolntFn1CtrlTemp 8011;
BA_ "SPN" SG_ 2566651134 PowerElectronicsCoolantFan1Power 8012;
BA_ "SPN" SG_ 2566651134 PwrElctrncsCoolntFn1SrvcIndictr 8013;
BA_ "SPN" SG_ 2566651134 PwrElctrncsCoolntFn1OprtngStatus 8014;
BA_ "SPN" SG_ 2566651390 PropulsionMotorOilPumpEnblStatus 7995;
BA_ "SPN" SG_ 2566651390 ProplsnMtrOilPmpCtrllerStatRsnCd 7996;
BA_ "SPN" SG_ 2566651390 ProplsnMtrOilPmpCtrllerCmdStatus 7997;
BA_ "SPN" SG_ 2566651390 PropulsionMotorOilPumpMotorSpeed 7998;
BA_ "SPN" SG_ 2566651390 ProplsnMtrOilPumpCtrlTemperature 7999;
BA_ "SPN" SG_ 2566651390 PropulsionMotorOilPumpPower 8000;
BA_ "SPN" SG_ 2566651390 ProplsnMtrOilPumpServiceIndictr 8001;
BA_ "SPN" SG_ 2566651390 PropulsionMtrOilPumpOprtngStatus 8002;
BA_ "SPN" SG_ 2566651646 ProplsnMtrCoolntPumpEnblStatus 7983;
BA_ "SPN" SG_ 2566651646 ProplsnMtrClntPmpCtrllerStRsnCd 7984;
BA_ "SPN" SG_ 2566651646 ProplsnMtrClntPmpCtrllerCmdStat 7985;
BA_ "SPN" SG_ 2566651646 PropulsionMtrCoolntPumpMtrSpeed 7986;
BA_ "SPN" SG_ 2566651646 ProplsnMtrCoolntPmpCtrlTemp 7987;
BA_ "SPN" SG_ 2566651646 PropulsionMotorCoolantPumpPower 7988;
BA_ "SPN" SG_ 2566651646 ProplsnMtrCoolntPmpSrvcIndictr 7989;
BA_ "SPN" SG_ 2566651646 ProplsnMtrCoolntPumpOprtngStatus 7990;
BA_ "SPN" SG_ 2566651902 PwrElctrncsCoolntPumpEnblStatus 7971;
BA_ "SPN" SG_ 2566651902 PwrElctrncsClntPmpCtrllerStRsnCd 7972;
BA_ "SPN" SG_ 2566651902 PwrElctrncsClntPmpCtrllerCmdStat 7973;
BA_ "SPN" SG_ 2566651902 PowerElctrncsCoolntPumpMtrSpeed 7974;
BA_ "SPN" SG_ 2566651902 PwrElctrncsCoolntPmpCtrlTemp 7975;
BA_ "SPN" SG_ 2566651902 PowerElectronicsCoolantPumpPower 7976;
BA_ "SPN" SG_ 2566651902 PwrElctrncsCoolntPmpSrvcIndictr 7977;
BA_ "SPN" SG_ 2566651902 PwrElctrncsCoolntPmpOprtngStatus 7978;
BA_ "SPN" SG_ 2566652414 ElectrfdAccssryMotorEnableStatus 7947;
BA_ "SPN" SG_ 2566652414 ElectrfdAccssryMtrCtrllerStRsnCd 7948;
BA_ "SPN" SG_ 2566652414 ElectrfdAccssryMtrCtrllerCmdStat 7949;
BA_ "SPN" SG_ 2566652414 ElectrifiedAccessoryMotorSpeed 7950;
BA_ "SPN" SG_ 2566652414 ElectrfdAccssryMtrMediumTemp 7951;
BA_ "SPN" SG_ 2566652414 ElectrifiedAccessoryMotorPower 7952;
BA_ "SPN" SG_ 2566652414 ElectrfdAccssryMtrServiceIndictr 7953;
BA_ "SPN" SG_ 2566652414 ElectrfdAccssryMtrOprtngStatus 7954;
BA_ "SPN" SG_ 2566652414 ElectrifiedAccssryMotorInstance 8308;
BA_ "SPN" SG_ 2566652670 DieselExhaustFluidFrozenTime 7938;
BA_ "SPN" SG_ 2566652670 Aftrtrtmnt1SCRSystemHydrocarbon 7934;
BA_ "SPN" SG_ 2566652670 Aft1DslExhstFldDsngSysFrozen 6802;
BA_ "SPN" SG_ 2566652670 Aft2DslExhstFldDsngSysFrozen 6803;
BA_ "SPN" SG_ 2566652926 SLIBattryPack1Battry4StateCharge 7927;
BA_ "SPN" SG_ 2566652926 SLIBatteryPack1Battery4Capacity 7928;
BA_ "SPN" SG_ 2566652926 SLIBatteryPack1Battery4Health 7929;
BA_ "SPN" SG_ 2566652926 SLIBattPack1Batt4PrdctMnCrnkVltg 7930;
BA_ "SPN" SG_ 2566652926 SLIBattryPack1Sensor4InitStatus 7931;
BA_ "SPN" SG_ 2566653182 SLIBattryPack1Battery4NetCurrent 7924;
BA_ "SPN" SG_ 2566653182 SLIBattryPack1Battry4Temperature 7925;
BA_ "SPN" SG_ 2566653182 SLIBatteryPack1Battery4Voltage 7926;
BA_ "SPN" SG_ 2566653438 SLIBattryPack1Battry3StateCharge 7919;
BA_ "SPN" SG_ 2566653438 SLIBatteryPack1Battery3Capacity 7920;
BA_ "SPN" SG_ 2566653438 SLIBatteryPack1Battery3Health 7921;
BA_ "SPN" SG_ 2566653438 SLIBattPack1Batt3PrdctMnCrnkVltg 7922;
BA_ "SPN" SG_ 2566653438 SLIBattryPack1Sensor3InitStatus 7923;
BA_ "SPN" SG_ 2566653694 SLIBattryPack1Battery3NetCurrent 7916;
BA_ "SPN" SG_ 2566653694 SLIBattryPack1Battry3Temperature 7917;
BA_ "SPN" SG_ 2566653694 SLIBatteryPack1Battery3Voltage 7918;
BA_ "SPN" SG_ 2566653950 SLIBattryPack1Battry2StateCharge 7911;
BA_ "SPN" SG_ 2566653950 SLIBatteryPack1Battery2Capacity 7912;
BA_ "SPN" SG_ 2566653950 SLIBatteryPack1Battery2Health 7913;
BA_ "SPN" SG_ 2566653950 SLIBattPack1Batt2PrdctMnCrnkVltg 7914;
BA_ "SPN" SG_ 2566653950 SLIBattryPack1Sensor2InitStatus 7915;
BA_ "SPN" SG_ 2566654206 SLIBattryPack1Battery2NetCurrent 7908;
BA_ "SPN" SG_ 2566654206 SLIBattryPack1Battry2Temperature 7909;
BA_ "SPN" SG_ 2566654206 SLIBatteryPack1Battery2Voltage 7910;
BA_ "SPN" SG_ 2566654462 SLIBattryPack1Battry1StateCharge 7903;
BA_ "SPN" SG_ 2566654462 SLIBatteryPack1Battery1Capacity 7904;
BA_ "SPN" SG_ 2566654462 SLIBatteryPack1Battery1Health 7905;
BA_ "SPN" SG_ 2566654462 SLIBattPack1Batt1PrdctMnCrnkVltg 7906;
BA_ "SPN" SG_ 2566654462 SLIBattryPack1Sensor1InitStatus 7907;
BA_ "SPN" SG_ 2566654718 SLIBattryPack1Battery1NetCurrent 7900;
BA_ "SPN" SG_ 2566654718 SLIBattryPack1Battry1Temperature 7901;
BA_ "SPN" SG_ 2566654718 SLIBatteryPack1Battery1Voltage 7902;
BA_ "SPN" SG_ 2566654974 EstEngParasiticLossesPrcntTorque 7837;
BA_ "SPN" SG_ 2566654974 ActlMaximumAvailEngPercentFuel 8630;
BA_ "SPN" SG_ 2633764094 CanisterVentValve 7833;
BA_ "SPN" SG_ 2633764094 CanisterPurgeValveCommand 7834;
BA_ "SPN" SG_ 2633764094 GasolineFuelTankPressure 7835;
BA_ "SPN" SG_ 2633764350 FirePumpOperationTime 7825;
BA_ "SPN" SG_ 2633764350 FirePumpEngagementCycles 7826;
BA_ "SPN" SG_ 2566655742 RearHitchRollSensitivity 7812;
BA_ "SPN" SG_ 2566655742 RearHitchPitchSensitivity 7813;
BA_ "SPN" SG_ 2566655998 FrontHitchRollSensitivity 7800;
BA_ "SPN" SG_ 2566655998 FrontHitchPitchSensitivity 7801;
BA_ "SPN" SG_ 2566656254 BarometricAbsolutePressure2 7781;
BA_ "SPN" SG_ 2566656254 EngineIntake2AirTemperature 7850;
BA_ "SPN" SG_ 2566656510 EngineTotalGaseousFuelVolumeUsed 7455;
BA_ "SPN" SG_ 2566656510 EngTotalGasIdleFuelVolumeUsed 7456;
BA_ "SPN" SG_ 2499547902 CabDoorsLockActuationCommand 7727;
BA_ "SPN" SG_ 2499547902 RemoteCabDoorLockRequest 7728;
BA_ "SPN" SG_ 2499547902 LeftFrontWindowPositionCommand 7729;
BA_ "SPN" SG_ 2499547902 RightFrontWindowPositionCommand 7730;
BA_ "SPN" SG_ 2499547902 LeftRearWindowPositionCommand 7731;
BA_ "SPN" SG_ 2499547902 RightRearWindowPositionCommand 7732;
BA_ "SPN" SG_ 2499547902 MirrorLeft1HorizontalCommand 7733;
BA_ "SPN" SG_ 2499547902 MirrorLeft1VerticalCommand 7734;
BA_ "SPN" SG_ 2499547902 MirrorRight1HorizontalCommand 7735;
BA_ "SPN" SG_ 2499547902 MirrorRight1VerticalCommand 7736;
BA_ "SPN" SG_ 2499547902 MirrorLeft2HorizontalCommand 7737;
BA_ "SPN" SG_ 2499547902 MirrorLeft2VerticalCommand 7738;
BA_ "SPN" SG_ 2499547902 MirrorRight2HorizontalCommand 7739;
BA_ "SPN" SG_ 2499547902 MirrorRight2VerticalCommand 7740;
BA_ "SPN" SG_ 2499547902 MirrorLeft1HeatCommand 7741;
BA_ "SPN" SG_ 2499547902 MirrorRight1HeatCommand 7742;
BA_ "SPN" SG_ 2499547902 MirrorLeft2HeatCommand 7743;
BA_ "SPN" SG_ 2499547902 MirrorRight2HeatCommand 7744;
BA_ "SPN" SG_ 2499548158 LeftFrontCabDoorLatchPosition 7723;
BA_ "SPN" SG_ 2499548158 RightFrontCabDoorLatchPosition 7724;
BA_ "SPN" SG_ 2499548158 LeftRearCabDoorLatchPosition 7725;
BA_ "SPN" SG_ 2499548158 RightRearCabDoorLatchPosition 7726;
BA_ "SPN" SG_ 2499548670 BatteryPotentialPowerInput3 7712;
BA_ "SPN" SG_ 2499548670 BatteryPotentialPowerInput4 7713;
BA_ "SPN" SG_ 2499548670 SLIBattery3NetCurrent 7714;
BA_ "SPN" SG_ 2499548670 SLIBattery4NetCurrent 7715;
BA_ "SPN" SG_ 2499548926 PayloadTemperature5 7707;
BA_ "SPN" SG_ 2499549182 PayloadTemperature1 7703;
BA_ "SPN" SG_ 2499549182 PayloadTemperature2 7704;
BA_ "SPN" SG_ 2499549182 PayloadTemperature3 7705;
BA_ "SPN" SG_ 2499549182 PayloadTemperature4 7706;
BA_ "SPN" SG_ 2566658302 TotalPayloadTransactionCount 7701;
BA_ "SPN" SG_ 2566658558 TotalDeliveredPayloadWeight 7699;
BA_ "SPN" SG_ 2566658558 TotalHaulCycleCount 7700;
BA_ "SPN" SG_ 2633769726 TotalEngineEnergy 7608;
BA_ "SPN" SG_ 2633769726 EngineExhaustFlowRate 7852;
BA_ "SPN" SG_ 2566661118 EngineTotalDieselFuelDemand 7597;
BA_ "SPN" SG_ 2566661374 Aftrtrtmnt2DslExhstFldTnkVolume2 7531;
BA_ "SPN" SG_ 2566661374 Aftrtrtmnt2DslExhstFldTnkTemp2 7574;
BA_ "SPN" SG_ 2566661374 Aftrtrtmnt2DslExhstFldTankHtr2 7575;
BA_ "SPN" SG_ 2566661630 Aftrtrtmnt1DslExhstFldTnkVolume2 7530;
BA_ "SPN" SG_ 2566661630 Aftrtrtmnt1DslExhstFldTnkTemp2 7572;
BA_ "SPN" SG_ 2566661630 Aftrtrtmnt1DslExhstFldTankHtr2 7573;
BA_ "SPN" SG_ 2566661886 Aft2DslExhstFldCtrllerTemp 7529;
BA_ "SPN" SG_ 2566661886 Aft2DslExhstFldCtrller2Temp 7535;
BA_ "SPN" SG_ 2566662142 Aft1DslExhstFldCtrller1Temp 5480;
BA_ "SPN" SG_ 2566662142 Aft1DslExhstFldCtrller2Temp 7528;
BA_ "SPN" SG_ 2566662654 LftDistToLaneMarkFrmVhclsMiddle 7476;
BA_ "SPN" SG_ 2566662654 RghtDistToLaneMarkFrmVhclsMiddle 7477;
BA_ "SPN" SG_ 2566662654 RoadCurvatureBasedOnLaneMarks 7478;
BA_ "SPN" SG_ 2566662654 LaneDepartureAngleLeft 7479;
BA_ "SPN" SG_ 2566662654 LaneDepartureAngleRight 7480;
BA_ "SPN" SG_ 2566662654 LaneMarkQualityOnTheLeftSide 7481;
BA_ "SPN" SG_ 2566662654 LaneMarkQualityOnTheRightSide 7482;
BA_ "SPN" SG_ 2566662654 RightLaneMarkerType 8143;
BA_ "SPN" SG_ 2566662654 LeftLaneMarkerType 8144;
BA_ "SPN" SG_ 2566662910 OperatorIndcmntTorqueDerateLvl1 7425;
BA_ "SPN" SG_ 2566662910 OprtrIndcmntTmeToTrqDerateLvl1 7426;
BA_ "SPN" SG_ 2566662910 OperatorIndcmntTorqueDerateLvl2 7427;
BA_ "SPN" SG_ 2566662910 OprtrIndcmntTmeToTrqDerateLvl2 7428;
BA_ "SPN" SG_ 2566662910 OprtrIndcmntTmeToFinalIndcmntAct 7719;
BA_ "SPN" SG_ 2566663166 AppliedVehicleSpeedLimit 7420;
BA_ "SPN" SG_ 2566663166 CruiseCtrlAdjustedMaximumSpeed 7495;
BA_ "SPN" SG_ 2566663166 EngExternalIdleRequestFeedback 8441;
BA_ "SPN" SG_ 2566663422 TractorBrkCaliperLnngClrAxl1Lft 7396;
BA_ "SPN" SG_ 2566663422 TractorBrkCaliperLnngClrAxl1Rght 7397;
BA_ "SPN" SG_ 2566663422 TractorBrkCaliperLnngClrAxl2Lft 7398;
BA_ "SPN" SG_ 2566663422 TractorBrkCaliperLnngClrAxl2Rght 7399;
BA_ "SPN" SG_ 2566663422 TractorBrkCaliperLnngClrAxl3Lft 7400;
BA_ "SPN" SG_ 2566663422 TractorBrkCaliperLnngClrAxl3Rght 7401;
BA_ "SPN" SG_ 2566663422 TractorBrkCaliperLnngClrAxl4Lft 7402;
BA_ "SPN" SG_ 2566663422 TractorBrkCaliperLnngClrAxl4Rght 7403;
BA_ "SPN" SG_ 2566663422 TractorBrkCaliperLnngClrAxl5Lft 7404;
BA_ "SPN" SG_ 2566663422 TractorBrkCaliperLnngClrAxl5Rght 7405;
BA_ "SPN" SG_ 2566663422 TrlrBrkCaliperLnngClearAxl1Lft 7406;
BA_ "SPN" SG_ 2566663422 TrlrBrkCaliperLnngClearAxl1Rght 7407;
BA_ "SPN" SG_ 2566663422 TrlrBrkCaliperLnngClearAxl2Lft 7408;
BA_ "SPN" SG_ 2566663422 TrlrBrkCaliperLnngClearAxl2Rght 7409;
BA_ "SPN" SG_ 2566663422 TrlrBrkCaliperLnngClearAxl3Lft 7410;
BA_ "SPN" SG_ 2566663422 TrlrBrkCaliperLnngClearAxl3Rght 7411;
BA_ "SPN" SG_ 2566663422 TrlrBrkCaliperLnngClearAxl4Lft 7412;
BA_ "SPN" SG_ 2566663422 TrlrBrkCaliperLnngClearAxl4Rght 7413;
BA_ "SPN" SG_ 2566663422 TrlrBrkCaliperLnngClearAxl5Lft 7414;
BA_ "SPN" SG_ 2566663422 TrlrBrkCaliperLnngClearAxl5Rght 7415;
BA_ "SPN" SG_ 2566663678 LNGTank1VaporPressure 6787;
BA_ "SPN" SG_ 2566663678 LNGTank2VaporPressure 6788;
BA_ "SPN" SG_ 2566663678 EngFuel2InjectrMeterngRail1Temp2 7514;
BA_ "SPN" SG_ 2566663934 EngTurboCmprBffActr1MtrCurDisabl 7380;
BA_ "SPN" SG_ 2566663934 EngTurboWstgtActr1MtrCurrDisabl 7381;
BA_ "SPN" SG_ 2566663934 EngCylHeadBypssActr1MtrCurDisabl 7382;
BA_ "SPN" SG_ 2566663934 EngThrottleValve1MotorCurrDisabl 7383;
BA_ "SPN" SG_ 2566663934 EngTurboCmprBypssActr1MtrCurDsbl 7708;
BA_ "SPN" SG_ 2566663934 EngTurboCmprBypssActr2MtrCurDsbl 7709;
BA_ "SPN" SG_ 2566663934 EngTurboWstgtActr2MtrCurrDisabl 7710;
BA_ "SPN" SG_ 2633773054 FireSuppressionWaterTankLevel 7347;
BA_ "SPN" SG_ 2633773054 FireSuppressionClassAFoamTankLvl 7348;
BA_ "SPN" SG_ 2633773054 FireSuppressionClassBFoamTankLvl 7349;
BA_ "SPN" SG_ 2633773054 FireSupprssnCmpdAirFoamSysAirPrs 7350;
BA_ "SPN" SG_ 2633773310 SCROprtrIndcEmrgOvrrdTtlRstOccur 7341;
BA_ "SPN" SG_ 2633773310 SCROperatorIndcmntOverrideMode 7342;
BA_ "SPN" SG_ 2633773310 SCROprtrIndcOvrrdRenewalRequired 7343;
BA_ "SPN" SG_ 2633773310 SCROprtrIndcmntOverrdTimeRemain 7344;
BA_ "SPN" SG_ 2566664702 AftrtrtmntThermalMangmntStatus 7332;
BA_ "SPN" SG_ 2566664702 AftActRegenInhbtdDTLowExhstPress 7440;
BA_ "SPN" SG_ 2566664702 AftrtrtmntEngSpeedIncreaseRq 7502;
BA_ "SPN" SG_ 2566664702 AftertreatmentEngineLoadRequest 7503;
BA_ "SPN" SG_ 2566664702 AftrtrtmntAmbientAirTemperature 7441;
BA_ "SPN" SG_ 2566664702 AftrtrtmntDslExhstFldHtrCircBrkr 7588;
BA_ "SPN" SG_ 2566664702 DslExhstFldQltyMalfctEvPeriodAct 7899;
BA_ "SPN" SG_ 2566664702 AftrtrtmntDslExhstFldTankVolume 7606;
BA_ "SPN" SG_ 2566664702 AftrtrtmntDslExhstFldTnkTemp 7607;
BA_ "SPN" SG_ 2499556094 Aft1PrtcltSnsrHtrHiSdeDrvPrlmFMI 7321;
BA_ "SPN" SG_ 2499556094 Aft1PrtcltSnsrHtrHiSdeDrvDiagSt 7322;
BA_ "SPN" SG_ 2499556094 Aft1PrtcltSnsrHtrLoSdeDrvPrlmFMI 7323;
BA_ "SPN" SG_ 2499556094 Aft1PrtcltSnsrHtrLoSdeDrvDiagSt 7324;
BA_ "SPN" SG_ 2499556094 Aft1PrtcltSnsrInptPrelimFMI 7325;
BA_ "SPN" SG_ 2499556094 Aft1PrtcltSnsrInptDiagStat 7326;
BA_ "SPN" SG_ 2499556094 Aft1PrtcltSnsrPwrSuppPrelimFMI 7327;
BA_ "SPN" SG_ 2499556094 Aft1PrtcltSnsrPwrSuppDiagStat 7328;
BA_ "SPN" SG_ 2499556094 Aft1PrtcltSnsrHtrPwrSuppPrlmFMI 7329;
BA_ "SPN" SG_ 2499556094 Aft1PrtcltSnsrHtrPwrSuppDiagStat 7330;
BA_ "SPN" SG_ 2499556350 EngFuel1InjectrMtrngRail1DsrdPrs 7100;
BA_ "SPN" SG_ 2499556350 EngFuel1InjectrMtrngRail2DsrdPrs 7101;
BA_ "SPN" SG_ 2499556606 EngFuel1InjectrMtrngRail1Press1 7096;
BA_ "SPN" SG_ 2499556606 EngFuel1InjectrMtrngRail1Press2 7097;
BA_ "SPN" SG_ 2499556606 EngFuel1InjectrMtrngRail2Press1 7098;
BA_ "SPN" SG_ 2499556606 EngFuel1InjectrMtrngRail2Press2 7099;
BA_ "SPN" SG_ 2566665726 Aftrtrtmnt2DslExhstFldPumpHeater 7086;
BA_ "SPN" SG_ 2566665726 Aftrtrtmnt2DslExhstFldPmp2MtrSpd 7466;
BA_ "SPN" SG_ 2499557118 EngGsFuelSupplyShutoffValve1Pos 7081;
BA_ "SPN" SG_ 2499557118 EngGsFuelSupplyShutoffValve2Pos 7082;
BA_ "SPN" SG_ 2499557118 EngGsFuelSupplyBleedValve1Pos 7083;
BA_ "SPN" SG_ 2499557118 EngGsFuelSupplyBleedValve2Pos 7084;
BA_ "SPN" SG_ 2499557118 EngGsFuelSupplyBleedValve3Pos 7085;
BA_ "SPN" SG_ 2499557118 InertGasSupplyValvePosition 7442;
BA_ "SPN" SG_ 2499557374 EngineOilMist9Concentration 7079;
BA_ "SPN" SG_ 2499557374 EngineOilMist10Concentration 7080;
BA_ "SPN" SG_ 2499557630 EngineOilMist1Concentration 7071;
BA_ "SPN" SG_ 2499557630 EngineOilMist2Concentration 7072;
BA_ "SPN" SG_ 2499557630 EngineOilMist3Concentration 7073;
BA_ "SPN" SG_ 2499557630 EngineOilMist4Concentration 7074;
BA_ "SPN" SG_ 2499557630 EngineOilMist5Concentration 7075;
BA_ "SPN" SG_ 2499557630 EngineOilMist6Concentration 7076;
BA_ "SPN" SG_ 2499557630 EngineOilMist7Concentration 7077;
BA_ "SPN" SG_ 2499557630 EngineOilMist8Concentration 7078;
BA_ "SPN" SG_ 2499557886 PlantGasFuelSupplyOutletPressure 7067;
BA_ "SPN" SG_ 2499557886 PlantInertGsSupplyOutletPressure 7068;
BA_ "SPN" SG_ 2499558142 EngineGaseousFuelSupplyPressure2 7063;
BA_ "SPN" SG_ 2499558142 EngGsFuelSupplyUnitIntkPressure 7064;
BA_ "SPN" SG_ 2499558142 EngGsFuelSuppShtoffVlv1IntkPress 7065;
BA_ "SPN" SG_ 2499558142 EngGsFuelSuppShtoffVlv2IntkPress 7066;
BA_ "SPN" SG_ 2566667262 EngineEndBearing17Temperature 7059;
BA_ "SPN" SG_ 2566667262 EngineEndBearing18Temperature 7060;
BA_ "SPN" SG_ 2566667262 EngineEndBearing19Temperature 7061;
BA_ "SPN" SG_ 2566667262 EngineEndBearing20Temperature 7062;
BA_ "SPN" SG_ 2566667518 EngineEndBearing9Temperature 7051;
BA_ "SPN" SG_ 2566667518 EngineEndBearing10Temperature 7052;
BA_ "SPN" SG_ 2566667518 EngineEndBearing11Temperature 7053;
BA_ "SPN" SG_ 2566667518 EngineEndBearing12Temperature 7054;
BA_ "SPN" SG_ 2566667518 EngineEndBearing13Temperature 7055;
BA_ "SPN" SG_ 2566667518 EngineEndBearing14Temperature 7056;
BA_ "SPN" SG_ 2566667518 EngineEndBearing15Temperature 7057;
BA_ "SPN" SG_ 2566667518 EngineEndBearing16Temperature 7058;
BA_ "SPN" SG_ 2566667774 EngineEndBearing1Temperature 7043;
BA_ "SPN" SG_ 2566667774 EngineEndBearing2Temperature 7044;
BA_ "SPN" SG_ 2566667774 EngineEndBearing3Temperature 7045;
BA_ "SPN" SG_ 2566667774 EngineEndBearing4Temperature 7046;
BA_ "SPN" SG_ 2566667774 EngineEndBearing5Temperature 7047;
BA_ "SPN" SG_ 2566667774 EngineEndBearing6Temperature 7048;
BA_ "SPN" SG_ 2566667774 EngineEndBearing7Temperature 7049;
BA_ "SPN" SG_ 2566667774 EngineEndBearing8Temperature 7050;
BA_ "SPN" SG_ 2566668030 HeatExchangerDebrisPurgeStatus 7035;
BA_ "SPN" SG_ 2566668030 HeatExchangerDebrisPurgeApprchng 7036;
BA_ "SPN" SG_ 2566668286 EngStagedTurboSolenoidStat 7025;
BA_ "SPN" SG_ 2566668542 EngFuel2PumpHydrFlwCtrlValve 7016;
BA_ "SPN" SG_ 2566668542 EngFuel2PumpHydrSwashPlateAgl 7017;
BA_ "SPN" SG_ 2566668542 EngFuel2PumpHydrDirectionalValve 7018;
BA_ "SPN" SG_ 2566668542 EngineFuel2PumpHydraulicPressure 7019;
BA_ "SPN" SG_ 2566668798 EngFuel2InjectrMeterngRail1Press 7021;
BA_ "SPN" SG_ 2566668798 EngFuel2InjectrMeterngRail2Press 7022;
BA_ "SPN" SG_ 2566668798 EngFuel2InjectrMeterngRail1Temp 7023;
BA_ "SPN" SG_ 2566668798 EngFuel2InjectrMeterngRail2Temp 7024;
BA_ "SPN" SG_ 2566668798 EngFuel2InjectrMtrngRail1Press2 7513;
BA_ "SPN" SG_ 2566669054 TireLocation 6987;
BA_ "SPN" SG_ 2566669054 TirePressure 6988;
BA_ "SPN" SG_ 2566669054 RequiredTirePressure 6989;
BA_ "SPN" SG_ 2566669310 TireLocation 6979;
BA_ "SPN" SG_ 2566669310 ColdInflationPressure 6980;
BA_ "SPN" SG_ 2566669310 UnderPressurePercentageThreshold 6981;
BA_ "SPN" SG_ 2566669310 ExtrmUnderPressPrcntageThreshold 6982;
BA_ "SPN" SG_ 2566669310 OverPressurePercentageThreshold 6983;
BA_ "SPN" SG_ 2566669310 OverTemperature 6984;
BA_ "SPN" SG_ 2566669822 TotalNumberOfAntennasUsed 6967;
BA_ "SPN" SG_ 2566669822 AntennaNumber 6968;
BA_ "SPN" SG_ 2566669822 TotalNumberTireSensorsMonitored 6969;
BA_ "SPN" SG_ 2566669822 TireSensorNumber 6970;
BA_ "SPN" SG_ 2566669822 TireLocation 6971;
BA_ "SPN" SG_ 2566669822 TireWirelessSigStrengthIndictr 6972;
BA_ "SPN" SG_ 2566670078 NumberOfTireSensors 6963;
BA_ "SPN" SG_ 2566670078 TireNumber 6964;
BA_ "SPN" SG_ 2566670078 TireLocation 6965;
BA_ "SPN" SG_ 2566670078 TireSensorIdentificationNumber 6966;
BA_ "SPN" SG_ 2566670334 NumberOfAxlesOnTheVehicle 6949;
BA_ "SPN" SG_ 2566670334 NumberOfTiresOnTheVehicle 6950;
BA_ "SPN" SG_ 2566670334 Axle1MonitoredTireCount 6951;
BA_ "SPN" SG_ 2566670334 Axle2MonitoredTireCount 6952;
BA_ "SPN" SG_ 2566670334 Axle3MonitoredTireCount 6953;
BA_ "SPN" SG_ 2566670334 Axle4MonitoredTireCount 6954;
BA_ "SPN" SG_ 2566670334 Axle5MonitoredTireCount 6955;
BA_ "SPN" SG_ 2566670334 Axle6MonitoredTireCount 6956;
BA_ "SPN" SG_ 2566670334 Axle7MonitoredTireCount 6957;
BA_ "SPN" SG_ 2566670334 Axle8MonitoredTireCount 6958;
BA_ "SPN" SG_ 2566670334 Axle9MonitoredTireCount 6959;
BA_ "SPN" SG_ 2566670334 Axle10MonitoredTireCount 6960;
BA_ "SPN" SG_ 2566670334 Axle11MonitoredTireCount 6961;
BA_ "SPN" SG_ 2566670334 Axle12MonitoredTireCount 6962;
BA_ "SPN" SG_ 2566670590 Aft2SCRSysTotalSysCleaningTme 6942;
BA_ "SPN" SG_ 2566670590 Aft2SCRSysTotalNoSysCleaningEvts 6943;
BA_ "SPN" SG_ 2566670590 Aft2SCRSysTotalNoSysCleangInhRqs 6944;
BA_ "SPN" SG_ 2566670590 Aft2SCRSysTotalNoSysCleangManRqs 6945;
BA_ "SPN" SG_ 2566670590 Aft2SCRSysAvrgTmeBtwnSysClngEvts 6946;
BA_ "SPN" SG_ 2566670590 Aft2SCRSysAvDistBtwnSysClengEvts 6947;
BA_ "SPN" SG_ 2566670846 Aft1SCRSysTotalCleaningTme 6935;
BA_ "SPN" SG_ 2566670846 Aft1SCRSysTotalNoOfSysCleangEvts 6936;
BA_ "SPN" SG_ 2566670846 Aft1SCRSysTotalNoSysCleangInhRqs 6937;
BA_ "SPN" SG_ 2566670846 Aft1SCRSysTotalNoSysCleangManRqs 6938;
BA_ "SPN" SG_ 2566670846 Aft1SCRSysAvrTmeBtwnSysCleanEvts 6939;
BA_ "SPN" SG_ 2566670846 Aft1SCRSysAvDistBtwnSysCleanEvts 6940;
BA_ "SPN" SG_ 2566670846 TotalAftrtrtmntOperatingHours 8629;
BA_ "SPN" SG_ 2566671102 SCRSystemCleaningLampCommand 6915;
BA_ "SPN" SG_ 2566671102 SCRSystemCleaningStatus 6916;
BA_ "SPN" SG_ 2566671102 SCRSystemCleaningInhibitedStatus 6917;
BA_ "SPN" SG_ 2566671102 SCRSystemCleaningInhbtdDTInhbtSw 6918;
BA_ "SPN" SG_ 2566671102 SCRSysCleaningInhDTCltchDiseng 6919;
BA_ "SPN" SG_ 2566671102 SCRSysCleaningInhbtdDTSrvcBrkAct 6920;
BA_ "SPN" SG_ 2566671102 SCRSystemCleaningInhbtdDTPTOActv 6921;
BA_ "SPN" SG_ 2566671102 SCRSysCleaningInhDTAcclPdlOffIdl 6922;
BA_ "SPN" SG_ 2566671102 SCRSysCleaningInhbtdDTOutOfNtrl 6923;
BA_ "SPN" SG_ 2566671102 SCRSysClnInhDTVhclSpdAbvAllwdSpd 6924;
BA_ "SPN" SG_ 2566671102 SCRSysCleaningInhDTPrkBrkNotSet 6925;
BA_ "SPN" SG_ 2566671102 SCRSysCleaningInhDTLowExhstTemp 6926;
BA_ "SPN" SG_ 2566671102 SCRSysCleaningInhDTSysFaultAct 6927;
BA_ "SPN" SG_ 2566671102 SCRSysCleaningInhbtdDTSysTimeout 6928;
BA_ "SPN" SG_ 2566671102 SCRSysCleaningInhDTTmprySysLckt 6929;
BA_ "SPN" SG_ 2566671102 SCRSysCleaningInhDTPrmntSysLckt 6930;
BA_ "SPN" SG_ 2566671102 SCRSysCleangInhDTEngNotWarmedUp 6931;
BA_ "SPN" SG_ 2566671102 SCRSysCleangInhDTVehicleSpeed 6932;
BA_ "SPN" SG_ 2566671102 SCRSystemCleaningAutoInitConf 6933;
BA_ "SPN" SG_ 2566671102 SCRSystemCleaningForcedStatus 6934;
BA_ "SPN" SG_ 2566671102 Aft1SCRSysCondtnsNotMetActCleang 7848;
BA_ "SPN" SG_ 2566671358 PEMSEngineFuelMassFlowRate 6893;
BA_ "SPN" SG_ 2566671358 VehicleFuelRate 6894;
BA_ "SPN" SG_ 2566671358 EngineExhaustFlowRate 6895;
BA_ "SPN" SG_ 2566671358 CylinderFuelRate 7333;
BA_ "SPN" SG_ 2566671614 SCROperatorIndcmntOverrideEnbl 6877;
BA_ "SPN" SG_ 2566671614 SCROprtrIndcmntOvrrdTimeRemain 6878;
BA_ "SPN" SG_ 2566671614 NoSCROprtrIndcmntOvrrdEvtsRemain 6879;
BA_ "SPN" SG_ 2566671614 TotalNoSCROprtrIndcmntOvrrdEvts 6880;
BA_ "SPN" SG_ 2566671870 Aftrtrtmnt2DslExhstFldDsngPress 6876;
BA_ "SPN" SG_ 2566671870 Aft2DslExhstFldDoser2AbsPress 7464;
BA_ "SPN" SG_ 2566671870 Aftrtrtmnt2DslExhstFldDoser2Temp 7465;
BA_ "SPN" SG_ 2566671870 Aft2DslExhstFldDoser2Press 8153;
BA_ "SPN" SG_ 2566672126 Aftrtrtmnt1DslExhstFldDsngPress 6875;
BA_ "SPN" SG_ 2566672126 Aft1DslExhstFldDoser2AbsPress 7459;
BA_ "SPN" SG_ 2566672126 Aftrtrtmnt1DslExhstFldDoser2Temp 7460;
BA_ "SPN" SG_ 2566672126 Aft1DslExhstFldDoser2Press 8152;
BA_ "SPN" SG_ 2566672382 PayloadWeightSensor1Status 6855;
BA_ "SPN" SG_ 2566672382 PayloadWeightSensor2Status 6856;
BA_ "SPN" SG_ 2566672382 PayloadWeightSensor3Status 6857;
BA_ "SPN" SG_ 2566672382 PayloadWeightSensor4Status 6858;
BA_ "SPN" SG_ 2566672382 PayloadWeightSensor5Status 6859;
BA_ "SPN" SG_ 2566672382 PayloadWeightSensor6Status 6860;
BA_ "SPN" SG_ 2566672382 PayloadWeightSensor7Status 6861;
BA_ "SPN" SG_ 2566672382 PayloadWeightSensor8Status 6862;
BA_ "SPN" SG_ 2566672638 HaulCycleCount 6847;
BA_ "SPN" SG_ 2566672638 HaulModeStatus 6848;
BA_ "SPN" SG_ 2566672638 PayloadDeliveryTransactionStatus 7702;
BA_ "SPN" SG_ 2566672638 DeliveredPayloadWeight 6849;
BA_ "SPN" SG_ 2566672638 DeliveredPayloadConfidence 6850;
BA_ "SPN" SG_ 2365346302 LiftAxle1Status 6843;
BA_ "SPN" SG_ 2365346302 LiftAxle2Status 6844;
BA_ "SPN" SG_ 2633782014 BinInstance 6845;
BA_ "SPN" SG_ 2633782014 BinWeighingErrorStatus 6842;
BA_ "SPN" SG_ 2633782014 BinLiftCount 6840;
BA_ "SPN" SG_ 2633782014 NetBinWeight 6841;
BA_ "SPN" SG_ 2566673406 GaseousFuelLeakage1Concentration 6834;
BA_ "SPN" SG_ 2566673406 GaseousFuelLeakage2Concentration 6835;
BA_ "SPN" SG_ 2566673406 GaseousFuelLeakage3Concentration 6836;
BA_ "SPN" SG_ 2566673406 GasLeakageDetection1Pressure 6837;
BA_ "SPN" SG_ 2566673406 GasLeakageDetection2Pressure 6838;
BA_ "SPN" SG_ 2566673406 GasLeakageDetection3Pressure 6839;
BA_ "SPN" SG_ 2566674174 AftertreatmentSCRMalfunctionTime 6819;
BA_ "SPN" SG_ 2566674174 SCROperatorInducementTotalTime 7095;
BA_ "SPN" SG_ 2566674430 DieselExhaustFluidTank1EmptyTime 6817;
BA_ "SPN" SG_ 2566674430 DslExhstFldQualityMalfunctionTme 6818;
BA_ "SPN" SG_ 2566674686 EngTurbocharger2LubeOilPressure 6811;
BA_ "SPN" SG_ 2566674686 EngTurbocharger3LubeOilPressure 6812;
BA_ "SPN" SG_ 2566674686 EngTurbocharger4LubeOilPressure 6813;
BA_ "SPN" SG_ 2566674686 EngTurbocharger2OilTemperature 8850;
BA_ "SPN" SG_ 2365348350 EngineUnloadStatus 6793;
BA_ "SPN" SG_ 2365348350 EngineLoadShareStatus 6794;
BA_ "SPN" SG_ 2566675966 HVES1NominalVoltage 8115;
BA_ "SPN" SG_ 2566675966 HVES1RecommendedMinOprtngVoltage 8116;
BA_ "SPN" SG_ 2566675966 HVES1RecommendedMaxOprtngVoltage 8117;
BA_ "SPN" SG_ 2566675966 HVES1RecommendedMinimumStateChrg 8118;
BA_ "SPN" SG_ 2566675966 HVES1RecommendedMaximumStateChrg 8119;
BA_ "SPN" SG_ 2566675966 HVES1RecommendedMaxOprtngTemp 8120;
BA_ "SPN" SG_ 2566675966 HVES1RecommendedMinOprtngTemp 8208;
BA_ "SPN" SG_ 2566675966 HVES1CellMaximumVoltageLimit 8209;
BA_ "SPN" SG_ 2566675966 HVES1CellMinimumVoltageLimit 8210;
BA_ "SPN" SG_ 2633785086 HVES1StateOfHealth 8121;
BA_ "SPN" SG_ 2633785086 HVES1ContactorOpenUnderLoadCount 8122;
BA_ "SPN" SG_ 2633785086 HVES1TotalEnergyThroughput 8211;
BA_ "SPN" SG_ 2633785086 HVES1TotalAccumulatedCharge 8212;
BA_ "SPN" SG_ 2566687742 Aft1PrticulateSnsrDetctnStat 6777;
BA_ "SPN" SG_ 2566687742 Aft1PrticulateSnsrPwrSupply 6778;
BA_ "SPN" SG_ 2566687742 Aft1PrticulateSnsrRegenFailedCnt 6779;
BA_ "SPN" SG_ 2566687742 Aftrtrtmnt1PrticulateSnsrTemp 6780;
BA_ "SPN" SG_ 2566687742 Aft1PrticulateSnsrMaxResist 6781;
BA_ "SPN" SG_ 2566687742 Aftrtrtmnt1PrtcltSensorHtrResist 7070;
BA_ "SPN" SG_ 2566687998 Aftrtrtmnt1PrticulateSnsrResist 6771;
BA_ "SPN" SG_ 2566687998 Aftrtrtmnt1PrticulateSnsrHtrStat 6772;
BA_ "SPN" SG_ 2566687998 Aft1PrticulateSnsrRegenStatus 6773;
BA_ "SPN" SG_ 2566687998 Aft1PrticulateSnsrRegenState 6774;
BA_ "SPN" SG_ 2566687998 Aft1PrticulateSnsrActAccmltTme 6775;
BA_ "SPN" SG_ 2566687998 Aft1PrticulateSnsrTmeBetweenRegs 6776;
BA_ "SPN" SG_ 2432471038 EngineGasSupplyPressure 6646;
BA_ "SPN" SG_ 2432471038 EngFuelVaporizer1DischargeTemp 6610;
BA_ "SPN" SG_ 2432471038 EngGaseousFuelFilterOtltTemp 6815;
BA_ "SPN" SG_ 2499580158 EngInjectorMeteringRail1Press1 6589;
BA_ "SPN" SG_ 2499580158 EngInjectorMeteringRail1Press2 6590;
BA_ "SPN" SG_ 2499580158 EngInjectorMeteringRail2Press1 6591;
BA_ "SPN" SG_ 2499580158 EngInjectorMeteringRail2Press2 6592;
BA_ "SPN" SG_ 2566689278 EngineExhaustNOx 6579;
BA_ "SPN" SG_ 2566689278 EngineExhaustDesiredNOx 6580;
BA_ "SPN" SG_ 2566689534 EngineMainChamberAirFuelRatio 6575;
BA_ "SPN" SG_ 2566689534 EngMainChamberDsrdAirFuelRatio 6576;
BA_ "SPN" SG_ 2566689534 EnginePrechamberAirFuelRatio 6577;
BA_ "SPN" SG_ 2566689534 EnginePrechamberDsrdAirFuelRatio 6578;
BA_ "SPN" SG_ 2566689790 EngineMainChamberFuelAbsPressure 6571;
BA_ "SPN" SG_ 2566689790 EngMainChamberFuelDsrdAbsPress 6572;
BA_ "SPN" SG_ 2566689790 EnginePrechamberFuelAbsPressure 6573;
BA_ "SPN" SG_ 2566689790 EngPrechamberFuelDsrdAbsPressure 6574;
BA_ "SPN" SG_ 2566690046 AftDslExhstFldDosCldownIntrptCnt 6476;
BA_ "SPN" SG_ 2566690046 AftDslExhstFldDosePurgeIntrptCnt 6477;
BA_ "SPN" SG_ 2566690046 AftDslExhstFldDosCldownCoThsCycl 6478;
BA_ "SPN" SG_ 2566690046 AftDslExhstFldDosCldownCoLstCycl 6479;
BA_ "SPN" SG_ 2566690046 AftDslExhstFldDosPrgeCompThsCycl 6480;
BA_ "SPN" SG_ 2566690046 AftDslExhstFldDosPrgeCompLstCycl 6481;
BA_ "SPN" SG_ 2566690046 AfterRunCompleteThisCycle 6482;
BA_ "SPN" SG_ 2365363710 EngCylPressureMonitor1PrelimFMI 6390;
BA_ "SPN" SG_ 2365363710 EngCylPressureMonitor2PrelimFMI 6391;
BA_ "SPN" SG_ 2566690558 EngineExhaustPressure1 6384;
BA_ "SPN" SG_ 2566690558 EngineOilFilterIntakePressure 7470;
BA_ "SPN" SG_ 2566690558 EngineCommonRailOilPressure 7720;
BA_ "SPN" SG_ 2566690558 EngineCommonRailOilAbsPressure 7721;
BA_ "SPN" SG_ 2566690558 EngineExhaustPressure2 5749;
BA_ "SPN" SG_ 2566690814 SteeringModeSwitch 6375;
BA_ "SPN" SG_ 2566690814 FrontSteeringAxleCenteredStatus 6376;
BA_ "SPN" SG_ 2566690814 RearSteeringAxleCenteredStatus 6377;
BA_ "SPN" SG_ 2566690814 WheelSteerActuatorState 6378;
BA_ "SPN" SG_ 2566690814 WheelSteerActuatorState 6379;
BA_ "SPN" SG_ 2566690814 CircleSteerModeActuatorState 6380;
BA_ "SPN" SG_ 2566690814 CrabSteerModeActuatorState 6381;
BA_ "SPN" SG_ 2566690814 SteeringControllerECUTemperature 6374;
BA_ "SPN" SG_ 2499582206 SoftTopSpeedLimitActive 6370;
BA_ "SPN" SG_ 2499582206 SoftTopRatioLimitExceeded 6371;
BA_ "SPN" SG_ 2499582206 SoftTopSpeedLimitRemainingDist 6372;
BA_ "SPN" SG_ 2499582206 SoftTopSpeedLimitResetDistance 6373;
BA_ "SPN" SG_ 2499582206 StTopSpdLmtRemainCntnsIntrvlDist 6914;
BA_ "SPN" SG_ 2566691326 NoAssemblyUnitIdentifyFields 6368;
BA_ "SPN" SG_ 2566691326 AssemblyUnitIdentification 6369;
BA_ "SPN" SG_ 2566691582 Joystick3Lamp1Status 6358;
BA_ "SPN" SG_ 2566691582 Joystick3Lamp2Status 6359;
BA_ "SPN" SG_ 2566691582 Joystick3Lamp3Status 6360;
BA_ "SPN" SG_ 2566691582 Joystick3Lamp4Status 6361;
BA_ "SPN" SG_ 2566691582 Joystick3Lamp5Status 6362;
BA_ "SPN" SG_ 2566691582 Joystick3Lamp6Status 6363;
BA_ "SPN" SG_ 2566691582 Joystick3Lamp7Status 6364;
BA_ "SPN" SG_ 2566691582 Joystick3Lamp8Status 6365;
BA_ "SPN" SG_ 2566691582 Joystick3Lamp9Status 6366;
BA_ "SPN" SG_ 2566691582 Joystick3Lamp10Status 6367;
BA_ "SPN" SG_ 2566691838 Joystick2Lamp1Status 6348;
BA_ "SPN" SG_ 2566691838 Joystick2Lamp2Status 6349;
BA_ "SPN" SG_ 2566691838 Joystick2Lamp3Status 6350;
BA_ "SPN" SG_ 2566691838 Joystick2Lamp4Status 6351;
BA_ "SPN" SG_ 2566691838 Joystick2Lamp5Status 6352;
BA_ "SPN" SG_ 2566691838 Joystick2Lamp6Status 6353;
BA_ "SPN" SG_ 2566691838 Joystick2Lamp7Status 6354;
BA_ "SPN" SG_ 2566691838 Joystick2Lamp8Status 6355;
BA_ "SPN" SG_ 2566691838 Joystick2Lamp9Status 6356;
BA_ "SPN" SG_ 2566691838 Joystick2Lamp10Status 6357;
BA_ "SPN" SG_ 2566692094 Joystick1Lamp1Status 6338;
BA_ "SPN" SG_ 2566692094 Joystick1Lamp2Status 6339;
BA_ "SPN" SG_ 2566692094 Joystick1Lamp3Status 6340;
BA_ "SPN" SG_ 2566692094 Joystick1Lamp4Status 6341;
BA_ "SPN" SG_ 2566692094 Joystick1Lamp5Status 6342;
BA_ "SPN" SG_ 2566692094 Joystick1Lamp6Status 6343;
BA_ "SPN" SG_ 2566692094 Joystick1Lamp7Status 6344;
BA_ "SPN" SG_ 2566692094 Joystick1Lamp8Status 6345;
BA_ "SPN" SG_ 2566692094 Joystick1Lamp9Status 6346;
BA_ "SPN" SG_ 2566692094 Joystick1Lamp10Status 6347;
BA_ "SPN" SG_ 2499583486 EngineTimingActr1PositionCommand 6336;
BA_ "SPN" SG_ 2499583486 EngineTimingActr2PositionCommand 6337;
BA_ "SPN" SG_ 2499583742 EngineTimingActuator1 635;
BA_ "SPN" SG_ 2499583742 EngineTimingActuator2 1245;
BA_ "SPN" SG_ 2499583742 EngTimingActr1RequestedPosition 6334;
BA_ "SPN" SG_ 2499583742 EngTimingActr2RequestedPosition 6335;
BA_ "SPN" SG_ 2566692862 EngineOilFilterDiffPressure 6321;
BA_ "SPN" SG_ 2566692862 EngineFuel2Tank1Level 6642;
BA_ "SPN" SG_ 2566692862 EngineFuel2Tank2Level 6643;
BA_ "SPN" SG_ 2566692862 EngineFuel2Tank3Level 6644;
BA_ "SPN" SG_ 2566692862 EngineFuel2Tank4Level 6645;
BA_ "SPN" SG_ 2566692862 DisplayRemainPowered 6846;
BA_ "SPN" SG_ 2566692862 EngineOilLevelHighLow 8856;
BA_ "SPN" SG_ 2633801982 EngTotalHoursOfGaseousFuelOp 6319;
BA_ "SPN" SG_ 2633801982 EngTotalHoursOfDslFuelOperation 6320;
BA_ "SPN" SG_ 2633802238 EngineSparkPlug17MisfireRate 6286;
BA_ "SPN" SG_ 2633802238 EngineSparkPlug18MisfireRate 6287;
BA_ "SPN" SG_ 2633802238 EngineSparkPlug19MisfireRate 6288;
BA_ "SPN" SG_ 2633802238 EngineSparkPlug20MisfireRate 6289;
BA_ "SPN" SG_ 2633802238 EngineSparkPlug21MisfireRate 6290;
BA_ "SPN" SG_ 2633802238 EngineSparkPlug22MisfireRate 6291;
BA_ "SPN" SG_ 2633802238 EngineSparkPlug23MisfireRate 6292;
BA_ "SPN" SG_ 2633802238 EngineSparkPlug24MisfireRate 6293;
BA_ "SPN" SG_ 2633802494 EngineSparkPlug9MisfireRate 6278;
BA_ "SPN" SG_ 2633802494 EngineSparkPlug10MisfireRate 6279;
BA_ "SPN" SG_ 2633802494 EngineSparkPlug11MisfireRate 6280;
BA_ "SPN" SG_ 2633802494 EngineSparkPlug12MisfireRate 6281;
BA_ "SPN" SG_ 2633802494 EngineSparkPlug13MisfireRate 6282;
BA_ "SPN" SG_ 2633802494 EngineSparkPlug14MisfireRate 6283;
BA_ "SPN" SG_ 2633802494 EngineSparkPlug15MisfireRate 6284;
BA_ "SPN" SG_ 2633802494 EngineSparkPlug16MisfireRate 6285;
BA_ "SPN" SG_ 2633802750 EngineSparkPlug1MisfireRate 6270;
BA_ "SPN" SG_ 2633802750 EngineSparkPlug2MisfireRate 6271;
BA_ "SPN" SG_ 2633802750 EngineSparkPlug3MisfireRate 6272;
BA_ "SPN" SG_ 2633802750 EngineSparkPlug4MisfireRate 6273;
BA_ "SPN" SG_ 2633802750 EngineSparkPlug5MisfireRate 6274;
BA_ "SPN" SG_ 2633802750 EngineSparkPlug6MisfireRate 6275;
BA_ "SPN" SG_ 2633802750 EngineSparkPlug7MisfireRate 6276;
BA_ "SPN" SG_ 2633802750 EngineSparkPlug8MisfireRate 6277;
BA_ "SPN" SG_ 2633803006 EngineSparkPlug21MaximumVoltage 6266;
BA_ "SPN" SG_ 2633803006 EngineSparkPlug22MaximumVoltage 6267;
BA_ "SPN" SG_ 2633803006 EngineSparkPlug23MaximumVoltage 6268;
BA_ "SPN" SG_ 2633803006 EngineSparkPlug24MaximumVoltage 6269;
BA_ "SPN" SG_ 2633803262 EngineSparkPlug17MaximumVoltage 6262;
BA_ "SPN" SG_ 2633803262 EngineSparkPlug18MaximumVoltage 6263;
BA_ "SPN" SG_ 2633803262 EngineSparkPlug19MaximumVoltage 6264;
BA_ "SPN" SG_ 2633803262 EngineSparkPlug20MaximumVoltage 6265;
BA_ "SPN" SG_ 2633803518 EngineSparkPlug13MaximumVoltage 6258;
BA_ "SPN" SG_ 2633803518 EngineSparkPlug14MaximumVoltage 6259;
BA_ "SPN" SG_ 2633803518 EngineSparkPlug15MaximumVoltage 6260;
BA_ "SPN" SG_ 2633803518 EngineSparkPlug16MaximumVoltage 6261;
BA_ "SPN" SG_ 2633803774 EngineSparkPlug9MaximumVoltage 6254;
BA_ "SPN" SG_ 2633803774 EngineSparkPlug10MaximumVoltage 6255;
BA_ "SPN" SG_ 2633803774 EngineSparkPlug11MaximumVoltage 6256;
BA_ "SPN" SG_ 2633803774 EngineSparkPlug12MaximumVoltage 6257;
BA_ "SPN" SG_ 2633804030 EngineSparkPlug5MaximumVoltage 6250;
BA_ "SPN" SG_ 2633804030 EngineSparkPlug6MaximumVoltage 6251;
BA_ "SPN" SG_ 2633804030 EngineSparkPlug7MaximumVoltage 6252;
BA_ "SPN" SG_ 2633804030 EngineSparkPlug8MaximumVoltage 6253;
BA_ "SPN" SG_ 2633804286 EngineSparkPlug1MaximumVoltage 6246;
BA_ "SPN" SG_ 2633804286 EngineSparkPlug2MaximumVoltage 6247;
BA_ "SPN" SG_ 2633804286 EngineSparkPlug3MaximumVoltage 6248;
BA_ "SPN" SG_ 2633804286 EngineSparkPlug4MaximumVoltage 6249;
BA_ "SPN" SG_ 2633804542 EngineSparkPlug21MinimumVoltage 6242;
BA_ "SPN" SG_ 2633804542 EngineSparkPlug22MinimumVoltage 6243;
BA_ "SPN" SG_ 2633804542 EngineSparkPlug23MinimumVoltage 6244;
BA_ "SPN" SG_ 2633804542 EngineSparkPlug24MinimumVoltage 6245;
BA_ "SPN" SG_ 2633804798 EngineSparkPlug17MinimumVoltage 6238;
BA_ "SPN" SG_ 2633804798 EngineSparkPlug18MinimumVoltage 6239;
BA_ "SPN" SG_ 2633804798 EngineSparkPlug19MinimumVoltage 6240;
BA_ "SPN" SG_ 2633804798 EngineSparkPlug20MinimumVoltage 6241;
BA_ "SPN" SG_ 2633805054 EngineSparkPlug13MinimumVoltage 6234;
BA_ "SPN" SG_ 2633805054 EngineSparkPlug14MinimumVoltage 6235;
BA_ "SPN" SG_ 2633805054 EngineSparkPlug15MinimumVoltage 6236;
BA_ "SPN" SG_ 2633805054 EngineSparkPlug16MinimumVoltage 6237;
BA_ "SPN" SG_ 2633805310 EngineSparkPlug9MinimumVoltage 6230;
BA_ "SPN" SG_ 2633805310 EngineSparkPlug10MinimumVoltage 6231;
BA_ "SPN" SG_ 2633805310 EngineSparkPlug11MinimumVoltage 6232;
BA_ "SPN" SG_ 2633805310 EngineSparkPlug12MinimumVoltage 6233;
BA_ "SPN" SG_ 2633805566 EngineSparkPlug5MinimumVoltage 6226;
BA_ "SPN" SG_ 2633805566 EngineSparkPlug6MinimumVoltage 6227;
BA_ "SPN" SG_ 2633805566 EngineSparkPlug7MinimumVoltage 6228;
BA_ "SPN" SG_ 2633805566 EngineSparkPlug8MinimumVoltage 6229;
BA_ "SPN" SG_ 2633805822 EngineSparkPlug1MinimumVoltage 6222;
BA_ "SPN" SG_ 2633805822 EngineSparkPlug2MinimumVoltage 6223;
BA_ "SPN" SG_ 2633805822 EngineSparkPlug3MinimumVoltage 6224;
BA_ "SPN" SG_ 2633805822 EngineSparkPlug4MinimumVoltage 6225;
BA_ "SPN" SG_ 2633806078 EngIgnitionCtrlModule1TimeRemain 6220;
BA_ "SPN" SG_ 2633806078 EngIgnitionCtrlModule2TimeRemain 6221;
BA_ "SPN" SG_ 2566697470 EngIgnitionCtrlModule1Temp 6214;
BA_ "SPN" SG_ 2566697470 EngIgnitionCtrlModule2Temp 6215;
BA_ "SPN" SG_ 2566697470 EngineIgnitionCtrlModule1State 6216;
BA_ "SPN" SG_ 2566697470 EngineIgnitionCtrlModule2State 6217;
BA_ "SPN" SG_ 2566697726 SwitchedOutput1Current 6112;
BA_ "SPN" SG_ 2566697726 SwitchedOutput2Current 6113;
BA_ "SPN" SG_ 2566697726 SwitchedOutput3Current 6114;
BA_ "SPN" SG_ 2566697726 SwitchedOutput4Current 6115;
BA_ "SPN" SG_ 2566697726 SwitchedOutput5Current 6116;
BA_ "SPN" SG_ 2566697726 SwitchedOutput6Current 6117;
BA_ "SPN" SG_ 2566697726 SwitchedOutput7Current 6118;
BA_ "SPN" SG_ 2566697726 SwitchedOutput8Current 6119;
BA_ "SPN" SG_ 2566697726 SwitchedOutput9Current 6120;
BA_ "SPN" SG_ 2566697726 SwitchedOutput10Current 6121;
BA_ "SPN" SG_ 2566697726 SwitchedOutput11Current 6122;
BA_ "SPN" SG_ 2566697726 SwitchedOutput12Current 6123;
BA_ "SPN" SG_ 2566697726 SwitchedOutput13Current 6124;
BA_ "SPN" SG_ 2566697726 SwitchedOutput14Current 6125;
BA_ "SPN" SG_ 2566697726 SwitchedOutput15Current 6126;
BA_ "SPN" SG_ 2566697726 SwitchedOutput16Current 6127;
BA_ "SPN" SG_ 2566697726 SwitchedOutput17Current 6128;
BA_ "SPN" SG_ 2566697726 SwitchedOutput18Current 6129;
BA_ "SPN" SG_ 2566697726 SwitchedOutput19Current 6130;
BA_ "SPN" SG_ 2566697726 SwitchedOutput20Current 6131;
BA_ "SPN" SG_ 2566697726 SwitchedOutput21Current 6132;
BA_ "SPN" SG_ 2566697726 SwitchedOutput22Current 6133;
BA_ "SPN" SG_ 2566697726 SwitchedOutput23Current 6134;
BA_ "SPN" SG_ 2566697726 SwitchedOutput24Current 6135;
BA_ "SPN" SG_ 2566697726 SwitchedOutput25Current 6136;
BA_ "SPN" SG_ 2566697726 SwitchedOutput26Current 6137;
BA_ "SPN" SG_ 2566697726 SwitchedOutput27Current 6138;
BA_ "SPN" SG_ 2566697726 SwitchedOutput28Current 6139;
BA_ "SPN" SG_ 2566697726 SwitchedOutput29Current 6140;
BA_ "SPN" SG_ 2566697726 SwitchedOutput30Current 6141;
BA_ "SPN" SG_ 2566697726 SwitchedOutput31Current 6142;
BA_ "SPN" SG_ 2566697726 SwitchedOutput32Current 6143;
BA_ "SPN" SG_ 2566697982 FusedOutput1Current 6080;
BA_ "SPN" SG_ 2566697982 FusedOutput2Current 6081;
BA_ "SPN" SG_ 2566697982 FusedOutput3Current 6082;
BA_ "SPN" SG_ 2566697982 FusedOutput4Current 6083;
BA_ "SPN" SG_ 2566697982 FusedOutput5Current 6084;
BA_ "SPN" SG_ 2566697982 FusedOutput6Current 6085;
BA_ "SPN" SG_ 2566697982 FusedOutput7Current 6086;
BA_ "SPN" SG_ 2566697982 FusedOutput8Current 6087;
BA_ "SPN" SG_ 2566697982 FusedOutput9Current 6088;
BA_ "SPN" SG_ 2566697982 FusedOutput10Current 6089;
BA_ "SPN" SG_ 2566697982 FusedOutput11Current 6090;
BA_ "SPN" SG_ 2566697982 FusedOutput12Current 6091;
BA_ "SPN" SG_ 2566697982 FusedOutput13Current 6092;
BA_ "SPN" SG_ 2566697982 FusedOutput14Current 6093;
BA_ "SPN" SG_ 2566697982 FusedOutput15Current 6094;
BA_ "SPN" SG_ 2566697982 FusedOutput16Current 6095;
BA_ "SPN" SG_ 2566697982 FusedOutput17Current 6096;
BA_ "SPN" SG_ 2566697982 FusedOutput18Current 6097;
BA_ "SPN" SG_ 2566697982 FusedOutput19Current 6098;
BA_ "SPN" SG_ 2566697982 FusedOutput20Current 6099;
BA_ "SPN" SG_ 2566697982 FusedOutput21Current 6100;
BA_ "SPN" SG_ 2566697982 FusedOutput22Current 6101;
BA_ "SPN" SG_ 2566697982 FusedOutput23Current 6102;
BA_ "SPN" SG_ 2566697982 FusedOutput24Current 6103;
BA_ "SPN" SG_ 2566697982 FusedOutput25Current 6104;
BA_ "SPN" SG_ 2566697982 FusedOutput26Current 6105;
BA_ "SPN" SG_ 2566697982 FusedOutput27Current 6106;
BA_ "SPN" SG_ 2566697982 FusedOutput28Current 6107;
BA_ "SPN" SG_ 2566697982 FusedOutput29Current 6108;
BA_ "SPN" SG_ 2566697982 FusedOutput30Current 6109;
BA_ "SPN" SG_ 2566697982 FusedOutput31Current 6110;
BA_ "SPN" SG_ 2566697982 FusedOutput32Current 6111;
BA_ "SigType" SG_ 2633755134 HostName 3;
BA_ "SigType" SG_ 2566670078 TireSensorIdentificationNumber 3;
BA_ "SigType" SG_ 2566691326 AssemblyUnitIdentification 3;
VAL_ 2633750526 TransmitPGNsPort 0 "Current port" 1 "Port 1" 2 "Port 2" 3 "Port 3" 4 "Port 4" 5 "Port 5" 6 "Port 6" 7 "Port 7" 8 "Port 8" 9 "Port 9" 10 "Port 10" ;
VAL_ 2633750526 TransmitPGNsPortPendingChangesSt 0 "No pending changes" 1 "Transmit changes are pending" ;
VAL_ 2633750526 TransmitPGNsPortCommandStatus 0 "Positive Acknowledgment" 1 "Negative Acknowledgment" 2 "No Configurable PGNs exist" 7 "Not Available" ;
VAL_ 2633750526 ConfigurableTransPGNCurTransmtSt 0 "PGN is currently configured for transmit" 1 "PGN is not currently configured for transmit" 2 "The PGN transmit capability cannot be modified" 3 "Not Available" ;
VAL_ 2633750526 ConfigurableTransPGNPendngChgSt 0 "Pending transmit change to disable" 1 "Pending transmit change to enable" 2 "No pending transmit change" 3 "Not Available" ;
VAL_ 2633750526 ConfigurableTransmtPGNModifiedSt 0 "PGN's transmit status could not be modified" 1 "PGN's transmit status was not requested to be modified" 2 "PGN's transmit status could be modified as requested" 3 "Not Available" ;
VAL_ 2566642942 LockStatusOfDoor21 0 "Unlocked" 1 "Locked" 2 "Error" 3 "Not available" ;
VAL_ 2566642942 OpenStatusOfDoor21 0 "Door closed" 1 "Door opened" 2 "Error" 3 "Not available" ;
VAL_ 2566642942 EnableStatusOfDoor21 0 "Door disabled" 1 "Door enabled" 2 "Error" 3 "Not available" ;
VAL_ 2566642942 LockStatusOfDoor22 0 "Unlocked" 1 "Locked" 2 "Error" 3 "Not available" ;
VAL_ 2566642942 OpenStatusOfDoor22 0 "Door closed" 1 "Door opened" 2 "Error" 3 "Not available" ;
VAL_ 2566642942 EnableStatusOfDoor22 0 "Door disabled" 1 "Door enabled" 2 "Error" 3 "Not available" ;
VAL_ 2566642942 LockStatusOfDoor23 0 "Unlocked" 1 "Locked" 2 "Error" 3 "Not available" ;
VAL_ 2566642942 OpenStatusOfDoor23 0 "Door closed" 1 "Door opened" 2 "Error" 3 "Not available" ;
VAL_ 2566642942 EnableStatusOfDoor23 0 "Door disabled" 1 "Door enabled" 2 "Error" 3 "Not available" ;
VAL_ 2566642942 LockStatusOfDoor24 0 "Unlocked" 1 "Locked" 2 "Error" 3 "Not available" ;
VAL_ 2566642942 OpenStatusOfDoor24 0 "Door closed" 1 "Door opened" 2 "Error" 3 "Not available" ;
VAL_ 2566642942 EnableStatusOfDoor24 0 "Door disabled" 1 "Door enabled" 2 "Error" 3 "Not available" ;
VAL_ 2566642942 LockStatusOfDoor25 0 "Unlocked" 1 "Locked" 2 "Error" 3 "Not available" ;
VAL_ 2566642942 OpenStatusOfDoor25 0 "Door closed" 1 "Door opened" 2 "Error" 3 "Not available" ;
VAL_ 2566642942 EnableStatusOfDoor25 0 "Door disabled" 1 "Door enabled" 2 "Error" 3 "Not available" ;
VAL_ 2566642942 LockStatusOfDoor26 0 "Unlocked" 1 "Locked" 2 "Error" 3 "Not available" ;
VAL_ 2566642942 OpenStatusOfDoor26 0 "Door closed" 1 "Door opened" 2 "Error" 3 "Not available" ;
VAL_ 2566642942 EnableStatusOfDoor26 0 "Door disabled" 1 "Door enabled" 2 "Error" 3 "Not available" ;
VAL_ 2566642942 LockStatusOfDoor27 0 "Unlocked" 1 "Locked" 2 "Error" 3 "Not available" ;
VAL_ 2566642942 OpenStatusOfDoor27 0 "Door closed" 1 "Door opened" 2 "Error" 3 "Not available" ;
VAL_ 2566642942 EnableStatusOfDoor27 0 "Door disabled" 1 "Door enabled" 2 "Error" 3 "Not available" ;
VAL_ 2566642942 LockStatusOfDoor28 0 "Unlocked" 1 "Locked" 2 "Error" 3 "Not available" ;
VAL_ 2566642942 OpenStatusOfDoor28 0 "Door closed" 1 "Door opened" 2 "Error" 3 "Not available" ;
VAL_ 2566642942 EnableStatusOfDoor28 0 "Door disabled" 1 "Door enabled" 2 "Error" 3 "Not available" ;
VAL_ 2566642942 LockStatusOfDoor29 0 "Unlocked" 1 "Locked" 2 "Error" 3 "Not available" ;
VAL_ 2566642942 OpenStatusOfDoor29 0 "Door closed" 1 "Door opened" 2 "Error" 3 "Not available" ;
VAL_ 2566642942 EnableStatusOfDoor29 0 "Door disabled" 1 "Door enabled" 2 "Error" 3 "Not available" ;
VAL_ 2566642942 LockStatusOfDoor30 0 "Unlocked" 1 "Locked" 2 "Error" 3 "Not available" ;
VAL_ 2566642942 OpenStatusOfDoor30 0 "Door closed" 1 "Door opened" 2 "Error" 3 "Not available" ;
VAL_ 2566642942 EnableStatusOfDoor30 0 "Door disabled" 1 "Door enabled" 2 "Error" 3 "Not available" ;
VAL_ 2566643198 LockStatusOfDoor11 0 "Unlocked " 1 "Locked" 2 "Error" 3 "Not available" ;
VAL_ 2566643198 OpenStatusOfDoor11 0 "Door closed" 1 "Door opened" 2 "Error" 3 "Not available" ;
VAL_ 2566643198 EnableStatusOfDoor11 0 "Door disabled" 1 "Door enabled" 2 "Error" 3 "Not available" ;
VAL_ 2566643198 LockStatusOfDoor12 0 "Unlocked" 1 "Locked" 2 "Error" 3 "Not available" ;
VAL_ 2566643198 OpenStatusOfDoor12 0 "Door closed" 1 "Door opened" 2 "Error" 3 "Not available" ;
VAL_ 2566643198 EnableStatusOfDoor12 0 "Door disabled" 1 "Door enabled" 2 "Error" 3 "Not available" ;
VAL_ 2566643198 LockStatusOfDoor13 0 "Unlocked" 1 "Locked" 2 "Error" 3 "Not available" ;
VAL_ 2566643198 OpenStatusOfDoor13 0 "Door closed" 1 "Door opened" 2 "Error" 3 "Not available" ;
VAL_ 2566643198 EnableStatusOfDoor13 0 "Door disabled" 1 "Door enabled" 2 "Error" 3 "Not available" ;
VAL_ 2566643198 LockStatusOfDoor14 0 "Unlocked" 1 "Locked" 2 "Error" 3 "Not available" ;
VAL_ 2566643198 OpenStatusOfDoor14 0 "Door closed" 1 "Door opened" 2 "Error" 3 "Not available" ;
VAL_ 2566643198 EnableStatusOfDoor14 0 "Door disabled" 1 "Door enabled" 2 "Error" 3 "Not available" ;
VAL_ 2566643198 LockStatusOfDoor15 0 "Unlocked" 1 "Locked" 2 "Error" 3 "Not available" ;
VAL_ 2566643198 OpenStatusOfDoor15 0 "Door closed" 1 "Door opened" 2 "Error" 3 "Not available" ;
VAL_ 2566643198 EnableStatusOfDoor15 0 "Door disabled" 1 "Door enabled" 2 "Error" 3 "Not available" ;
VAL_ 2566643198 LockStatusOfDoor16 0 "Unlocked" 1 "Locked" 2 "Error" 3 "Not available" ;
VAL_ 2566643198 OpenStatusOfDoor16 0 "Door closed" 1 "Door opened" 2 "Error" 3 "Not available" ;
VAL_ 2566643198 EnableStatusOfDoor16 0 "Door disabled" 1 "Door enabled" 2 "Error" 3 "Not available" ;
VAL_ 2566643198 LockStatusOfDoor17 0 "Unlocked" 1 "Locked" 2 "Error" 3 "Not available" ;
VAL_ 2566643198 OpenStatusOfDoor17 0 "Door closed" 1 "Door opened" 2 "Error" 3 "Not available" ;
VAL_ 2566643198 EnableStatusOfDoor17 0 "Door disabled" 1 "Door enabled" 2 "Error" 3 "Not available" ;
VAL_ 2566643198 LockStatusOfDoor18 0 "Unlocked" 1 "Locked" 2 "Error" 3 "Not available" ;
VAL_ 2566643198 OpenStatusOfDoor18 0 "Door closed" 1 "Door opened" 2 "Error" 3 "Not available" ;
VAL_ 2566643198 EnableStatusOfDoor18 0 "Door disabled" 1 "Door enabled" 2 "Error" 3 "Not available" ;
VAL_ 2566643198 LockStatusOfDoor19 0 "Unlocked" 1 "Locked" 2 "Error" 3 "Not available" ;
VAL_ 2566643198 OpenStatusOfDoor19 0 "Door closed" 1 "Door opened" 2 "Error" 3 "Not available" ;
VAL_ 2566643198 EnableStatusOfDoor19 0 "Door disabled" 1 "Door enabled" 2 "Error" 3 "Not available" ;
VAL_ 2566643198 LockStatusOfDoor20 0 "Unlocked" 1 "Locked" 2 "Error" 3 "Not available" ;
VAL_ 2566643198 OpenStatusOfDoor20 0 "Door closed" 1 "Door opened" 2 "Error" 3 "Not available" ;
VAL_ 2566643198 EnableStatusOfDoor20 0 "Door disabled" 1 "Door enabled" 2 "Error" 3 "Not available" ;
VAL_ 2566644990 DrvrSdeFuelReceptacle1CoverStat 0 "Receptacle cover is detached" 1 "Receptacle cover is attached" 2 "Error" 3 "Not available" ;
VAL_ 2566644990 DrvrSdeFuelReceptacle2CoverStat 0 "Receptacle cover is detached" 1 "Receptacle cover is attached" 2 "Error" 3 "Not available" ;
VAL_ 2566644990 PassngSdeFuelReceptacle1CoverSt 0 "Receptacle cover is detached" 1 "Receptacle cover is attached" 2 "Error" 3 "Not available" ;
VAL_ 2566644990 PassngSdeFuelReceptacle2CoverSt 0 "Receptacle cover is detached" 1 "Receptacle cover is attached" 2 "Error" 3 "Not available" ;
VAL_ 2566644990 FrontFuelReceptacleCoverStatus 0 "Receptacle cover is detached" 1 "Receptacle cover is attached" 2 "Error" 3 "Not available" ;
VAL_ 2566645246 HVESFanEnableStatus 0 "Fan Off" 1 "Fan On - Normal, Forward, or Default Direction" 2 "Fan On - Reverse Direction" 3 "Not available" ;
VAL_ 2566645246 HVESFanStatusReasonCode 0 "Normal Operation" 1 "Unable to Start" 2 "Over-Voltage Protection Shutdown" 3 "Under-Voltage Protection Shutdown" 4 "Over-Temperature Protection Shutdown" 5 "Speed Limited due to current protection limit" 6 "Speed limited due to maximum system design capability" 7 "Reserved" 8 "Reserved" 9 "Reserved" 10 "Reserved" 11 "Reserved" 12 "Reserved" 13 "Reserved" 14 "Reserved" 15 "Not Available" ;
VAL_ 2566645246 HVESFanCommandStatus 0 "Internal Command" 1 "External Command" 2 "Default Command" 3 "Not Available" ;
VAL_ 2566645246 HVESFanServiceIndicator 0 "Service Not Required" 1 "Service Required" 2 "Reserved" 3 "Not Available" ;
VAL_ 2566645246 HVESFanOperatingStatus 0 "Normal Operation" 1 "Derated Operation" 2 "Not Operable" 3 "Not Available" ;
VAL_ 2566645246 HVESFanInstance 0 "Instance 1" 1 "Instance 2" 2 "Instance 3" 3 "Instance 4" 4 "Instance 5" 5 "Instance 6" 6 "Instance 7" 7 "Instance 8" 8 "Instance 9" 9 "Instance 10" 10 "Instance 11" 11 "Instance 12" 12 "Instance 13" 13 "Instance 14" 14 "Instance 15" 15 "Not available / Instance not specified" ;
VAL_ 2365318910 HVESFanEnableCommand 0 "Fan Off" 1 "Fan On Normal/Default Direction" 2 "Fan On Reverse Direction" 3 "Don't Care/Take no action" ;
VAL_ 2365318910 HVESFanPowerHold 0 "Power Hold Disabled" 1 "Power Hold Enabled" 2 "Reserved" 3 "Don't Care/Take no action" ;
VAL_ 2365318910 HVESFanInstance1 0 "Command applied to this Fan Instance" 1 "No Command applied to this Fan Instance" ;
VAL_ 2365318910 HVESFanInstance2 0 "Command applied to this Fan Instance" 1 "No Command applied to this Fan Instance" ;
VAL_ 2365318910 HVESFanInstance3 0 "Command applied to this Fan Instance" 1 "No Command applied to this Fan Instance" ;
VAL_ 2365318910 HVESFanInstance4 0 "Command applied to this Fan Instance" 1 "No Command applied to this Fan Instance" ;
VAL_ 2365318910 HVESFanInstance5 0 "Command applied to this Fan Instance" 1 "No Command applied to this Fan Instance" ;
VAL_ 2365318910 HVESFanInstance6 0 "Command applied to this Fan Instance" 1 "No Command applied to this Fan Instance" ;
VAL_ 2365318910 HVESFanInstance7 0 "Command applied to this Fan Instance" 1 "No Command applied to this Fan Instance" ;
VAL_ 2365318910 HVESFanInstance8 0 "Command applied to this Fan Instance" 1 "No Command applied to this Fan Instance" ;
VAL_ 2365318910 HVESFanInstance9 0 "Command applied to this Fan Instance" 1 "No Command applied to this Fan Instance" ;
VAL_ 2365318910 HVESFanInstance10 0 "Command applied to this Fan Instance" 1 "No Command applied to this Fan Instance" ;
VAL_ 2365318910 HVESFanInstance11 0 "Command applied to this Fan Instance" 1 "No Command applied to this Fan Instance" ;
VAL_ 2365318910 HVESFanInstance12 0 "Command applied to this Fan Instance" 1 "No Command applied to this Fan Instance" ;
VAL_ 2365318910 HVESFanInstance13 0 "Command applied to this Fan Instance" 1 "No Command applied to this Fan Instance" ;
VAL_ 2365318910 HVESFanInstance14 0 "Command applied to this Fan Instance" 1 "No Command applied to this Fan Instance" ;
VAL_ 2365318910 HVESFanInstance15 0 "Command applied to this Fan Instance" 1 "No Command applied to this Fan Instance" ;
VAL_ 2633755390 DHCPStatus 0 "Not Configured (static IP)" 1 "Obtaining IP" 2 "IP Leased" 3 "Contacting DHCP Server" 4 "SAE Reserved" 5 "SAE Reserved" 6 "SAE Reserved" 7 "SAE Reserved" 8 "SAE Reserved" 9 "SAE Reserved" 10 "SAE Reserved" 11 "SAE Reserved" 12 "SAE Reserved" 13 "SAE Reserved" 14 "Error" 15 "Not Available" ;
VAL_ 2633755390 EthernetLinkStatus 0 "Ethernet Link Down" 1 "Ethernet Link Up" 2 "Error" 3 "Not Supported" ;
VAL_ 2566648318 OilDebrisMontEnvironmentStatus 0 "Acceptable environment" 1 "Excessive noise in signal" 2 "Reserved" 3 "Not available" ;
VAL_ 2566648318 OilDebrisMontSensingElementStat 0 "Sensing element OK" 1 "Fault with sensing element" 2 "Reserved" 3 "Not available" ;
VAL_ 2566648318 OilDebrisMontSigPrcngElctrncsSt 0 "Electronics functioning normally" 1 "Fault in electronics" 2 "Reserved" 3 "Not available" ;
VAL_ 2566648318 OilDebrisMontElctrncsTempStat 0 "Acceptable temperature" 1 "Temperature is outside of limits" 2 "Reserved" 3 "Not available" ;
VAL_ 2566649854 PropulsionMtrCoolntFn3EnblStatus 0 "Accessory Motor Off" 1 "Accessory Motor On - Normal, Forward, or Default Direction" 2 "Accessory Motor On - Reverse Direction" 3 "Not available" ;
VAL_ 2566649854 ProplsnMtrClntFn3CtrllerStRsnCd 0 "Normal Operation" 1 "Unable to Start" 2 "Over-Voltage Protection Shutdown" 3 "Under-Voltage Protection Shutdown" 4 "Over-Temperature Protection Shutdown" 5 "Speed Limited due to current protection limit" 6 "Speed limited due to maximum system design capability" 7 "Speed limited due to torque limit" 8 "Speed limited due to over-temperature protection" 15 "Not Available" ;
VAL_ 2566649854 ProplsnMtrClntFn3CtrllerCmdStat 0 "Internal Command" 1 "External Command" 2 "Default Command" 3 "Not Available" ;
VAL_ 2566649854 ProplsnMtrCoolntFn3SrvcIndictr 0 "Service Not Required" 1 "Service Required" 2 "Reserved" 3 "Not Available" ;
VAL_ 2566649854 ProplsnMtrCoolntFn3OprtngStatus 0 "Normal Operation" 1 "Derated Operation" 2 "Not Operable" 3 "Not Available" ;
VAL_ 2566650110 PropulsionMtrCoolntFn2EnblStatus 0 "Accessory Motor Off" 1 "Accessory Motor On - Normal, Forward, or Default Direction" 2 "Accessory Motor On - Reverse Direction" 3 "Not available" ;
VAL_ 2566650110 ProplsnMtrClntFn2CtrllerStRsnCd 0 "Normal Operation" 1 "Unable to Start" 2 "Over-Voltage Protection Shutdown" 3 "Under-Voltage Protection Shutdown" 4 "Over-Temperature Protection Shutdown" 5 "Speed Limited due to current protection limit" 6 "Speed limited due to maximum system design capability" 7 "Speed limited due to torque limit" 8 "Speed limited due to over-temperature protection" 15 "Not Available" ;
VAL_ 2566650110 ProplsnMtrClntFn2CtrllerCmdStat 0 "Internal Command" 1 "External Command" 2 "Default Command" 3 "Not Available" ;
VAL_ 2566650110 ProplsnMtrCoolntFn2SrvcIndictr 0 "Service Not Required" 1 "Service Required" 2 "Reserved" 3 "Not Available" ;
VAL_ 2566650110 ProplsnMtrCoolntFn2OprtngStatus 0 "Normal Operation" 1 "Derated Operation" 2 "Not Operable" 3 "Not Available" ;
VAL_ 2566650366 PropulsionMtrCoolntFn1EnblStatus 0 "Accessory Motor Off" 1 "Accessory Motor On - Normal, Forward, or Default Direction" 2 "Accessory Motor On - Reverse Direction" 3 "Not available" ;
VAL_ 2566650366 ProplsnMtrClntFn1CtrllerStRsnCd 0 "Normal Operation" 1 "Unable to Start" 2 "Over-Voltage Protection Shutdown" 3 "Under-Voltage Protection Shutdown" 4 "Over-Temperature Protection Shutdown" 5 "Speed Limited due to current protection limit" 6 "Speed limited due to maximum system design capability" 7 "Speed limited due to torque limit" 8 "Speed limited due to over-temperature protection" 15 "Not Available" ;
VAL_ 2566650366 ProplsnMtrClntFn1CtrllerCmdStat 0 "Internal Command" 1 "External Command" 2 "Default Command" 3 "Not Available" ;
VAL_ 2566650366 ProplsnMtrCoolntFn1SrvcIndictr 0 "Service Not Required" 1 "Service Required" 2 "Reserved" 3 "Not Available" ;
VAL_ 2566650366 ProplsnMtrCoolntFn1OprtngStatus 0 "Normal Operation" 1 "Derated Operation" 2 "Not Operable" 3 "Not Available" ;
VAL_ 2566650622 PowerElctrncsCoolntFn3EnblStatus 0 "Accessory Motor Off" 1 "Accessory Motor On - Normal, Forward, or Default Direction" 2 "Accessory Motor On - Reverse Direction" 3 "Not available" ;
VAL_ 2566650622 PwrElctrncsClntFn3CtrllerStRsnCd 0 "Normal Operation" 1 "Unable to Start" 2 "Over-Voltage Protection Shutdown" 3 "Under-Voltage Protection Shutdown" 4 "Over-Temperature Protection Shutdown" 5 "Speed Limited due to current protection limit" 6 "Speed limited due to maximum system design capability" 7 "Speed limited due to torque limit" 8 "Speed limited due to over-temperature protection" 15 "Not Available" ;
VAL_ 2566650622 PwrElctrncsClntFn3CtrllerCmdStat 0 "Internal Command" 1 "External Command" 2 "Default Command" 3 "Not Available" ;
VAL_ 2566650622 PwrElctrncsCoolntFn3SrvcIndictr 0 "Service Not Required" 1 "Service Required" 2 "Reserved" 3 "Not Available" ;
VAL_ 2566650622 PwrElctrncsCoolntFn3OprtngStatus 0 "Normal Operation" 1 "Derated Operation" 2 "Not Operable" 3 "Not Available" ;
VAL_ 2566650878 PowerElctrncsCoolntFn2EnblStatus 0 "Accessory Motor Off" 1 "Accessory Motor On - Normal, Forward, or Default Direction" 2 "Accessory Motor On - Reverse Direction" 3 "Not available" ;
VAL_ 2566650878 PwrElctrncsClntFn2CtrllerStRsnCd 0 "Normal Operation" 1 "Unable to Start" 2 "Over-Voltage Protection Shutdown" 3 "Under-Voltage Protection Shutdown" 4 "Over-Temperature Protection Shutdown" 5 "Speed Limited due to current protection limit" 6 "Speed limited due to maximum system design capability" 7 "Speed limited due to torque limit" 8 "Speed limited due to over-temperature protection" 15 "Not Available" ;
VAL_ 2566650878 PwrElctrncsClntFn2CtrllerCmdStat 0 "Internal Command" 1 "External Command" 2 "Default Command" 3 "Not Available" ;
VAL_ 2566650878 PwrElctrncsCoolntFn2SrvcIndictr 0 "Service Not Required" 1 "Service Required" 2 "Reserved" 3 "Not Available" ;
VAL_ 2566650878 PwrElctrncsCoolntFn2OprtngStatus 0 "Normal Operation" 1 "Derated Operation" 2 "Not Operable" 3 "Not Available" ;
VAL_ 2566651134 PowerElctrncsCoolntFn1EnblStatus 0 "Accessory Motor Off" 1 "Accessory Motor On - Normal, Forward, or Default Direction" 2 "Accessory Motor On - Reverse Direction" 3 "Not available" ;
VAL_ 2566651134 PwrElctrncsClntFn1CtrllerStRsnCd 0 "Normal Operation" 1 "Unable to Start" 2 "Over-Voltage Protection Shutdown" 3 "Under-Voltage Protection Shutdown" 4 "Over-Temperature Protection Shutdown" 5 "Speed Limited due to current protection limit" 6 "Speed limited due to maximum system design capability" 7 "Speed limited due to torque limit" 8 "Speed limited due to over-temperature protection" 15 "Not Available" ;
VAL_ 2566651134 PwrElctrncsClntFn1CtrllerCmdStat 0 "Internal Command" 1 "External Command" 2 "Default Command" 3 "Not Available" ;
VAL_ 2566651134 PwrElctrncsCoolntFn1SrvcIndictr 0 "Service Not Required" 1 "Service Required" 2 "Reserved" 3 "Not Available" ;
VAL_ 2566651134 PwrElctrncsCoolntFn1OprtngStatus 0 "Normal Operation" 1 "Derated Operation" 2 "Not Operable" 3 "Not Available" ;
VAL_ 2566651390 PropulsionMotorOilPumpEnblStatus 0 "Accessory Motor Off" 1 "Accessory Motor On - Normal, Forward, or Default Direction" 2 "Accessory Motor On - Reverse Direction" 3 "Not available" ;
VAL_ 2566651390 ProplsnMtrOilPmpCtrllerStatRsnCd 0 "Normal Operation" 1 "Unable to Start" 2 "Over-Voltage Protection Shutdown" 3 "Under-Voltage Protection Shutdown" 4 "Over-Temperature Protection Shutdown" 5 "Speed Limited due to current protection limit" 6 "Speed limited due to maximum system design capability" 7 "Speed limited due to torque limit" 8 "Speed limited due to over-temperature protection" 15 "Not Available" ;
VAL_ 2566651390 ProplsnMtrOilPmpCtrllerCmdStatus 0 "Internal Command" 1 "External Command" 2 "Default Command" 3 "Not Available" ;
VAL_ 2566651390 ProplsnMtrOilPumpServiceIndictr 0 "Service Not Required" 1 "Service Required" 2 "Reserved" 3 "Not Available" ;
VAL_ 2566651390 PropulsionMtrOilPumpOprtngStatus 0 "Normal Operation" 1 "Derated Operation" 2 "Not Operable" 3 "Not Available" ;
VAL_ 2566651646 ProplsnMtrCoolntPumpEnblStatus 0 "Accessory Motor Off" 1 "Accessory Motor On - Normal, Forward, or Default Direction" 2 "Accessory Motor On - Reverse Direction" 3 "Not available" ;
VAL_ 2566651646 ProplsnMtrClntPmpCtrllerStRsnCd 0 "Normal Operation" 1 "Unable to Start" 2 "Over-Voltage Protection Shutdown" 3 "Under-Voltage Protection Shutdown" 4 "Over-Temperature Protection Shutdown" 5 "Speed Limited due to current protection limit" 6 "Speed limited due to maximum system design capability" 7 "Speed limited due to torque limit" 8 "Speed limited due to over-temperature protection" 15 "Not Available" ;
VAL_ 2566651646 ProplsnMtrClntPmpCtrllerCmdStat 0 "Internal Command" 1 "External Command" 2 "Default Command" 3 "Not Available" ;
VAL_ 2566651646 ProplsnMtrCoolntPmpSrvcIndictr 0 "Service Not Required" 1 "Service Required" 2 "Reserved" 3 "Not Available" ;
VAL_ 2566651646 ProplsnMtrCoolntPumpOprtngStatus 0 "Normal Operation" 1 "Derated Operation" 2 "Not Operable" 3 "Not Available" ;
VAL_ 2566651902 PwrElctrncsCoolntPumpEnblStatus 0 "Accessory Motor Off" 1 "Accessory Motor On - Normal, Forward, or Default Direction" 2 "Accessory Motor On - Reverse Direction" 3 "Not available" ;
VAL_ 2566651902 PwrElctrncsClntPmpCtrllerStRsnCd 0 "Normal Operation" 1 "Unable to Start" 2 "Over-Voltage Protection Shutdown" 3 "Under-Voltage Protection Shutdown" 4 "Over-Temperature Protection Shutdown" 5 "Speed Limited due to current protection limit" 6 "Speed limited due to maximum system design capability" 7 "Speed limited due to torque limit" 8 "Speed limited due to over-temperature protection" 15 "Not Available" ;
VAL_ 2566651902 PwrElctrncsClntPmpCtrllerCmdStat 0 "Internal Command" 1 "External Command" 2 "Default Command" 3 "Not Available" ;
VAL_ 2566651902 PwrElctrncsCoolntPmpSrvcIndictr 0 "Service Not Required" 1 "Service Required" 2 "Reserved" 3 "Not Available" ;
VAL_ 2566651902 PwrElctrncsCoolntPmpOprtngStatus 0 "Normal Operation" 1 "Derated Operation" 2 "Not Operable" 3 "Not Available" ;
VAL_ 2566652414 ElectrfdAccssryMotorEnableStatus 0 "Accessory Motor Off" 1 "Accessory Motor On - Normal, Forward, or Default Direction" 2 "Accessory Motor On - Reverse Direction" 3 "Not available" ;
VAL_ 2566652414 ElectrfdAccssryMtrCtrllerStRsnCd 0 "Normal Operation" 1 "Unable to Start" 2 "Over-Voltage Protection Shutdown" 3 "Under-Voltage Protection Shutdown" 4 "Over-Temperature Protection Shutdown" 5 "Speed Limited due to current protection limit" 6 "Speed limited due to maximum system design capability" 7 "Speed limited due to torque limit" 8 "Speed limited due to over-temperature protection" 15 "Not Available" ;
VAL_ 2566652414 ElectrfdAccssryMtrCtrllerCmdStat 0 "Internal Command" 1 "External Command" 2 "Default Command" 3 "Not Available" ;
VAL_ 2566652414 ElectrfdAccssryMtrServiceIndictr 0 "Service Not Required" 1 "Service Required" 2 "Reserved" 3 "Not Available" ;
VAL_ 2566652414 ElectrfdAccssryMtrOprtngStatus 0 "Normal Operation" 1 "Derated Operation" 2 "Not Operable" 3 "Not Available" ;
VAL_ 2566652414 ElectrifiedAccssryMotorInstance 0 "Instance 1" 1 "Instance 2" 2 "Instance 3" 3 "Instance 4" 4 "Instance 5" 5 "Instance 6" 6 "Instance 7" 7 "Instance 8" 8 "Instance 9" 9 "Instance 10" 10 "Instance 11" 11 "Instance 12" 12 "Instance 13" 13 "Instance 14" 14 "Instance 15" 15 "Not available / Instance not specified" ;
VAL_ 2566652670 Aft1DslExhstFldDsngSysFrozen 0 "DEF system is not frozen" 1 "DEF system is frozen" 2 "Error" 3 "Not available" ;
VAL_ 2566652670 Aft2DslExhstFldDsngSysFrozen 0 "DEF system is not frozen" 1 "DEF system is frozen" 2 "Error" 3 "Not available" ;
VAL_ 2566652926 SLIBattryPack1Battry4StateCharge 251 "Conditions are not acceptable for a valid measurement." ;
VAL_ 2566652926 SLIBatteryPack1Battery4Health 251 "Conditions are not acceptable for a valid measurement." ;
VAL_ 2566652926 SLIBattPack1Batt4PrdctMnCrnkVltg 251 "Conditions are not acceptable for a valid measurement." ;
VAL_ 2566652926 SLIBattryPack1Sensor4InitStatus 0 "Initialization process has not started. " 10 "Initialization process is complete." ;
VAL_ 2566653438 SLIBattryPack1Battry3StateCharge 251 "Conditions are not acceptable for a valid measurement." ;
VAL_ 2566653438 SLIBatteryPack1Battery3Health 251 "Conditions are not acceptable for a valid measurement." ;
VAL_ 2566653438 SLIBattPack1Batt3PrdctMnCrnkVltg 251 "Conditions are not acceptable for a valid measurement." ;
VAL_ 2566653438 SLIBattryPack1Sensor3InitStatus 0 "Initialization process has not started. " 10 "Initialization process is complete." ;
VAL_ 2566653950 SLIBattryPack1Battry2StateCharge 251 "Conditions are not acceptable for a valid measurement." ;
VAL_ 2566653950 SLIBatteryPack1Battery2Health 251 "Conditions are not acceptable for a valid measurement." ;
VAL_ 2566653950 SLIBattPack1Batt2PrdctMnCrnkVltg 251 "Conditions are not acceptable for a valid measurement." ;
VAL_ 2566653950 SLIBattryPack1Sensor2InitStatus 0 "Initialization process has not started. " 10 "Initialization process is complete." ;
VAL_ 2566654462 SLIBattryPack1Battry1StateCharge 251 "Conditions are not acceptable for a valid measurement." ;
VAL_ 2566654462 SLIBatteryPack1Battery1Health 251 "Conditions are not acceptable for a valid measurement." ;
VAL_ 2566654462 SLIBattPack1Batt1PrdctMnCrnkVltg 251 "Conditions are not acceptable for a valid measurement." ;
VAL_ 2566654462 SLIBattryPack1Sensor1InitStatus 0 "Initialization process has not started. " 10 "Initialization process is complete." ;
VAL_ 2633764094 CanisterVentValve 0 "Vent Valve is Closed" 1 "Vent Valve is Open" 2 "Error" 3 "Not Available" ;
VAL_ 2633764094 CanisterPurgeValveCommand 0 "Fully closed" 100 "Fully open" ;
VAL_ 2499547902 CabDoorsLockActuationCommand 0 "Unlock left front cab door latch" 1 "Unlock right front cab door latch" 2 "Unlock left rear cab door latch" 3 "Unlock right rear cab door latch" 4 "Unlock all cab door latches" 5 "Lock all cab door latches" 6 "Reserved" 7 "Take no action" ;
VAL_ 2499547902 RemoteCabDoorLockRequest 0 "Request unlock left front cab door latch" 1 "Request unlock right front cab door latch" 2 "Request unlock left rear cab door latch" 3 "Request unlock right rear cab door latch" 4 "Request unlock all cab door latches" 5 "Request lock all cab door latches" 6 "Reserved" 7 "Take no action" ;
VAL_ 2499547902 LeftFrontWindowPositionCommand 0 "Window move up" 1 "Window move down" 2 "Window auto up" 3 "Window auto down" 4 "Reserved" 5 "Reserved" 6 "Reserved" 7 "Take no action" ;
VAL_ 2499547902 RightFrontWindowPositionCommand 0 "Window move up" 1 "Window move down" 2 "Window auto up" 3 "Window auto down" 4 "Reserved" 5 "Reserved" 6 "Reserved" 7 "Take no action" ;
VAL_ 2499547902 LeftRearWindowPositionCommand 0 "Window move up" 1 "Window move down" 2 "Window auto up" 3 "Window auto down" 4 "Reserved" 5 "Reserved" 6 "Reserved" 7 "Take no action" ;
VAL_ 2499547902 RightRearWindowPositionCommand 0 "Window move up" 1 "Window move down" 2 "Window auto up" 3 "Window auto down" 4 "Reserved" 5 "Reserved" 6 "Reserved" 7 "Take no action" ;
VAL_ 2499547902 MirrorLeft1HorizontalCommand 0 "Move left" 1 "Move right" 2 "Reserved" 3 "Take no action" ;
VAL_ 2499547902 MirrorLeft1VerticalCommand 0 "Move up" 1 "Move down" 2 "Reserved" 3 "Take no action" ;
VAL_ 2499547902 MirrorRight1HorizontalCommand 0 "Move left" 1 "Move right" 2 "Reserved" 3 "Take no action" ;
VAL_ 2499547902 MirrorRight1VerticalCommand 0 "Move up" 1 "Move down" 2 "Reserved" 3 "Take no action" ;
VAL_ 2499547902 MirrorLeft2HorizontalCommand 0 "Move left" 1 "Move right" 2 "Reserved" 3 "Take no action" ;
VAL_ 2499547902 MirrorLeft2VerticalCommand 0 "Move up" 1 "Move down" 2 "Reserved" 3 "Take no action" ;
VAL_ 2499547902 MirrorRight2HorizontalCommand 0 "Move left" 1 "Move right" 2 "Reserved" 3 "Take no action" ;
VAL_ 2499547902 MirrorRight2VerticalCommand 0 "Move up" 1 "Move down" 2 "Reserved" 3 "Take no action" ;
VAL_ 2499547902 MirrorLeft1HeatCommand 0 "Mirror heat off" 1 "Mirror heat on" 2 "Reserved" 3 "Take no action" ;
VAL_ 2499547902 MirrorRight1HeatCommand 0 "Mirror heat off" 1 "Mirror heat on" 2 "Reserved" 3 "Take no action" ;
VAL_ 2499547902 MirrorLeft2HeatCommand 0 "Mirror heat off" 1 "Mirror heat on" 2 "Reserved" 3 "Take no action" ;
VAL_ 2499547902 MirrorRight2HeatCommand 0 "Mirror heat off" 1 "Mirror heat on" 2 "Reserved" 3 "Take no action" ;
VAL_ 2499548158 LeftFrontCabDoorLatchPosition 0 "Door Latch Open" 1 "Door Latch Fully Closed/Latched" 2 "Door Latch Ajar" 3 "Reserved" 4 "Reserved" 5 "Reserved" 6 "Error" 7 "Not Available" ;
VAL_ 2499548158 RightFrontCabDoorLatchPosition 0 "Door Latch Open" 1 "Door Latch Fully Closed/Latched" 2 "Door Latch Ajar" 3 "Reserved" 4 "Reserved" 5 "Reserved" 6 "Error" 7 "Not Available" ;
VAL_ 2499548158 LeftRearCabDoorLatchPosition 0 "Door Latch Open" 1 "Door Latch Fully Closed/Latched" 2 "Door Latch Ajar" 3 "Reserved" 4 "Reserved" 5 "Reserved" 6 "Error" 7 "Not Available" ;
VAL_ 2499548158 RightRearCabDoorLatchPosition 0 "Door Latch Open" 1 "Door Latch Fully Closed/Latched" 2 "Door Latch Ajar" 3 "Reserved" 4 "Reserved" 5 "Reserved" 6 "Error" 7 "Not Available" ;
VAL_ 2566661374 Aftrtrtmnt2DslExhstFldTnkVolume2 251 "Conditions are not acceptable for a valid measurement." ;
VAL_ 2566661630 Aftrtrtmnt1DslExhstFldTnkVolume2 251 "Conditions are not acceptable for a valid measurement." ;
VAL_ 2566662654 LftDistToLaneMarkFrmVhclsMiddle 251 "not in range" 252 "not reliable" 253 "reserved / not used" 254 "error" 255 "not available or not installed" ;
VAL_ 2566662654 RghtDistToLaneMarkFrmVhclsMiddle 251 "not in range" 252 "not reliable" 253 "reserved / not used" 254 "error" 255 "not available or not installed" ;
VAL_ 2566662654 RoadCurvatureBasedOnLaneMarks 64257 "not in range" 64258 "not reliable" ;
VAL_ 2566662654 LaneDepartureAngleLeft 251 "not in range" 252 "not reliable" 253 "reserved / not used" 254 "error" 255 "not available or not installed" ;
VAL_ 2566662654 LaneDepartureAngleRight 251 "not in range" 252 "not reliable" 253 "reserved / not used" 254 "error" 255 "not available or not installed" ;
VAL_ 2566662654 LaneMarkQualityOnTheLeftSide 0 "no lane marks detected" 1 "low reliablity of detected lane marks" 2 "good reliablity of detected lane marks" 3 "perfect recognition of lane marks" 6 "error" 7 "not available or not installed" ;
VAL_ 2566662654 LaneMarkQualityOnTheRightSide 0 "no lane marks detected" 1 "low reliablity of detected lane marks" 2 "good reliablity of detected lane marks" 3 "perfect recognition of lane marks" 6 "error" 7 "not available or not installed" ;
VAL_ 2566662654 RightLaneMarkerType 0 "Processing or not identified" 1 "Solid" 2 "Road edge" 3 "Dashed" 4 "Double lane marker" 5 "Raised lane marker" 14 "Error" 15 "Not available" ;
VAL_ 2566662654 LeftLaneMarkerType 0 "Processing or not identified" 1 "Solid" 2 "Road edge" 3 "Dashed" 4 "Double lane marker" 5 "Raised lane marker" 14 "Error" 15 "Not available" ;
VAL_ 2566662910 OprtrIndcmntTmeToTrqDerateLvl1 64256 "Operator inducement is not active" ;
VAL_ 2566662910 OperatorIndcmntTorqueDerateLvl2 0 "No operator inducement is active." ;
VAL_ 2566662910 OprtrIndcmntTmeToTrqDerateLvl2 64256 "Operator inducement is not active or second level of derate does not exist" ;
VAL_ 2566662910 OprtrIndcmntTmeToFinalIndcmntAct 64256 "Operator inducement is not active" ;
VAL_ 2566663166 EngExternalIdleRequestFeedback 0 "No Idle Alteration Active" 1 "Idle Alteration Active" 2 "Error" 3 "Not available" ;
VAL_ 2566663422 TractorBrkCaliperLnngClrAxl1Lft 0 "Caliper lining clearance is adequate" 1 "Caliper lining clearance is low" 2 "Error" 3 "Not available / not applicable" ;
VAL_ 2566663422 TractorBrkCaliperLnngClrAxl1Rght 0 "Caliper lining clearance is adequate" 1 "Caliper lining clearance is low" 2 "Error" 3 "Not available / not applicable" ;
VAL_ 2566663422 TractorBrkCaliperLnngClrAxl2Lft 0 "Caliper lining clearance is adequate" 1 "Caliper lining clearance is low" 2 "Error" 3 "Not available / not applicable" ;
VAL_ 2566663422 TractorBrkCaliperLnngClrAxl2Rght 0 "Caliper lining clearance is adequate" 1 "Caliper lining clearance is low" 2 "Error" 3 "Not available / not applicable" ;
VAL_ 2566663422 TractorBrkCaliperLnngClrAxl3Lft 0 "Caliper lining clearance is adequate" 1 "Caliper lining clearance is low" 2 "Error" 3 "Not available / not applicable" ;
VAL_ 2566663422 TractorBrkCaliperLnngClrAxl3Rght 0 "Caliper lining clearance is adequate" 1 "Caliper lining clearance is low" 2 "Error" 3 "Not available / not applicable" ;
VAL_ 2566663422 TractorBrkCaliperLnngClrAxl4Lft 0 "Caliper lining clearance is adequate" 1 "Caliper lining clearance is low" 2 "Error" 3 "Not available / not applicable" ;
VAL_ 2566663422 TractorBrkCaliperLnngClrAxl4Rght 0 "Caliper lining clearance is adequate" 1 "Caliper lining clearance is low" 2 "Error" 3 "Not available / not applicable" ;
VAL_ 2566663422 TractorBrkCaliperLnngClrAxl5Lft 0 "Caliper lining clearance is adequate" 1 "Caliper lining clearance is low" 2 "Error" 3 "Not available / not applicable" ;
VAL_ 2566663422 TractorBrkCaliperLnngClrAxl5Rght 0 "Caliper lining clearance is adequate" 1 "Caliper lining clearance is low" 2 "Error" 3 "Not available / not applicable" ;
VAL_ 2566663422 TrlrBrkCaliperLnngClearAxl1Lft 0 "Caliper lining clearance is adequate" 1 "Caliper lining clearance is low" 2 "Error" 3 "Not available / not applicable" ;
VAL_ 2566663422 TrlrBrkCaliperLnngClearAxl1Rght 0 "Caliper lining clearance is adequate" 1 "Caliper lining clearance is low" 2 "Error" 3 "Not available / not applicable" ;
VAL_ 2566663422 TrlrBrkCaliperLnngClearAxl2Lft 0 "Caliper lining clearance is adequate" 1 "Caliper lining clearance is low" 2 "Error" 3 "Not available / not applicable" ;
VAL_ 2566663422 TrlrBrkCaliperLnngClearAxl2Rght 0 "Caliper lining clearance is adequate" 1 "Caliper lining clearance is low" 2 "Error" 3 "Not available / not applicable" ;
VAL_ 2566663422 TrlrBrkCaliperLnngClearAxl3Lft 0 "Caliper lining clearance is adequate" 1 "Caliper lining clearance is low" 2 "Error" 3 "Not available / not applicable" ;
VAL_ 2566663422 TrlrBrkCaliperLnngClearAxl3Rght 0 "Caliper lining clearance is adequate" 1 "Caliper lining clearance is low" 2 "Error" 3 "Not available / not applicable" ;
VAL_ 2566663422 TrlrBrkCaliperLnngClearAxl4Lft 0 "Caliper lining clearance is adequate" 1 "Caliper lining clearance is low" 2 "Error" 3 "Not available / not applicable" ;
VAL_ 2566663422 TrlrBrkCaliperLnngClearAxl4Rght 0 "Caliper lining clearance is adequate" 1 "Caliper lining clearance is low" 2 "Error" 3 "Not available / not applicable" ;
VAL_ 2566663422 TrlrBrkCaliperLnngClearAxl5Lft 0 "Caliper lining clearance is adequate" 1 "Caliper lining clearance is low" 2 "Error" 3 "Not available / not applicable" ;
VAL_ 2566663422 TrlrBrkCaliperLnngClearAxl5Rght 0 "Caliper lining clearance is adequate" 1 "Caliper lining clearance is low" 2 "Error" 3 "Not available / not applicable" ;
VAL_ 2566663934 EngTurboCmprBffActr1MtrCurDisabl 0 "Do Not Disable" 1 "Disable" 2 "Reserved" 3 "Don't Care/Take No Action" ;
VAL_ 2566663934 EngTurboWstgtActr1MtrCurrDisabl 0 "Do Not Disable" 1 "Disable" 2 "Reserved" 3 "Don't Care/Take No Action" ;
VAL_ 2566663934 EngCylHeadBypssActr1MtrCurDisabl 0 "Do Not Disable" 1 "Disable" 2 "Reserved" 3 "Don't Care/Take No Action" ;
VAL_ 2566663934 EngThrottleValve1MotorCurrDisabl 0 "Do Not Disable" 1 "Disable" 2 "Reserved" 3 "Don't Care/Take No Action" ;
VAL_ 2566663934 EngTurboCmprBypssActr1MtrCurDsbl 0 "Do Not Disable" 1 "Disable" 2 "Reserved" 3 "Don't Care/Take No Action" ;
VAL_ 2566663934 EngTurboCmprBypssActr2MtrCurDsbl 0 "Do Not Disable" 1 "Disable" 2 "Reserved" 3 "Don't Care/Take No Action" ;
VAL_ 2566663934 EngTurboWstgtActr2MtrCurrDisabl 0 "Do Not Disable" 1 "Disable" 2 "Reserved" 3 "Don't Care/Take No Action" ;
VAL_ 2633773310 SCROperatorIndcmntOverrideMode 0 "Not Available" 1 "Available" 2 "Active" 3 "Active Extended" 4 "Expired" 7 "Not Available" ;
VAL_ 2633773310 SCROprtrIndcOvrrdRenewalRequired 0 "Not Required" 1 "Required" 2 "Error" 3 "Not Available" ;
VAL_ 2566664702 AftrtrtmntThermalMangmntStatus 0 "Not active" 1 "Active" 2 "Reserved for SAE assignment" 3 "Not available" ;
VAL_ 2566664702 AftActRegenInhbtdDTLowExhstPress 0 "Not Inhibited" 1 "Inhibited" 2 "Reserved for SAE assignment" 3 "Not Available" ;
VAL_ 2566664702 AftrtrtmntEngSpeedIncreaseRq 0 "No Request" 1 "Aftertreatment Engine Speed Control Desired" 2 "Urgent Aftertreatment Engine Speed Control Desired" 3 "Not Available" ;
VAL_ 2566664702 AftertreatmentEngineLoadRequest 0 "No Request" 1 "Aftertreatment Engine Load Desired" 2 "Urgent Aftertreatment Engine Load Desired" 3 "Not Available" ;
VAL_ 2566664702 AftrtrtmntDslExhstFldHtrCircBrkr 0 "Off" 1 "On" 2 "Error" 3 "Not available" ;
VAL_ 2566664702 DslExhstFldQltyMalfctEvPeriodAct 0 "Not active" 1 "Active" 2 "SAE reserved" 3 "Not supported" ;
VAL_ 2566664702 AftrtrtmntDslExhstFldTankVolume 0 "Empty" 100 "Full" 251 "Conditions are not acceptable for a valid measurement." ;
VAL_ 2499556094 Aft1PrtcltSnsrHtrHiSdeDrvPrlmFMI 31 "no failure has been detected or parameter is not supported" ;
VAL_ 2499556094 Aft1PrtcltSnsrHtrHiSdeDrvDiagSt 0 "Tests monitored continuously" 1 "Tests supported but not completed this power cycle." 7 "Not Available." ;
VAL_ 2499556094 Aft1PrtcltSnsrHtrLoSdeDrvPrlmFMI 31 "no failure has been detected or parameter is not supported" ;
VAL_ 2499556094 Aft1PrtcltSnsrHtrLoSdeDrvDiagSt 0 "Tests monitored continuously." 1 "Tests supported but not completed this power cycle." 7 "Not Available." ;
VAL_ 2499556094 Aft1PrtcltSnsrInptPrelimFMI 31 "no failure has been detected or parameter is not supported" ;
VAL_ 2499556094 Aft1PrtcltSnsrInptDiagStat 0 "Tests monitored continuously." 1 "Tests supported but not completed this power cycle." 7 "Not Available." ;
VAL_ 2499556094 Aft1PrtcltSnsrPwrSuppPrelimFMI 31 "no failure has been detected or parameter is not supported" ;
VAL_ 2499556094 Aft1PrtcltSnsrPwrSuppDiagStat 0 "Tests monitored continuously." 1 "Tests supported but not completed this power cycle." 7 "Not Available." ;
VAL_ 2499556094 Aft1PrtcltSnsrHtrPwrSuppPrlmFMI 31 "no failure has been detected or parameter is not supported" ;
VAL_ 2499556094 Aft1PrtcltSnsrHtrPwrSuppDiagStat 0 "Tests monitored continuously." 1 "Tests supported but not completed this power cycle." 7 "Not Available." ;
VAL_ 2499557118 InertGasSupplyValvePosition 0 "valve fully closed" 100 "valve fully open" ;
VAL_ 2566668030 HeatExchangerDebrisPurgeStatus 0 "Inactive" 1 "Active" 2 "SAE reserved" 3 "Not available" ;
VAL_ 2566668030 HeatExchangerDebrisPurgeApprchng 0 "Not approaching" 1 "Approaching" 2 "SAE reserved" 3 "Not available" ;
VAL_ 2566669310 TireLocation 255 "Not available" ;
VAL_ 2566669822 TireLocation 255 "Not available" ;
VAL_ 2566670078 TireNumber 255 "SPN is not used" ;
VAL_ 2566670078 TireLocation 255 "Not available" ;
VAL_ 2566670334 Axle1MonitoredTireCount 15 "Not Available" ;
VAL_ 2566670334 Axle2MonitoredTireCount 15 "Not Available" ;
VAL_ 2566670334 Axle3MonitoredTireCount 15 "Not Available" ;
VAL_ 2566670334 Axle4MonitoredTireCount 15 "Not Available" ;
VAL_ 2566670334 Axle5MonitoredTireCount 15 "Not Available" ;
VAL_ 2566670334 Axle6MonitoredTireCount 15 "Not Available" ;
VAL_ 2566670334 Axle7MonitoredTireCount 15 "Not Available" ;
VAL_ 2566670334 Axle8MonitoredTireCount 15 "Not Available" ;
VAL_ 2566670334 Axle9MonitoredTireCount 15 "Not Available" ;
VAL_ 2566670334 Axle10MonitoredTireCount 15 "Not Available" ;
VAL_ 2566670334 Axle11MonitoredTireCount 15 "Not Available" ;
VAL_ 2566670334 Axle12MonitoredTireCount 15 "Not Available" ;
VAL_ 2566671102 SCRSystemCleaningLampCommand 0 "Off" 1 "On - solid" 2 "reserved for SAE assignment " 3 "reserved for SAE assignment" 4 "On - fast blink (1 HZ)" 5 "reserved for SAE assignment" 6 "reserved for SAE assignment" 7 "not available" ;
VAL_ 2566671102 SCRSystemCleaningStatus 0 "not active" 1 "active" 2 "SCR system cleaning is needed" 3 "not available" ;
VAL_ 2566671102 SCRSystemCleaningInhibitedStatus 0 "Not Inhibited" 1 "Inhibited" 2 "Reserved for SAE assignment" 3 "Not Available" ;
VAL_ 2566671102 SCRSystemCleaningInhbtdDTInhbtSw 0 "Not Inhibited" 1 "Inhibited" 2 "Reserved for SAE assignment" 3 "Not Available" ;
VAL_ 2566671102 SCRSysCleaningInhDTCltchDiseng 0 "Not Inhibited" 1 "Inhibited" 2 "Reserved for SAE assignment" 3 "Not Available" ;
VAL_ 2566671102 SCRSysCleaningInhbtdDTSrvcBrkAct 0 "Not Inhibited" 1 "Inhibited" 2 "Reserved for SAE assignment" 3 "Not Available" ;
VAL_ 2566671102 SCRSystemCleaningInhbtdDTPTOActv 0 "Not Inhibited" 1 "Inhibited" 2 "Reserved for SAE assignment" 3 "Not Available" ;
VAL_ 2566671102 SCRSysCleaningInhDTAcclPdlOffIdl 0 "Not Inhibited" 1 "Inhibited" 2 "Reserved for SAE assignment" 3 "Not Available" ;
VAL_ 2566671102 SCRSysCleaningInhbtdDTOutOfNtrl 0 "Not Inhibited" 1 "Inhibited" 2 "Reserved for SAE assignment" 3 "Not Available" ;
VAL_ 2566671102 SCRSysClnInhDTVhclSpdAbvAllwdSpd 0 "Not Inhibited" 1 "Inhibited" 2 "Reserved for SAE assignment" 3 "Not Available" ;
VAL_ 2566671102 SCRSysCleaningInhDTPrkBrkNotSet 0 "Not Inhibited" 1 "Inhibited" 2 "Reserved for SAE assignment" 3 "Not Available" ;
VAL_ 2566671102 SCRSysCleaningInhDTLowExhstTemp 0 "Not Inhibited" 1 "Inhibited" 2 "Reserved for SAE assignment" 3 "Not Available" ;
VAL_ 2566671102 SCRSysCleaningInhDTSysFaultAct 0 "Not Inhibited" 1 "Inhibited" 2 "Reserved for SAE assignment" 3 "Not Available" ;
VAL_ 2566671102 SCRSysCleaningInhbtdDTSysTimeout 0 "Not Inhibited" 1 "Inhibited" 2 "Reserved for SAE assignment" 3 "Not Available" ;
VAL_ 2566671102 SCRSysCleaningInhDTTmprySysLckt 0 "Not Inhibited" 1 "Inhibited" 2 "Reserved for SAE assignment" 3 "Not Available" ;
VAL_ 2566671102 SCRSysCleaningInhDTPrmntSysLckt 0 "Not Inhibited" 1 "Inhibited" 2 "Reserved for SAE assignment" 3 "Not Available" ;
VAL_ 2566671102 SCRSysCleangInhDTEngNotWarmedUp 0 "Not Inhibited" 1 "Inhibited" 2 "Reserved for SAE assignment" 3 "Not Available" ;
VAL_ 2566671102 SCRSysCleangInhDTVehicleSpeed 0 "Not Inhibited" 1 "Inhibited" 2 "Reserved for SAE assignment" 3 "Not Available" ;
VAL_ 2566671102 SCRSystemCleaningAutoInitConf 0 "not enabled" 1 "enabled" 2 "reserved for SAE assignment" 3 "not available" ;
VAL_ 2566671102 SCRSystemCleaningForcedStatus 0 "Not Active" 1 "Active - Forced by Switch (See SPN 3696)" 2 "Active - Forced by Service Tool " 3 "Reserved for SAE Assignment" 4 "Reserved for SAE Assignment" 5 "Reserved for SAE Assignment" 6 "Reserved for SAE Assignment" 7 "not available" ;
VAL_ 2566671102 Aft1SCRSysCondtnsNotMetActCleang 0 "SCR System Cleaning not Inhibited" 1 "SCR System Cleaning Inhibited" 2 "Reserved for SAE Assignment" 3 "Not available" ;
VAL_ 2566671614 SCROperatorIndcmntOverrideEnbl 0 "Override not allowed" 1 "Override allowed" 2 "SAE Reserved" 3 "Not available" ;
VAL_ 2566672382 PayloadWeightSensor1Status 0 "Sensor fully functional" 1 "Sensor degraded" 2 "Error (Sensor failed)" 3 "Not available" ;
VAL_ 2566672382 PayloadWeightSensor2Status 0 "Sensor fully functional" 1 "Sensor degraded" 2 "Error (Sensor failed)" 3 "Not available" ;
VAL_ 2566672382 PayloadWeightSensor3Status 0 "Sensor fully functional" 1 "Sensor degraded" 2 "Error (Sensor failed)" 3 "Not available" ;
VAL_ 2566672382 PayloadWeightSensor4Status 0 "Sensor fully functional" 1 "Sensor degraded" 2 "Error (Sensor failed)" 3 "Not available" ;
VAL_ 2566672382 PayloadWeightSensor5Status 0 "Sensor fully functional" 1 "Sensor degraded" 2 "Error (Sensor failed)" 3 "Not available" ;
VAL_ 2566672382 PayloadWeightSensor6Status 0 "Sensor fully functional" 1 "Sensor degraded" 2 "Error (Sensor failed)" 3 "Not available" ;
VAL_ 2566672382 PayloadWeightSensor7Status 0 "Sensor fully functional" 1 "Sensor degraded" 2 "Error (Sensor failed)" 3 "Not available" ;
VAL_ 2566672382 PayloadWeightSensor8Status 0 "Sensor fully functional" 1 "Sensor degraded" 2 "Error (Sensor failed)" 3 "Not available" ;
VAL_ 2566672638 HaulModeStatus 0 "Not in Haul Mode" 1 "Loading" 2 "Approaching Loaded" 3 "Loaded" 4 "Unloading" 5 "Unloaded" 14 "Error" 15 "Not Available" ;
VAL_ 2566672638 PayloadDeliveryTransactionStatus 0 "Transaction Not In Progress" 1 "Transaction In Progress" 2 "Transaction Complete" 14 "Error" 15 "Not Available" ;
VAL_ 2365346302 LiftAxle1Status 0 "Down" 1 "Unloading" 2 "Lifting" 3 "Up" 4 "Lowering" 5 "Loading" 6 "Error" 7 "Not available" ;
VAL_ 2365346302 LiftAxle2Status 0 "Down" 1 "Unloading" 2 "Lifting" 3 "Up" 4 "Lowering" 5 "Loading" 6 "Error" 7 "Not available" ;
VAL_ 2633782014 BinWeighingErrorStatus 0 "No error" 1 "Bad lift cycle" 2 "Weighing error" 3 "Weighing error" 7 "Not available / not applicable" ;
VAL_ 2365348350 EngineUnloadStatus 0 "Not Requested" 1 "Requested" 2 "Error" 3 "Not Available" ;
VAL_ 2365348350 EngineLoadShareStatus 0 "Offline" 1 "Master" 2 "Slave" 3 "Loading" 4 "Unloading" 14 "Error" 15 "Unavailable" ;
VAL_ 2566687742 Aft1PrticulateSnsrDetctnStat 0 "Initialization for particulate matter detection" 1 "Waiting for dew point" 2 "Particulate matter detection" 3 "Heater is active for particulate sensor regeneration" 4 "Cooling after particulate sensor regeneration" 5 "Heater diagnostics test" 6 "Relearning particulate sensor resistance after particulate sensor regeneration" 7 "Sensor regeneration did not complete due to system parameters out of range" 8 "Halt particulate matter detection" 15 "Not supported" ;
VAL_ 2566687742 Aft1PrticulateSnsrPwrSupply 0 "Off" 1 "On" 2 "Error" 3 "Unavailable" ;
VAL_ 2566687998 Aftrtrtmnt1PrticulateSnsrHtrStat 0 "Heater is in closed loop control" 1 "Heater is being held at a specified level" 2 "Heater is in ramp up mode" 3 "Heater is off" ;
VAL_ 2566687998 Aft1PrticulateSnsrRegenStatus 0 "Regeneration has not completed during this power cycle" 1 "Regeneration was successful" 2 "Regeneration failed" 3 "Not available" ;
VAL_ 2566687998 Aft1PrticulateSnsrRegenState 0 "Regeneration is not active" 1 "Regneration is active and has been initiated by request via SPN 6783" 2 "Regeneration is active and has been initiated because of sensor conditions" 3 "Regeneration is active and has been initiated due to time based conditions" 15 "Not Available" ;
VAL_ 2566690046 AftDslExhstFldDosCldownCoThsCycl 0 "Not complete" 1 "Complete" 2 "Error" 3 "Not Supported" ;
VAL_ 2566690046 AftDslExhstFldDosCldownCoLstCycl 0 "Not complete" 1 "Complete" 2 "Error" 3 "Not Supported" ;
VAL_ 2566690046 AftDslExhstFldDosPrgeCompThsCycl 0 "Not complete" 1 "Complete" 2 "Error" 3 "Not Supported" ;
VAL_ 2566690046 AftDslExhstFldDosPrgeCompLstCycl 0 "Not complete" 1 "Complete" 2 "Error" 3 "Not Supported" ;
VAL_ 2566690046 AfterRunCompleteThisCycle 0 "Not complete" 1 "Complete" 2 "Error" 3 "Not Supported" ;
VAL_ 2566690814 SteeringModeSwitch 0 "2 Wheel Steer Mode" 1 "Circle Steer Mode" 3 "Crab Steer Mode" 6 "Error" 7 "Not Available" ;
VAL_ 2566690814 FrontSteeringAxleCenteredStatus 0 "Front Axle Centered" 1 "Front Axle Not Centered" 2 "Error" 3 "Not Available" ;
VAL_ 2566690814 RearSteeringAxleCenteredStatus 0 "Rear Axle Centered" 1 "Rear Axle Not Centered" 2 "Error" 3 "Not Available" ;
VAL_ 2566690814 WheelSteerActuatorState 0 "2 Wheel Steer actuator inactive" 1 "2 Wheel Steer actuator active" 2 "Error" 3 "Not Available" ;
VAL_ 2566690814 WheelSteerActuatorState 0 "4 Wheel Steer actuator inactive" 1 "4 Wheel Steer actuator active" 2 "Error" 3 "Not Available" ;
VAL_ 2566690814 CircleSteerModeActuatorState 0 "Circle Steer Mode actuator inactive" 1 "Circle Steer Mode actuator active" 2 "Error" 3 "Not Available" ;
VAL_ 2566690814 CrabSteerModeActuatorState 0 "Crab Steer Mode actuator inactive" 1 "Crab Steer Mode actuator active" 2 "Error" 3 "Not Available" ;
VAL_ 2499582206 SoftTopSpeedLimitActive 0 "Soft Top Speed Limit is Inactive" 1 "Soft Top Speed Limit is Active" 2 "Reserved" 3 "Not Available" ;
VAL_ 2499582206 SoftTopRatioLimitExceeded 0 "Soft top ratio limit has not been exceeded" 1 "Soft top ratio limit has been exceeded" 2 "Reserved" 3 "Not Available" ;
VAL_ 2566691582 Joystick3Lamp1Status 0 "Off" 1 "On" 2 "Flashing" 3 "Not available" ;
VAL_ 2566691582 Joystick3Lamp2Status 0 "Off" 1 "On" 2 "Flashing" 3 "Not available" ;
VAL_ 2566691582 Joystick3Lamp3Status 0 "Off" 1 "On" 2 "Flashing" 3 "Not available" ;
VAL_ 2566691582 Joystick3Lamp4Status 0 "Off" 1 "On" 2 "Flashing" 3 "Not available" ;
VAL_ 2566691582 Joystick3Lamp5Status 0 "Off" 1 "On" 2 "Flashing" 3 "Not available" ;
VAL_ 2566691582 Joystick3Lamp6Status 0 "Off" 1 "On" 2 "Flashing" 3 "Not available" ;
VAL_ 2566691582 Joystick3Lamp7Status 0 "Off" 1 "On" 2 "Flashing" 3 "Not available" ;
VAL_ 2566691582 Joystick3Lamp8Status 0 "Off" 1 "On" 2 "Flashing" 3 "Not available" ;
VAL_ 2566691582 Joystick3Lamp9Status 0 "Off" 1 "On" 2 "Flashing" 3 "Not available" ;
VAL_ 2566691582 Joystick3Lamp10Status 0 "Off" 1 "On" 2 "Flashing" 3 "Not available" ;
VAL_ 2566691838 Joystick2Lamp1Status 0 "Off" 1 "On" 2 "Flashing" 3 "Not available" ;
VAL_ 2566691838 Joystick2Lamp2Status 0 "Off" 1 "On" 2 "Flashing" 3 "Not available" ;
VAL_ 2566691838 Joystick2Lamp3Status 0 "Off" 1 "On" 2 "Flashing" 3 "Not available" ;
VAL_ 2566691838 Joystick2Lamp4Status 0 "Off" 1 "On" 2 "Flashing" 3 "Not available" ;
VAL_ 2566691838 Joystick2Lamp5Status 0 "Off" 1 "On" 2 "Flashing" 3 "Not available" ;
VAL_ 2566691838 Joystick2Lamp6Status 0 "Off" 1 "On" 2 "Flashing" 3 "Not available" ;
VAL_ 2566691838 Joystick2Lamp7Status 0 "Off" 1 "On" 2 "Flashing" 3 "Not available" ;
VAL_ 2566691838 Joystick2Lamp8Status 0 "Off" 1 "On" 2 "Flashing" 3 "Not available" ;
VAL_ 2566691838 Joystick2Lamp9Status 0 "Off" 1 "On" 2 "Flashing" 3 "Not available" ;
VAL_ 2566691838 Joystick2Lamp10Status 0 "Off" 1 "On" 2 "Flashing" 3 "Not available" ;
VAL_ 2566692094 Joystick1Lamp1Status 1 "On" 2 "Flashing" 3 "Not available" ;
VAL_ 2566692094 Joystick1Lamp2Status 0 "Off" 1 "On" 2 "Flashing" 3 "Not available" ;
VAL_ 2566692094 Joystick1Lamp3Status 0 "Off" 1 "On" 2 "Flashing" 3 "Not available" ;
VAL_ 2566692094 Joystick1Lamp4Status 1 "On" 2 "Flashing" 3 "Not available" ;
VAL_ 2566692094 Joystick1Lamp5Status 0 "Off" 1 "On" 2 "Flashing" 3 "Not available" ;
VAL_ 2566692094 Joystick1Lamp6Status 0 "Off" 1 "On" 2 "Flashing" 3 "Not available" ;
VAL_ 2566692094 Joystick1Lamp7Status 0 "Off" 1 "On" 2 "Flashing" 3 "Not available" ;
VAL_ 2566692094 Joystick1Lamp8Status 0 "Off" 1 "On" 2 "Flashing" 3 "Not available" ;
VAL_ 2566692094 Joystick1Lamp9Status 0 "Off" 1 "On" 2 "Flashing" 3 "Not available" ;
VAL_ 2566692094 Joystick1Lamp10Status 0 "Off" 1 "On" 2 "Flashing" 3 "Not available" ;
VAL_ 2499583486 EngineTimingActr1PositionCommand 0 "Reserved" 1 "Diesel Mode Position" 2 "Diesel Part Load Position" 3 "Gas Mode Position" 4 "Diesel Part Load / Gas Mode Position" 7 "Not Available" ;
VAL_ 2499583486 EngineTimingActr2PositionCommand 0 "Reserved" 1 "Diesel Mode Position" 2 "Diesel Part Load Position" 3 "Gas Mode Position" 4 "Diesel Part Load / Gas Mode Position" 7 "Not Available" ;
VAL_ 2499583742 EngineTimingActuator1 0 "Unknown Position" 1 "Diesel Mode Position" 2 "Diesel Part Load Position" 3 "Gas Mode Position" 4 "Diesel Part Load / Gas Mode Position" 7 "Not Available" ;
VAL_ 2499583742 EngineTimingActuator2 0 "Unknown Position" 1 "Diesel Mode Position" 2 "Diesel Part Load Position" 3 "Gas Mode Position" 4 "Diesel Part Load / Gas Mode Position" 7 "Not Available" ;
VAL_ 2499583742 EngTimingActr1RequestedPosition 0 "Position Not Requested" 1 "Diesel Mode Position" 2 "Diesel Part Load Position" 3 "Gas Mode Position" 4 "Diesel Part Load / Gas Mode Position" 7 "Not Available" ;
VAL_ 2499583742 EngTimingActr2RequestedPosition 0 "Position Not Requested" 1 "Diesel Mode Position" 2 "Diesel Part Load Position" 3 "Gas Mode Position" 4 "Diesel Part Load / Gas Mode Position" 7 "Not Available" ;
VAL_ 2566692862 DisplayRemainPowered 0 "OK to Shutoff" 1 "Remain Powered" 2 "Reserved" 3 "Don't care" ;
VAL_ 2566697470 EngineIgnitionCtrlModule1State 0 "Disabled (by user)" 1 "Shutdown (due to alarm)" 2 "Stalled (waiting for timing signals)" 3 "Firing Ignition in Test Mode" 4 "Firing Ignition in Normal Mode" 5 "Reserved" 6 "Error" 7 "Not available" ;
VAL_ 2566697470 EngineIgnitionCtrlModule2State 0 "Disabled (by user)" 1 "Shutdown (due to alarm)" 2 "Stalled (waiting for timing signals)" 3 "Firing Ignition in Test Mode" 4 "Firing Ignition in Normal Mode" 5 "Reserved" 6 "Error" 7 "Not available" ;
